VERSION "HNNBNNNYNNNNNNNNNNNNNNNNNNNNNNNNNNNNNNNNNN/4/%%%/4/'%**4NNN///"

NS_ :

BS_:

BU_: AWC BAP_Tester BMC_MLBevo BMS_MV BMS_NV DCDC_800V_PAG DCDC_HV DCDC_HV_02 DCDC_IHEV FCU_MLBevo_FCEV Gateway Gateway_PAG Ladegeraet_2 Ladegeraet_Konzern LE1 LE2 LE2_3_MLBevo_LB LE_MLBevo LE_MLBevo_LB Sub_Gateway TME

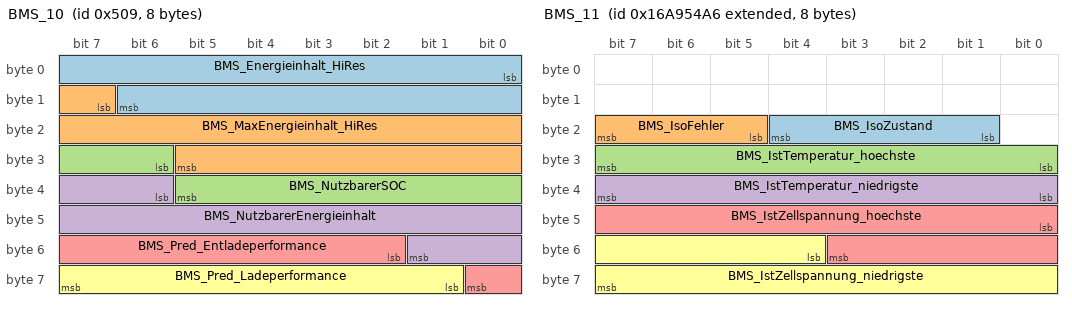
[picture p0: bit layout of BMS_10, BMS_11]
BO_ 1289 BMS_10: 8 BMC_MLBevo
 SG_ BMS_Energieinhalt_HiRes : 0|15@1+ (4,0) [0|131060] "Unit_WattHour"  Gateway,Gateway_PAG,Sub_Gateway
 SG_ BMS_MaxEnergieinhalt_HiRes : 15|15@1+ (4,0) [0|131060] "Unit_WattHour"  Gateway,Gateway_PAG,Sub_Gateway
 SG_ BMS_NutzbarerSOC : 30|8@1+ (0.5,0) [0|100] "Unit_PerCent"  Gateway,Gateway_PAG,Ladegeraet_Konzern,Sub_Gateway,TME
 SG_ BMS_NutzbarerEnergieinhalt : 38|12@1+ (25,0) [0|102325] "Unit_WattHour"  Gateway,Gateway_PAG,Sub_Gateway
 SG_ BMS_Pred_Entladeperformance : 50|7@1+ (1,0) [0|100] "Unit_PerCent"  Gateway,Gateway_PAG,Sub_Gateway
 SG_ BMS_Pred_Ladeperformance : 57|7@1+ (1,0) [0|100] "Unit_PerCent"  Gateway,Gateway_PAG,Sub_Gateway

BO_ 2527679654 BMS_11: 8 BMC_MLBevo
 SG_ BMS_IsoZustand : 17|4@1+ (1,0) [0|15] ""  Gateway,Gateway_PAG,Sub_Gateway
 SG_ BMS_IsoFehler : 21|3@1+ (1,0) [0|7] ""  Gateway,Gateway_PAG,Sub_Gateway
 SG_ BMS_IstTemperatur_hoechste : 24|8@1+ (0.5,-40) [-40|86] "Unit_DegreCelsi"  Gateway,Gateway_PAG,Ladegeraet_Konzern,Sub_Gateway,TME
 SG_ BMS_IstTemperatur_niedrigste : 32|8@1+ (0.5,-40) [-40|86] "Unit_DegreCelsi"  Gateway,Gateway_PAG,Ladegeraet_Konzern,Sub_Gateway,TME
 SG_ BMS_IstZellspannung_hoechste : 40|12@1+ (1,1000) [1000|5091] "Unit_MilliVolt"  Gateway,Gateway_PAG,Ladegeraet_Konzern,Sub_Gateway
 SG_ BMS_IstZellspannung_niedrigste : 52|12@1+ (1,1000) [1000|5091] "Unit_MilliVolt"  Gateway,Gateway_PAG,Ladegeraet_Konzern,Sub_Gateway

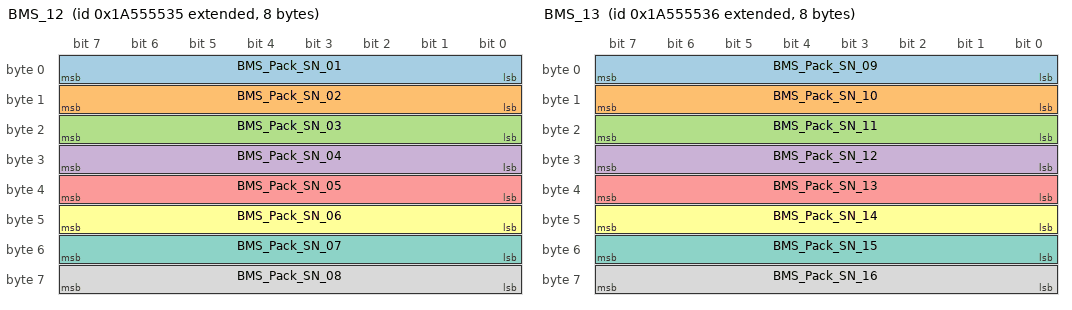
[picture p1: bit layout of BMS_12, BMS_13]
BO_ 2589283637 BMS_12: 8 BMC_MLBevo
 SG_ BMS_Pack_SN_01 : 0|8@1+ (1,0) [0|255] ""  Gateway,Gateway_PAG,Sub_Gateway
 SG_ BMS_Pack_SN_02 : 8|8@1+ (1,0) [0|255] ""  Gateway,Gateway_PAG,Sub_Gateway
 SG_ BMS_Pack_SN_03 : 16|8@1+ (1,0) [0|255] ""  Gateway,Gateway_PAG,Sub_Gateway
 SG_ BMS_Pack_SN_04 : 24|8@1+ (1,0) [0|255] ""  Gateway,Gateway_PAG,Sub_Gateway
 SG_ BMS_Pack_SN_05 : 32|8@1+ (1,0) [0|255] ""  Gateway,Gateway_PAG,Sub_Gateway
 SG_ BMS_Pack_SN_06 : 40|8@1+ (1,0) [0|255] ""  Gateway,Gateway_PAG,Sub_Gateway
 SG_ BMS_Pack_SN_07 : 48|8@1+ (1,0) [0|255] ""  Gateway,Gateway_PAG,Sub_Gateway
 SG_ BMS_Pack_SN_08 : 56|8@1+ (1,0) [0|255] ""  Gateway,Gateway_PAG,Sub_Gateway

BO_ 2589283638 BMS_13: 8 BMC_MLBevo
 SG_ BMS_Pack_SN_09 : 0|8@1+ (1,0) [0|255] ""  Gateway,Gateway_PAG,Sub_Gateway
 SG_ BMS_Pack_SN_10 : 8|8@1+ (1,0) [0|255] ""  Gateway,Gateway_PAG,Sub_Gateway
 SG_ BMS_Pack_SN_11 : 16|8@1+ (1,0) [0|255] ""  Gateway,Gateway_PAG,Sub_Gateway
 SG_ BMS_Pack_SN_12 : 24|8@1+ (1,0) [0|255] ""  Gateway,Gateway_PAG,Sub_Gateway
 SG_ BMS_Pack_SN_13 : 32|8@1+ (1,0) [0|255] ""  Gateway,Gateway_PAG,Sub_Gateway
 SG_ BMS_Pack_SN_14 : 40|8@1+ (1,0) [0|255] ""  Gateway,Gateway_PAG,Sub_Gateway
 SG_ BMS_Pack_SN_15 : 48|8@1+ (1,0) [0|255] ""  Gateway,Gateway_PAG,Sub_Gateway
 SG_ BMS_Pack_SN_16 : 56|8@1+ (1,0) [0|255] ""  Sub_Gateway

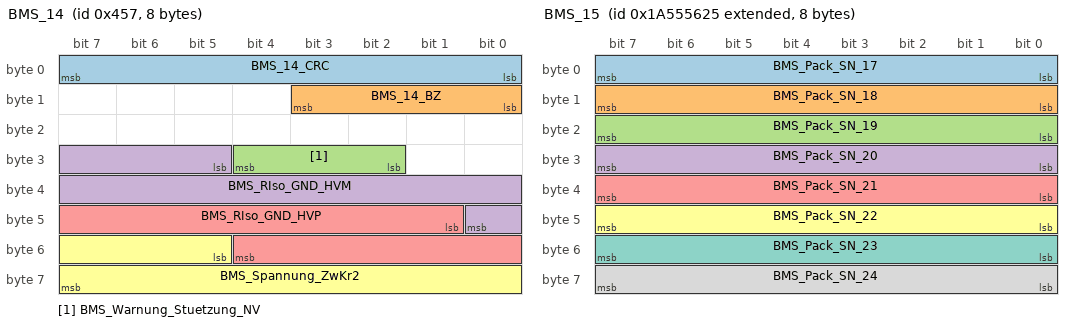
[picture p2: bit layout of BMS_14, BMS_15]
BO_ 1111 BMS_14: 8 BMC_MLBevo
 SG_ BMS_14_CRC : 0|8@1+ (1,0) [0|255] ""  Gateway,Gateway_PAG,LE2
 SG_ BMS_14_BZ : 8|4@1+ (1,0) [0|15] ""  Gateway,Gateway_PAG,LE2
 SG_ BMS_Warnung_Stuetzung_NV : 26|3@1+ (1,0) [0|7] ""  Gateway,Gateway_PAG
 SG_ BMS_RIso_GND_HVM : 29|12@1+ (5,-20465) [-20465|0] "Unit_KiloOhm"  DCDC_HV_02,Gateway,Gateway_PAG
 SG_ BMS_RIso_GND_HVP : 41|12@1+ (5,0) [0|20465] "Unit_KiloOhm"  DCDC_HV_02,Gateway,Gateway_PAG
 SG_ BMS_Spannung_ZwKr2 : 53|11@1+ (0.5,0) [0|1022.5] "Unit_Volt"  Gateway,Gateway_PAG,LE2,TME

BO_ 2589283877 BMS_15: 8 BMC_MLBevo
 SG_ BMS_Pack_SN_17 : 0|8@1+ (1,0) [0|255] ""  Sub_Gateway
 SG_ BMS_Pack_SN_18 : 8|8@1+ (1,0) [0|255] ""  Sub_Gateway
 SG_ BMS_Pack_SN_19 : 16|8@1+ (1,0) [0|255] ""  Sub_Gateway
 SG_ BMS_Pack_SN_20 : 24|8@1+ (1,0) [0|255] ""  Sub_Gateway
 SG_ BMS_Pack_SN_21 : 32|8@1+ (1,0) [0|255] ""  Sub_Gateway
 SG_ BMS_Pack_SN_22 : 40|8@1+ (1,0) [0|255] ""  Sub_Gateway
 SG_ BMS_Pack_SN_23 : 48|8@1+ (1,0) [0|255] ""  Sub_Gateway
 SG_ BMS_Pack_SN_24 : 56|8@1+ (1,0) [0|255] ""  Sub_Gateway

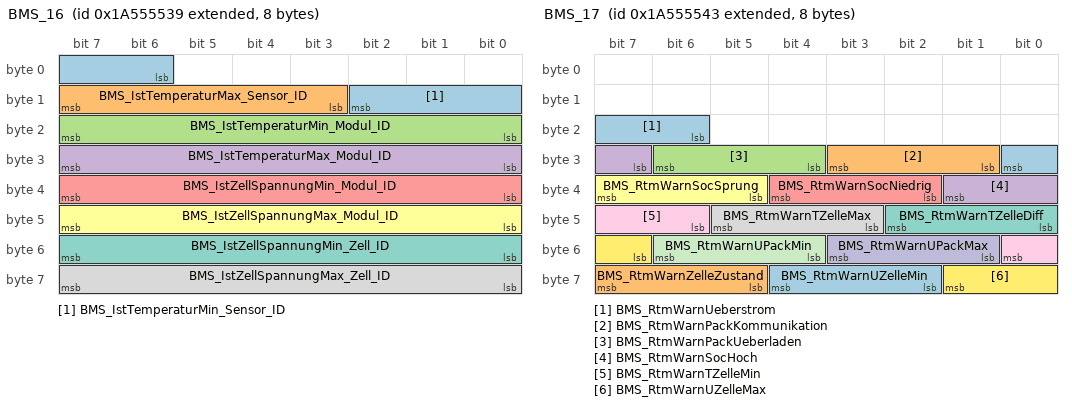
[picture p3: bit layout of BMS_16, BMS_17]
BO_ 2589283641 BMS_16: 8 BMC_MLBevo
 SG_ BMS_IstTemperaturMin_Sensor_ID : 6|5@1+ (1,0) [1|30] ""  Gateway,Gateway_PAG,Ladegeraet_Konzern,Sub_Gateway
 SG_ BMS_IstTemperaturMax_Sensor_ID : 11|5@1+ (1,0) [1|30] ""  Gateway,Gateway_PAG,Ladegeraet_Konzern,Sub_Gateway
 SG_ BMS_IstTemperaturMin_Modul_ID : 16|8@1+ (1,0) [1|254] ""  Gateway,Gateway_PAG,Ladegeraet_Konzern,Sub_Gateway
 SG_ BMS_IstTemperaturMax_Modul_ID : 24|8@1+ (1,0) [1|254] ""  Gateway,Gateway_PAG,Ladegeraet_Konzern,Sub_Gateway
 SG_ BMS_IstZellSpannungMin_Modul_ID : 32|8@1+ (1,0) [1|254] ""  Gateway,Gateway_PAG,Ladegeraet_Konzern,Sub_Gateway
 SG_ BMS_IstZellSpannungMax_Modul_ID : 40|8@1+ (1,0) [1|254] ""  Gateway,Gateway_PAG,Ladegeraet_Konzern,Sub_Gateway
 SG_ BMS_IstZellSpannungMin_Zell_ID : 48|8@1+ (1,0) [1|254] ""  Gateway,Gateway_PAG,Ladegeraet_Konzern,Sub_Gateway
 SG_ BMS_IstZellSpannungMax_Zell_ID : 56|8@1+ (1,0) [1|254] ""  Gateway,Gateway_PAG,Ladegeraet_Konzern,Sub_Gateway

BO_ 2589283651 BMS_17: 8 BMC_MLBevo
 SG_ BMS_RtmWarnUeberstrom : 22|3@1+ (1,0) [0|7] ""  Gateway,Gateway_PAG,Sub_Gateway
 SG_ BMS_RtmWarnPackKommunikation : 25|3@1+ (1,0) [0|7] ""  Gateway,Gateway_PAG,Sub_Gateway
 SG_ BMS_RtmWarnPackUeberladen : 28|3@1+ (1,0) [0|7] ""  Gateway,Gateway_PAG,Sub_Gateway
 SG_ BMS_RtmWarnSocHoch : 31|3@1+ (1,0) [0|7] ""  Gateway,Gateway_PAG,Sub_Gateway
 SG_ BMS_RtmWarnSocNiedrig : 34|3@1+ (1,0) [0|7] ""  Gateway,Gateway_PAG,Sub_Gateway
 SG_ BMS_RtmWarnSocSprung : 37|3@1+ (1,0) [0|7] ""  Gateway,Gateway_PAG,Sub_Gateway
 SG_ BMS_RtmWarnTZelleDiff : 40|3@1+ (1,0) [0|7] ""  Gateway,Gateway_PAG,Sub_Gateway
 SG_ BMS_RtmWarnTZelleMax : 43|3@1+ (1,0) [0|7] ""  Gateway,Gateway_PAG,Sub_Gateway
 SG_ BMS_RtmWarnTZelleMin : 46|3@1+ (1,0) [0|7] ""  Gateway,Gateway_PAG,Sub_Gateway
 SG_ BMS_RtmWarnUPackMax : 49|3@1+ (1,0) [0|7] ""  Gateway,Gateway_PAG,Sub_Gateway
 SG_ BMS_RtmWarnUPackMin : 52|3@1+ (1,0) [0|7] ""  Gateway,Gateway_PAG,Sub_Gateway
 SG_ BMS_RtmWarnUZelleMax : 55|3@1+ (1,0) [0|7] ""  Gateway,Gateway_PAG,Sub_Gateway
 SG_ BMS_RtmWarnUZelleMin : 58|3@1+ (1,0) [0|7] ""  Gateway,Gateway_PAG,Sub_Gateway
 SG_ BMS_RtmWarnZelleZustand : 61|3@1+ (1,0) [0|7] ""  Gateway,Gateway_PAG,Sub_Gateway

BO_ 2589283652 BMS_18: 8 BMC_MLBevo
 SG_ BMS_Energie_Entladung : 32|16@1+ (0.01,0) [0|655.33] "Unit_KiloWattHour"  Gateway,Gateway_PAG
 SG_ BMS_Energie_Ladung : 48|16@1+ (0.01,0) [0|655.33] "Unit_KiloWattHour"  Gateway,Gateway_PAG

BO_ 2589283878 BMS_19: 8 BMC_MLBevo
 SG_ BMS_Pack_SN_25 : 0|8@1+ (1,0) [0|255] ""  Sub_Gateway
 SG_ BMS_Pack_SN_26 : 8|8@1+ (1,0) [0|255] ""  Sub_Gateway

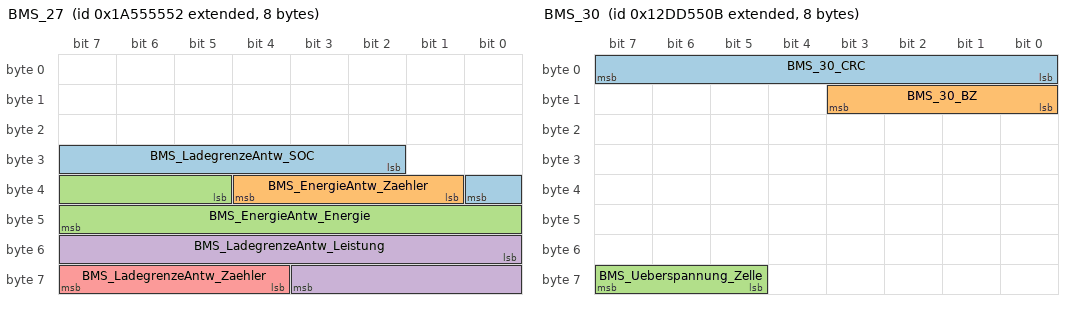
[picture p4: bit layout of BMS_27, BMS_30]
BO_ 2589283666 BMS_27: 8 BMC_MLBevo
 SG_ BMS_LadegrenzeAntw_SOC : 26|7@1+ (1,0) [0|100] "Unit_PerCent"  Gateway_PAG,Ladegeraet_Konzern
 SG_ BMS_EnergieAntw_Zaehler : 33|4@1+ (1,0) [0|13] "Unit_None"  Gateway_PAG,Ladegeraet_Konzern
 SG_ BMS_EnergieAntw_Energie : 37|11@1+ (250,0) [0|511250] "Unit_WattHour"  Gateway_PAG,Ladegeraet_Konzern
 SG_ BMS_LadegrenzeAntw_Leistung : 48|12@1+ (200,0) [0|818600] "Unit_Watt"  Gateway_PAG,Ladegeraet_Konzern
 SG_ BMS_LadegrenzeAntw_Zaehler : 60|4@1+ (1,0) [0|13] "Unit_None"  Gateway_PAG,Ladegeraet_Konzern

BO_ 2463978763 BMS_30: 8 BMC_MLBevo
 SG_ BMS_30_CRC : 0|8@1+ (1,0) [0|255] ""  Gateway,Gateway_PAG
 SG_ BMS_30_BZ : 8|4@1+ (1,0) [0|15] ""  Gateway,Gateway_PAG
 SG_ BMS_Ueberspannung_Zelle : 61|3@1+ (1,0) [0|7] ""  Gateway,Gateway_PAG

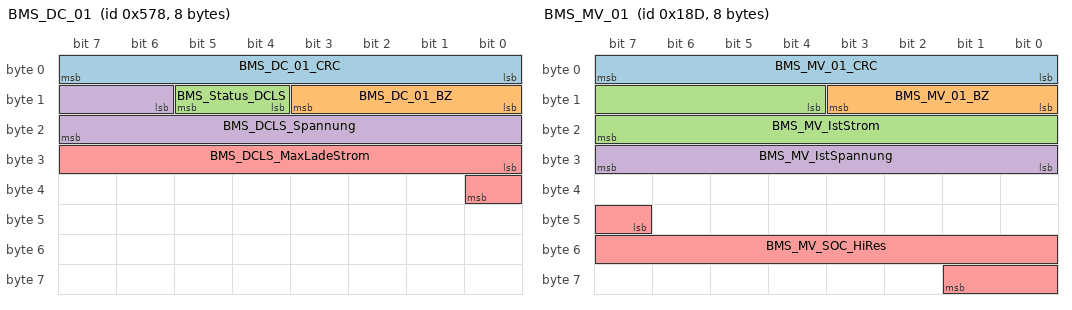
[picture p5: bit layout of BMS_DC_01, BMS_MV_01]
BO_ 1400 BMS_DC_01: 8 BMC_MLBevo
 SG_ BMS_DC_01_CRC : 0|8@1+ (1,0) [0|255] ""  Ladegeraet_Konzern
 SG_ BMS_DC_01_BZ : 8|4@1+ (1,0) [0|15] ""  Ladegeraet_Konzern
 SG_ BMS_Status_DCLS : 12|2@1+ (1,0) [0|3] ""  Ladegeraet_Konzern
 SG_ BMS_DCLS_Spannung : 14|10@1+ (1,0) [0|1021] "Unit_Volt"  Ladegeraet_Konzern
 SG_ BMS_DCLS_MaxLadeStrom : 24|9@1+ (1,0) [0|400] "Unit_Amper"  Ladegeraet_Konzern

BO_ 397 BMS_MV_01: 8 Vector__XXX
 SG_ BMS_MV_01_CRC : 0|8@1+ (1,0) [0|255] ""  Gateway,Gateway_PAG
 SG_ BMS_MV_01_BZ : 8|4@1+ (1,0) [0|15] ""  Gateway,Gateway_PAG
 SG_ BMS_MV_IstStrom : 12|12@1+ (1,-2047) [-2047|2046] "Unit_Amper"  DCDC_IHEV,Gateway,Gateway_PAG
 SG_ BMS_MV_IstSpannung : 24|8@1+ (0.25,0) [0|63.25] "Unit_Volt"  DCDC_IHEV,Gateway,Gateway_PAG
 SG_ BMS_MV_SOC_HiRes : 47|11@1+ (0.05,0) [0|100] "Unit_PerCent"  Gateway,Gateway_PAG

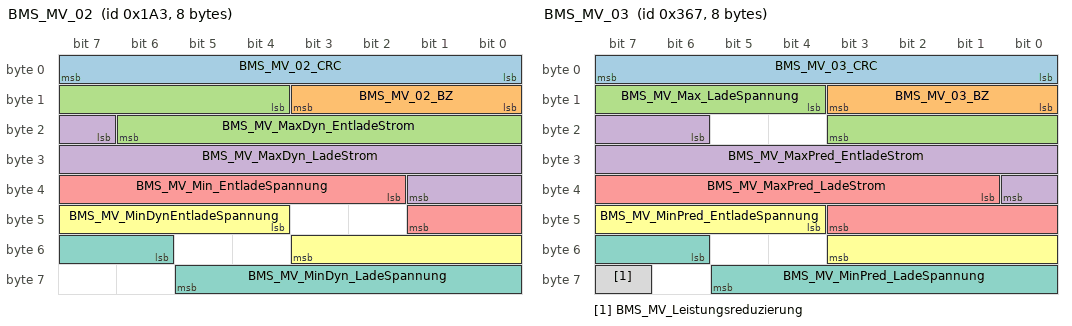
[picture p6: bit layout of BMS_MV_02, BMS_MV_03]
BO_ 419 BMS_MV_02: 8 Vector__XXX
 SG_ BMS_MV_02_CRC : 0|8@1+ (1,0) [0|255] ""  Gateway,Gateway_PAG
 SG_ BMS_MV_02_BZ : 8|4@1+ (1,0) [0|15] ""  Gateway,Gateway_PAG
 SG_ BMS_MV_MaxDyn_EntladeStrom : 12|11@1+ (1,0) [0|2045] "Unit_Amper"  DCDC_IHEV,Gateway,Gateway_PAG
 SG_ BMS_MV_MaxDyn_LadeStrom : 23|11@1+ (1,0) [0|2045] "Unit_Amper"  Gateway,Gateway_PAG
 SG_ BMS_MV_Min_EntladeSpannung : 34|8@1+ (0.25,0) [0|63.25] "Unit_Volt"  Gateway,Gateway_PAG
 SG_ BMS_MV_MinDynEntladeSpannung : 44|8@1+ (0.25,0) [0|63.25] "Unit_Volt"  Gateway,Gateway_PAG
 SG_ BMS_MV_MinDyn_LadeSpannung : 54|8@1+ (0.25,0) [0|63.25] "Unit_Volt"  Gateway,Gateway_PAG

BO_ 871 BMS_MV_03: 8 Vector__XXX
 SG_ BMS_MV_03_CRC : 0|8@1+ (1,0) [0|255] ""  Gateway,Gateway_PAG
 SG_ BMS_MV_03_BZ : 8|4@1+ (1,0) [0|15] ""  Gateway,Gateway_PAG
 SG_ BMS_MV_Max_LadeSpannung : 12|8@1+ (0.25,0) [0|63.25] "Unit_Volt"  Gateway,Gateway_PAG
 SG_ BMS_MV_MaxPred_EntladeStrom : 22|11@1+ (1,0) [0|2045] "Unit_Amper"  Gateway,Gateway_PAG
 SG_ BMS_MV_MaxPred_LadeStrom : 33|11@1+ (1,0) [0|2045] "Unit_Amper"  Gateway,Gateway_PAG
 SG_ BMS_MV_MinPred_EntladeSpannung : 44|8@1+ (0.25,0) [0|63.25] "Unit_Volt"  Gateway,Gateway_PAG
 SG_ BMS_MV_MinPred_LadeSpannung : 54|8@1+ (0.25,0) [0|63.25] "Unit_Volt"  Gateway,Gateway_PAG
 SG_ BMS_MV_Leistungsreduzierung : 63|1@1+ (1,0) [0|1] ""  Gateway,Gateway_PAG

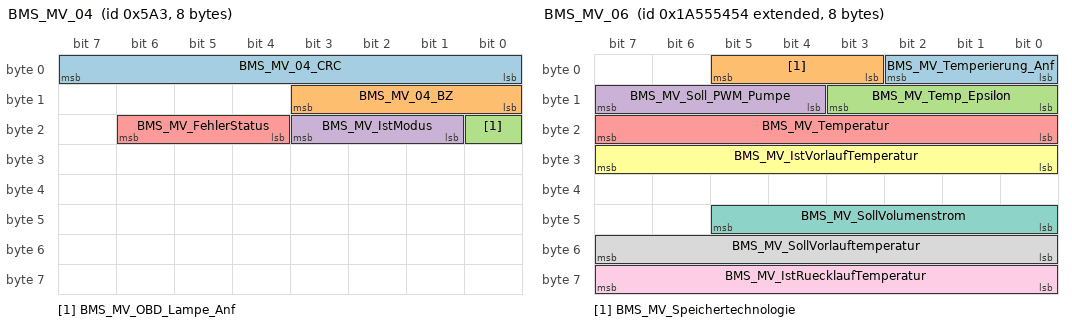
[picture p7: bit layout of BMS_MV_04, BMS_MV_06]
BO_ 1443 BMS_MV_04: 8 Vector__XXX
 SG_ BMS_MV_04_CRC : 0|8@1+ (1,0) [0|255] ""  Gateway,Gateway_PAG
 SG_ BMS_MV_04_BZ : 8|4@1+ (1,0) [0|15] ""  Gateway,Gateway_PAG
 SG_ BMS_MV_OBD_Lampe_Anf : 16|1@1+ (1,0) [0|1] ""  Gateway,Gateway_PAG
 SG_ BMS_MV_IstModus : 17|3@1+ (1,0) [0|7] ""  DCDC_IHEV,Gateway,Gateway_PAG
 SG_ BMS_MV_FehlerStatus : 20|3@1+ (1,0) [0|7] ""  Gateway,Gateway_PAG

BO_ 2589283412 BMS_MV_06: 8 Vector__XXX
 SG_ BMS_MV_Temperierung_Anf : 0|3@1+ (1,0) [0|7] ""  Gateway,Gateway_PAG,TME
 SG_ BMS_MV_Speichertechnologie : 3|3@1+ (1,0) [0|7] ""  Gateway,Gateway_PAG
 SG_ BMS_MV_Temp_Epsilon : 8|4@1+ (1,-15) [-15|0] "Unit_DegreCelsi"  Gateway,Gateway_PAG,TME
 SG_ BMS_MV_Soll_PWM_Pumpe : 12|4@1+ (10,0) [0|100] "Unit_PerCent"  Gateway,Gateway_PAG,TME
 SG_ BMS_MV_Temperatur : 16|8@1+ (0.5,-40) [-40|86.5] "Unit_DegreCelsi"  DCDC_IHEV,Gateway,Gateway_PAG,TME
 SG_ BMS_MV_IstVorlaufTemperatur : 24|8@1+ (0.5,-40) [-40|86.5] "Unit_DegreCelsi"  Gateway,Gateway_PAG,TME
 SG_ BMS_MV_SollVolumenstrom : 40|6@1+ (1,0) [0|61] ""  Gateway,Gateway_PAG,TME
 SG_ BMS_MV_SollVorlauftemperatur : 48|8@1+ (0.5,-40) [-40|86.5] "Unit_DegreCelsi"  Gateway,Gateway_PAG,TME
 SG_ BMS_MV_IstRuecklaufTemperatur : 56|8@1+ (0.5,-40) [-40|86.5] "Unit_DegreCelsi"  Gateway,Gateway_PAG,TME

BO_ 2589283608 BMS_MV_07: 8 Vector__XXX
 SG_ BMS_MV_Energieinhalt : 12|11@1+ (1,0) [0|2045] "Unit_WattHour"  Gateway,Gateway_PAG
 SG_ BMS_MV_MaxEnergieinhalt : 32|11@1+ (1,0) [0|2045] "Unit_WattHour"  Gateway,Gateway_PAG

BO_ 2589283606 BMS_MV_09: 8 Vector__XXX
 SG_ BMS_MV_SOC_Kaltstart : 43|11@1+ (0.05,0) [0|100] "Unit_PerCent"  Gateway,Gateway_PAG
 SG_ BMS_MV_max_Grenz_SOC : 54|5@1+ (1,70) [70|100] "Unit_PerCent"  Gateway,Gateway_PAG

BO_ 1021 BMS_MV_10: 8 Vector__XXX
 SG_ BMS_MV_Pred_Entladeperformance : 50|7@1+ (1,0) [0|100] "Unit_PerCent"  Gateway,Gateway_PAG
 SG_ BMS_MV_Pred_Ladeperformance : 57|7@1+ (1,0) [0|100] "Unit_PerCent"  Gateway,Gateway_PAG

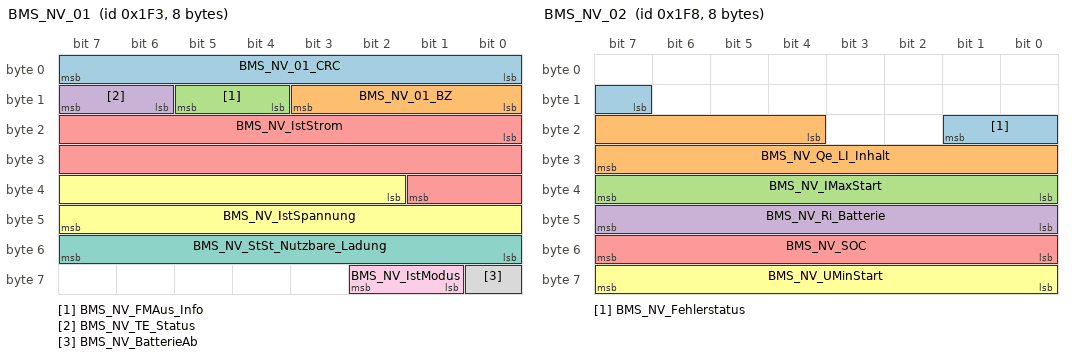
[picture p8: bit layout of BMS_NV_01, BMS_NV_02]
BO_ 499 BMS_NV_01: 8 BMS_NV
 SG_ BMS_NV_01_CRC : 0|8@1+ (1,0) [0|255] ""  Gateway,Gateway_PAG
 SG_ BMS_NV_01_BZ : 8|4@1+ (1,0) [0|15] ""  Gateway,Gateway_PAG
 SG_ BMS_NV_FMAus_Info : 12|2@1+ (1,0) [0|3] ""  Gateway,Gateway_PAG
 SG_ BMS_NV_TE_Status : 14|2@1+ (1,0) [0|3] ""  Gateway,Gateway_PAG
 SG_ BMS_NV_IstStrom : 16|18@1+ (0.01,-1300) [-1300|1300] "Unit_Amper"  Gateway,Gateway_PAG
 SG_ BMS_NV_IstSpannung : 34|14@1+ (0.001,4) [4|20.381] "Unit_Volt"  Gateway,Gateway_PAG
 SG_ BMS_NV_StSt_Nutzbare_Ladung : 48|8@1+ (50,0) [0|12650] "Unit_AmperSecon"  Gateway,Gateway_PAG
 SG_ BMS_NV_BatterieAb : 56|1@1+ (1,0) [0|1] ""  Gateway,Gateway_PAG
 SG_ BMS_NV_IstModus : 57|2@1+ (1,0) [0|3] ""  Gateway,Gateway_PAG

BO_ 504 BMS_NV_02: 8 BMS_NV
 SG_ BMS_NV_Fehlerstatus : 15|3@1+ (1,0) [0|7] ""  Gateway,Gateway_PAG
 SG_ BMS_NV_Qe_LI_Inhalt : 20|12@1+ (0.01,0) [0|40] "Unit_AmperHour"  Gateway,Gateway_PAG
 SG_ BMS_NV_IMaxStart : 32|8@1+ (4,1) [1|1013] "Unit_Amper"  Gateway,Gateway_PAG
 SG_ BMS_NV_Ri_Batterie : 40|8@1+ (0.2,0) [0|50.6] "Unit_MilliOhm"  Gateway,Gateway_PAG
 SG_ BMS_NV_SOC : 48|8@1+ (0.4,0) [0|100] "Unit_PerCent"  Gateway,Gateway_PAG
 SG_ BMS_NV_UMinStart : 56|8@1+ (0.05,2) [2|14.65] "Unit_Volt"  Gateway,Gateway_PAG

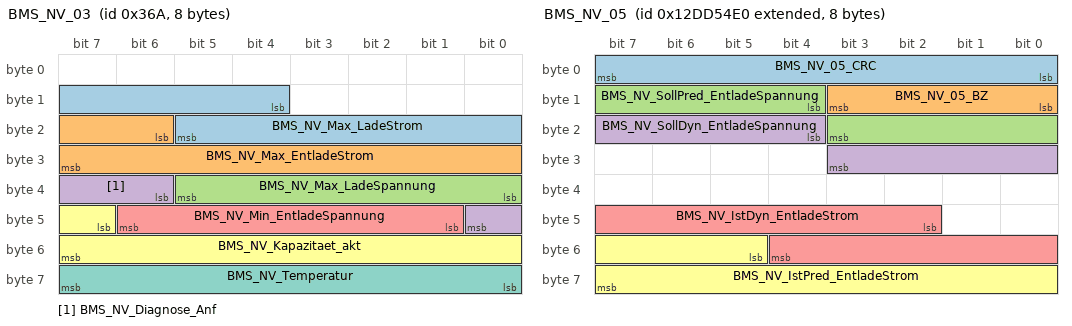
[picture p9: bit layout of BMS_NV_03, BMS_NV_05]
BO_ 874 BMS_NV_03: 8 BMS_NV
 SG_ BMS_NV_Max_LadeStrom : 12|10@1+ (1,0) [0|850] "Unit_Amper"  Gateway,Gateway_PAG
 SG_ BMS_NV_Max_EntladeStrom : 22|10@1+ (1,0) [0|850] "Unit_Amper"  Gateway,Gateway_PAG
 SG_ BMS_NV_Max_LadeSpannung : 32|6@1+ (0.1,11) [11|17.1] "Unit_Volt"  Gateway,Gateway_PAG
 SG_ BMS_NV_Diagnose_Anf : 38|3@1+ (1,0) [0|7] ""  Gateway,Gateway_PAG
 SG_ BMS_NV_Min_EntladeSpannung : 41|6@1+ (0.1,8) [8|14.1] "Unit_Volt"  Gateway,Gateway_PAG
 SG_ BMS_NV_Kapazitaet_akt : 47|9@1+ (0.1,0) [0|40] "Unit_AmperHour"  Gateway,Gateway_PAG
 SG_ BMS_NV_Temperatur : 56|8@1+ (1,-55) [-55|127] "Unit_DegreCelsi"  Gateway,Gateway_PAG

BO_ 2463978664 BMS_NV_04: 8 BMS_NV
 SG_ BMS_NV_Polspannung : 55|9@1+ (0.01,10.5) [10.5|15.59] "Unit_Volt"  Gateway,Gateway_PAG

BO_ 2463978720 BMS_NV_05: 8 BMS_NV
 SG_ BMS_NV_05_CRC : 0|8@1+ (1,0) [0|255] ""  Gateway,Gateway_PAG
 SG_ BMS_NV_05_BZ : 8|4@1+ (1,0) [0|15] ""  Gateway,Gateway_PAG
 SG_ BMS_NV_SollPred_EntladeSpannung : 12|8@1+ (0.05,4) [4|16.65] "Unit_Volt"  Gateway,Gateway_PAG
 SG_ BMS_NV_SollDyn_EntladeSpannung : 20|8@1+ (0.05,4) [4|16.65] "Unit_Volt"  Gateway,Gateway_PAG
 SG_ BMS_NV_IstDyn_EntladeStrom : 42|11@1+ (1,0) [0|2045] "Unit_Amper"  Gateway,Gateway_PAG
 SG_ BMS_NV_IstPred_EntladeStrom : 53|11@1+ (1,0) [0|2045] "Unit_Amper"  Gateway,Gateway_PAG

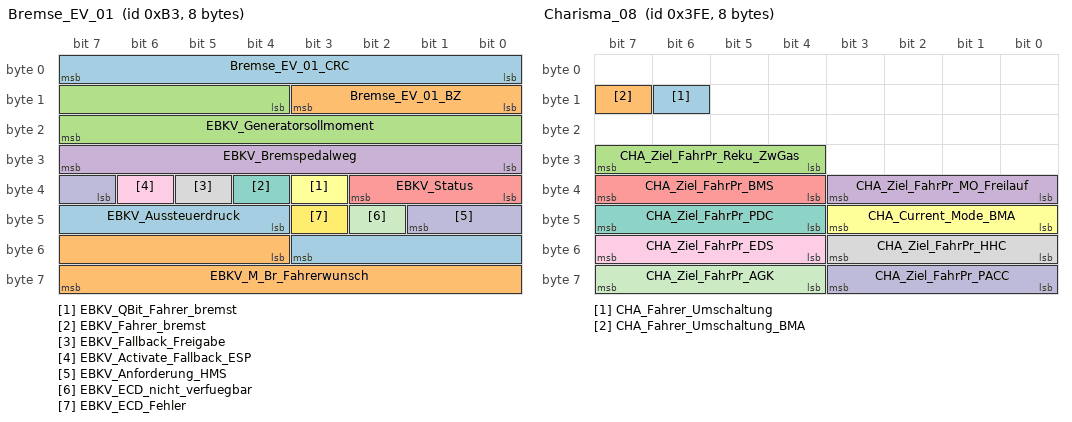
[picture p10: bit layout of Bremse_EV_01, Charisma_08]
BO_ 179 Bremse_EV_01: 8 Gateway
 SG_ Bremse_EV_01_CRC : 0|8@1+ (1,0) [0|255] ""  Sub_Gateway
 SG_ Bremse_EV_01_BZ : 8|4@1+ (1,0) [0|15] ""  Sub_Gateway
 SG_ EBKV_Generatorsollmoment : 12|12@1+ (1.5,0) [0|6120] "Unit_NewtoMeter"  Sub_Gateway
 SG_ EBKV_Bremspedalweg : 24|8@1+ (0.4,-0.4) [0|101.2] "Unit_PerCent"  Sub_Gateway
 SG_ EBKV_Status : 32|3@1+ (1,0) [0|7] ""  Sub_Gateway
 SG_ EBKV_QBit_Fahrer_bremst : 35|1@1+ (1,0) [0|1] ""  Sub_Gateway
 SG_ EBKV_Fahrer_bremst : 36|1@1+ (1,0) [0|1] ""  Sub_Gateway
 SG_ EBKV_Fallback_Freigabe : 37|1@1+ (1,0) [0|1] ""  Sub_Gateway
 SG_ EBKV_Activate_Fallback_ESP : 38|1@1+ (1,0) [0|1] ""  Sub_Gateway
 SG_ EBKV_Anforderung_HMS : 39|3@1+ (1,0) [0|7] ""  Sub_Gateway
 SG_ EBKV_ECD_nicht_verfuegbar : 42|1@1+ (1,0) [0|1] ""  Sub_Gateway
 SG_ EBKV_ECD_Fehler : 43|1@1+ (1,0) [0|1] ""  Sub_Gateway
 SG_ EBKV_Aussteuerdruck : 44|8@1+ (1,0) [0|250] "Unit_Bar"  Sub_Gateway
 SG_ EBKV_M_Br_Fahrerwunsch : 52|12@1+ (4,0) [0|16372] "Unit_NewtoMeter"  Sub_Gateway

BO_ 2617236992 CCP_BMS_CRO_01: 8 Vector__XXX
 SG_ CCP_BMS_CRO_01_Data : 0|64@1+ (1,0) [0|1] ""  BMC_MLBevo

BO_ 2617236993 CCP_BMS_DTO_01: 8 BMC_MLBevo
 SG_ CCP_BMS_DTO_01_Data : 0|64@1+ (1,0) [0|1] "" Vector__XXX

BO_ 2617130752 CCP_DCDC_HV_02_CRO_01: 8 Vector__XXX
 SG_ CCP_DCDC_HV_02_CRO_01_Data : 0|64@1+ (1,0) [0|1.84467440737096E+019] ""  DCDC_HV_02

BO_ 2617130753 CCP_DCDC_HV_02_DTO_01: 8 DCDC_HV_02
 SG_ CCP_DCDC_HV_02_DTO_01_Data : 0|64@1+ (1,0) [0|1.84467440737096E+019] "" Vector__XXX

BO_ 2617194240 CCP_Ladegeraet_2_CRO_01: 8 Vector__XXX
 SG_ CCP_Ladegeraet_2_CRO_01_Data : 0|64@1+ (1,0) [0|1.84467440737096E+019] ""  Ladegeraet_2

BO_ 2617194241 CCP_Ladegeraet_2_DTO_01: 8 Ladegeraet_2
 SG_ CCP_Ladegeraet_2_DTO_01_Data : 0|64@1+ (1,0) [0|1.84467440737096E+019] "" Vector__XXX

BO_ 2617124352 CCP_Ladegeraet_CRO_01: 8 Vector__XXX
 SG_ CCP_Ladegeraet_CRO_01_Data : 0|64@1+ (1,0) [0|1.84467440737096E+019] ""  Ladegeraet_Konzern

BO_ 2617124353 CCP_Ladegeraet_DTO_01: 8 Ladegeraet_Konzern
 SG_ CCP_Ladegeraet_DTO_01_Data : 0|64@1+ (1,0) [0|1.84467440737096E+019] "" Vector__XXX

BO_ 901 Charisma_01: 8 Gateway
 SG_ CHA_Ziel_FahrPr_AGA : 0|4@1+ (1,0) [0|15] "" Vector__XXX
 SG_ CHA_Ziel_FahrPr_ESP : 4|4@1+ (1,0) [0|15] "" Vector__XXX
 SG_ CHA_Ziel_FahrPr_Freilauf : 8|4@1+ (1,0) [0|15] "" Vector__XXX
 SG_ CHA_Fahrer_Umschaltung : 14|1@1+ (1,0) [0|1] "" Vector__XXX
 SG_ CHA_Fahrer_Umschaltung_BMA : 15|1@1+ (1,0) [0|1] "" Vector__XXX
 SG_ CHA_Ziel_FahrPr_MO : 16|4@1+ (1,0) [0|15] "" Vector__XXX
 SG_ CHA_Ziel_FahrPr_GE : 20|4@1+ (1,0) [0|15] "" Vector__XXX
 SG_ CHA_Ziel_FahrPr_ALR : 24|4@1+ (1,0) [0|15] "" Vector__XXX
 SG_ CHA_Ziel_FahrPr_MO_BZS : 28|4@1+ (1,0) [0|15] ""  TME
 SG_ CHA_Ziel_FahrPr_DR : 32|4@1+ (1,0) [0|15] "" Vector__XXX
 SG_ CHA_Ziel_FahrPr_VAQ : 36|4@1+ (1,0) [0|15] "" Vector__XXX
 SG_ CHA_Ziel_FahrPr_AFS : 40|4@1+ (1,0) [0|15] "" Vector__XXX
 SG_ CHA_Ziel_FahrPr_PreCrash : 44|4@1+ (1,0) [0|15] "" Vector__XXX
 SG_ CHA_Ziel_FahrPr_EPS : 48|4@1+ (1,0) [0|15] "" Vector__XXX
 SG_ CHA_Ziel_FahrPr_ACC : 52|4@1+ (1,0) [0|15] "" Vector__XXX
 SG_ CHA_Ziel_FahrPr_SAK : 56|4@1+ (1,0) [0|15] "" Vector__XXX
 SG_ CHA_Ziel_FahrPr_MO_StSt : 60|4@1+ (1,0) [0|15] "" Vector__XXX

BO_ 1022 Charisma_08: 8 Gateway
 SG_ CHA_Fahrer_Umschaltung : 14|1@1+ (1,0) [0|1] "" Vector__XXX
 SG_ CHA_Fahrer_Umschaltung_BMA : 15|1@1+ (1,0) [0|1] "" Vector__XXX
 SG_ CHA_Ziel_FahrPr_Reku_ZwGas : 28|4@1+ (1,0) [0|15] "" Vector__XXX
 SG_ CHA_Ziel_FahrPr_MO_Freilauf : 32|4@1+ (1,0) [0|15] "" Vector__XXX
 SG_ CHA_Ziel_FahrPr_BMS : 36|4@1+ (1,0) [0|15] ""  BMC_MLBevo
 SG_ CHA_Current_Mode_BMA : 40|4@1+ (1,0) [0|15] "" Vector__XXX
 SG_ CHA_Ziel_FahrPr_PDC : 44|4@1+ (1,0) [0|15] "" Vector__XXX
 SG_ CHA_Ziel_FahrPr_HHC : 48|4@1+ (1,0) [0|15] "" Vector__XXX
 SG_ CHA_Ziel_FahrPr_EDS : 52|4@1+ (1,0) [0|15] "" Vector__XXX
 SG_ CHA_Ziel_FahrPr_PACC : 56|4@1+ (1,0) [0|15] "" Vector__XXX
 SG_ CHA_Ziel_FahrPr_AGK : 60|4@1+ (1,0) [0|15] "" Vector__XXX

BO_ 2589283686 DC_MV_CALID_CVN: 8 DCDC_IHEV
 SG_ DC_MV_CALID_CVN_MUX M : 0|2@1+ (1,0) [0|3] "Unit_None" Vector__XXX
 SG_ DC_MV_CVN_VLD : 7|1@1+ (1,0) [0|1] "" Vector__XXX
 SG_ DC_MV_CALID_Index_01 m0 : 8|8@1+ (1,0) [0|255] "" Vector__XXX
 SG_ DC_MV_CALID_Index_05 m1 : 8|8@1+ (1,0) [0|255] "" Vector__XXX
 SG_ DC_MV_CALID_Index_09 m2 : 8|8@1+ (1,0) [0|255] "" Vector__XXX
 SG_ DC_MV_CALID_Index_13 m3 : 8|8@1+ (1,0) [0|255] "" Vector__XXX
 SG_ DC_MV_CALID_Index_02 m0 : 16|8@1+ (1,0) [0|255] "" Vector__XXX
 SG_ DC_MV_CALID_Index_06 m1 : 16|8@1+ (1,0) [0|255] "" Vector__XXX
 SG_ DC_MV_CALID_Index_10 m2 : 16|8@1+ (1,0) [0|255] "" Vector__XXX
 SG_ DC_MV_CALID_Index_14 m3 : 16|8@1+ (1,0) [0|255] "" Vector__XXX
 SG_ DC_MV_CALID_Index_03 m0 : 24|8@1+ (1,0) [0|255] "" Vector__XXX
 SG_ DC_MV_CALID_Index_07 m1 : 24|8@1+ (1,0) [0|255] "" Vector__XXX
 SG_ DC_MV_CALID_Index_11 m2 : 24|8@1+ (1,0) [0|255] "" Vector__XXX
 SG_ DC_MV_CALID_Index_15 m3 : 24|8@1+ (1,0) [0|255] "" Vector__XXX
 SG_ DC_MV_CALID_Index_04 m0 : 32|8@1+ (1,0) [0|255] "" Vector__XXX
 SG_ DC_MV_CALID_Index_08 m1 : 32|8@1+ (1,0) [0|255] "" Vector__XXX
 SG_ DC_MV_CALID_Index_12 m2 : 32|8@1+ (1,0) [0|255] "" Vector__XXX
 SG_ DC_MV_CALID_Index_16 m3 : 32|8@1+ (1,0) [0|255] "" Vector__XXX
 SG_ DC_MV_CVN_Byte_1 m0 : 40|8@1+ (1,0) [0|255] "" Vector__XXX
 SG_ DC_MV_CVN_Byte_2 m1 : 40|8@1+ (1,0) [0|255] "" Vector__XXX
 SG_ DC_MV_CVN_Byte_3 m2 : 40|8@1+ (1,0) [0|255] "" Vector__XXX
 SG_ DC_MV_CVN_Byte_4 m3 : 40|8@1+ (1,0) [0|255] "" Vector__XXX

BO_ 2589283393 DC_MV_Komponentenfehler: 8 DCDC_IHEV
 SG_ DC_MV_Komponentenfehler_01 : 0|2@1+ (1,0) [0|3] "" Vector__XXX
 SG_ DC_MV_Komponentenfehler_02 : 2|2@1+ (1,0) [0|3] "" Vector__XXX
 SG_ DC_MV_Komponentenfehler_03 : 4|2@1+ (1,0) [0|3] "" Vector__XXX
 SG_ DC_MV_Komponentenfehler_04 : 6|2@1+ (1,0) [0|3] "" Vector__XXX
 SG_ DC_MV_Komponentenfehler_05 : 8|2@1+ (1,0) [0|3] "" Vector__XXX
 SG_ DC_MV_Komponentenfehler_06 : 10|2@1+ (1,0) [0|3] "" Vector__XXX
 SG_ DC_MV_Komponentenfehler_07 : 12|2@1+ (1,0) [0|3] "" Vector__XXX
 SG_ DC_MV_Komponentenfehler_08 : 14|2@1+ (1,0) [0|3] "" Vector__XXX
 SG_ DC_MV_Komponentenfehler_09 : 16|2@1+ (1,0) [0|3] "" Vector__XXX
 SG_ DC_MV_Komponentenfehler_10 : 18|2@1+ (1,0) [0|3] "" Vector__XXX
 SG_ DC_MV_Komponentenfehler_11 : 20|2@1+ (1,0) [0|3] "" Vector__XXX
 SG_ DC_MV_Komponentenfehler_12 : 22|2@1+ (1,0) [0|3] "" Vector__XXX
 SG_ DC_MV_Komponentenfehler_13 : 24|2@1+ (1,0) [0|3] "" Vector__XXX
 SG_ DC_MV_Komponentenfehler_14 : 26|2@1+ (1,0) [0|3] "" Vector__XXX
 SG_ DC_MV_Komponentenfehler_15 : 28|2@1+ (1,0) [0|3] "" Vector__XXX
 SG_ DC_MV_Komponentenfehler_16 : 30|2@1+ (1,0) [0|3] "" Vector__XXX
 SG_ DC_MV_Komponentenfehler_17 : 32|2@1+ (1,0) [0|3] "" Vector__XXX
 SG_ DC_MV_Komponentenfehler_18 : 34|2@1+ (1,0) [0|3] "" Vector__XXX
 SG_ DC_MV_Komponentenfehler_19 : 36|2@1+ (1,0) [0|3] "" Vector__XXX
 SG_ DC_MV_Komponentenfehler_20 : 38|2@1+ (1,0) [0|3] "" Vector__XXX
 SG_ DC_MV_Komponentenfehler_21 : 40|2@1+ (1,0) [0|3] "" Vector__XXX
 SG_ DC_MV_Komponentenfehler_22 : 42|2@1+ (1,0) [0|3] "" Vector__XXX
 SG_ DC_MV_Komponentenfehler_23 : 44|2@1+ (1,0) [0|3] "" Vector__XXX
 SG_ DC_MV_Komponentenfehler_24 : 46|2@1+ (1,0) [0|3] "" Vector__XXX
 SG_ DC_MV_Komponentenfehler_25 : 48|2@1+ (1,0) [0|3] "" Vector__XXX
 SG_ DC_MV_Komponentenfehler_26 : 50|2@1+ (1,0) [0|3] "" Vector__XXX
 SG_ DC_MV_Komponentenfehler_27 : 52|2@1+ (1,0) [0|3] "" Vector__XXX
 SG_ DC_MV_Komponentenfehler_28 : 54|2@1+ (1,0) [0|3] "" Vector__XXX
 SG_ DC_MV_Komponentenfehler_29 : 56|2@1+ (1,0) [0|3] "" Vector__XXX
 SG_ DC_MV_Komponentenfehler_30 : 58|2@1+ (1,0) [0|3] "" Vector__XXX
 SG_ DC_MV_Komponentenfehler_31 : 60|2@1+ (1,0) [0|3] "" Vector__XXX
 SG_ DC_MV_Komponentenfehler_VLD : 63|1@1+ (1,0) [0|1] "" Vector__XXX

BO_ 2589283855 DC_MV_Komponentenfehler_02: 8 DCDC_IHEV
 SG_ DC_MV_Komponentenfehler_32 : 0|2@1+ (1,0) [0|3] "" Vector__XXX
 SG_ DC_MV_Komponentenfehler_33 : 2|2@1+ (1,0) [0|3] "" Vector__XXX
 SG_ DC_MV_Komponentenfehler_34 : 4|2@1+ (1,0) [0|3] "" Vector__XXX
 SG_ DC_MV_Komponentenfehler_35 : 6|2@1+ (1,0) [0|3] "" Vector__XXX
 SG_ DC_MV_Komponentenfehler_36 : 8|2@1+ (1,0) [0|3] "" Vector__XXX
 SG_ DC_MV_Komponentenfehler_37 : 10|2@1+ (1,0) [0|3] "" Vector__XXX
 SG_ DC_MV_Komponentenfehler_38 : 12|2@1+ (1,0) [0|3] "" Vector__XXX
 SG_ DC_MV_Komponentenfehler_39 : 14|2@1+ (1,0) [0|3] "" Vector__XXX
 SG_ DC_MV_Komponentenfehler_40 : 16|2@1+ (1,0) [0|3] "" Vector__XXX
 SG_ DC_MV_Komponentenfehler_41 : 18|2@1+ (1,0) [0|3] "" Vector__XXX
 SG_ DC_MV_Komponentenfehler_42 : 20|2@1+ (1,0) [0|3] "" Vector__XXX
 SG_ DC_MV_Komponentenfehler_43 : 22|2@1+ (1,0) [0|3] "" Vector__XXX
 SG_ DC_MV_Komponentenfehler_44 : 24|2@1+ (1,0) [0|3] "" Vector__XXX
 SG_ DC_MV_Komponentenfehler_45 : 26|2@1+ (1,0) [0|3] "" Vector__XXX
 SG_ DC_MV_Komponentenfehler_46 : 28|2@1+ (1,0) [0|3] "" Vector__XXX
 SG_ DC_MV_Komponentenfehler_47 : 30|2@1+ (1,0) [0|3] "" Vector__XXX
 SG_ DC_MV_Komponentenfehler_48 : 32|2@1+ (1,0) [0|3] "" Vector__XXX
 SG_ DC_MV_Komponentenfehler_49 : 34|2@1+ (1,0) [0|3] "" Vector__XXX
 SG_ DC_MV_Komponentenfehler_50 : 36|2@1+ (1,0) [0|3] "" Vector__XXX
 SG_ DC_MV_Komponentenfehler_51 : 38|2@1+ (1,0) [0|3] "" Vector__XXX
 SG_ DC_MV_Komponentenfehler_52 : 40|2@1+ (1,0) [0|3] "" Vector__XXX
 SG_ DC_MV_Komponentenfehler_53 : 42|2@1+ (1,0) [0|3] "" Vector__XXX
 SG_ DC_MV_Komponentenfehler_54 : 44|2@1+ (1,0) [0|3] "" Vector__XXX
 SG_ DC_MV_Komponentenfehler_55 : 46|2@1+ (1,0) [0|3] "" Vector__XXX
 SG_ DC_MV_Komponentenfehler_56 : 48|2@1+ (1,0) [0|3] "" Vector__XXX
 SG_ DC_MV_Komponentenfehler_57 : 50|2@1+ (1,0) [0|3] "" Vector__XXX
 SG_ DC_MV_Komponentenfehler_58 : 52|2@1+ (1,0) [0|3] "" Vector__XXX
 SG_ DC_MV_Komponentenfehler_59 : 54|2@1+ (1,0) [0|3] "" Vector__XXX
 SG_ DC_MV_Komponentenfehler_60 : 56|2@1+ (1,0) [0|3] "" Vector__XXX
 SG_ DC_MV_Komponentenfehler_61 : 58|2@1+ (1,0) [0|3] "" Vector__XXX
 SG_ DC_MV_Komponentenfehler_62 : 60|2@1+ (1,0) [0|3] "" Vector__XXX

BO_TX_BU_ 179 : Gateway,Gateway_PAG;
BO_TX_BU_ 901 : Gateway,Gateway_PAG;
BO_TX_BU_ 1022 : Gateway,Gateway_PAG;
CM_ SG_ 1289 BMS_Energieinhalt_HiRes "aktuell nutzbarer Energieinhalt der HV-Batterie
(bezogen auf ein definiertes mittleres Belastungsprofil)";
CM_ SG_ 1289 BMS_MaxEnergieinhalt_HiRes "maximal nutzbarer Energieinhalt der HV-Batterie
(bezogen auf ein definiertes mittleres Belastungsprofil)";
CM_ SG_ 1289 BMS_NutzbarerSOC "Aktueller relativer Ladezustand der HV-Batterie";
CM_ SG_ 1289 BMS_NutzbarerEnergieinhalt "Restenergieinhalt der Traktionsbatterie, bezogen auf die Betriebsstrategiegrenzen";
CM_ SG_ 1289 BMS_Pred_Entladeperformance "Indikator Stromintegral in Entladerichtung. 
0%     = Start abrampen Peak-Entladestromgrenze auf Dauer-Entladestromgrenze.
100% = Voller Peak-Entladestrom verfügbar";
CM_ SG_ 1289 BMS_Pred_Ladeperformance "Indikator Stromintegral in Laderichtung. 
0%     = Start abrampen Peak-Ladestromgrenze auf Dauer-Ladestromgrenze.
100% = Voller Peak-Ladestrom verfügbar";
CM_ SG_ 2527679654 BMS_IsoZustand "Ergebnis des aktuellen/letzten Isolations-Meßzyklus: Messung läuft; Messung Batterie-intern oder Gesamtsystem; gemessener Wert unterschreitet Schwelle 1 / Schwelle 2.";
CM_ SG_ 2527679654 BMS_IsoFehler "Ergebnis der Isolationsmessung des BMS";
CM_ SG_ 2527679654 BMS_IstTemperatur_hoechste "aktuell höchste Temperatur in der Batterie";
CM_ SG_ 2527679654 BMS_IstTemperatur_niedrigste "aktuell niedrigsteTemperatur in der Batterie";
CM_ SG_ 2527679654 BMS_IstZellspannung_hoechste "höchster Wert aller Zellspannungen im BMS";
CM_ SG_ 2527679654 BMS_IstZellspannung_niedrigste "niedrigster Wert aller Zellspannungen im BMS";
CM_ SG_ 2589283637 BMS_Pack_SN_01 "Seriennummer der HV Batterie, Byte 1, ASCII Codierung";
CM_ SG_ 2589283637 BMS_Pack_SN_02 "Seriennummer der HV Batterie, Byte 2, ASCII Codierung";
CM_ SG_ 2589283637 BMS_Pack_SN_03 "Seriennummer der HV Batterie, Byte 3, ASCII Codierung";
CM_ SG_ 2589283637 BMS_Pack_SN_04 "Seriennummer der HV Batterie, Byte 4, ASCII Codierung";
CM_ SG_ 2589283637 BMS_Pack_SN_05 "Seriennummer der HV Batterie, Byte 5, ASCII Codierung";
CM_ SG_ 2589283637 BMS_Pack_SN_06 "Seriennummer der HV Batterie, Byte 6, ASCII Codierung";
CM_ SG_ 2589283637 BMS_Pack_SN_07 "Seriennummer der HV Batterie, Byte 7, ASCII Codierung";
CM_ SG_ 2589283637 BMS_Pack_SN_08 "Seriennummer der HV Batterie, Byte 8, ASCII Codierung";
CM_ SG_ 2589283638 BMS_Pack_SN_09 "Seriennummer der HV Batterie, Byte 9, ASCII Codierung";
CM_ SG_ 2589283638 BMS_Pack_SN_10 "Seriennummer der HV Batterie, Byte 10, ASCII Codierung";
CM_ SG_ 2589283638 BMS_Pack_SN_11 "Seriennummer der HV Batterie, Byte 11, ASCII Codierung";
CM_ SG_ 2589283638 BMS_Pack_SN_12 "Seriennummer der HV Batterie, Byte 12, ASCII Codierung";
CM_ SG_ 2589283638 BMS_Pack_SN_13 "Seriennummer der HV Batterie, Byte 13, ASCII Codierung";
CM_ SG_ 2589283638 BMS_Pack_SN_14 "Seriennummer der HV Batterie, Byte 14, ASCII Codierung";
CM_ SG_ 2589283638 BMS_Pack_SN_15 "Seriennummer der HV Batterie, Byte 15, ASCII Codierung";
CM_ SG_ 2589283638 BMS_Pack_SN_16 "Seriennummer der HV Batterie, Byte 16, ASCII Codierung";
CM_ SG_ 1111 BMS_14_CRC "Für MLB:
Berechnung siehe Lastenheft 'Kommunikationsabsicherung für FlexRay und CAN'
Ab MQB und MLBevo:
Berechnung siehe Lastenheft 'End-to-End Kommunikationsabsicherung'

Endwerte siehe Begleitdokument 'S-PDU Kennungsfolgen'";
CM_ SG_ 1111 BMS_14_BZ "4bit Botschaftszähler, wird mit jeder Sendebotschaft inkrementiert";
CM_ SG_ 1111 BMS_Warnung_Stuetzung_NV "Warnung an das Energiemanagement zur Verfügbarkeit der sicherheitsrelevanten NV-Stützung.

Bei Stuetzung_iO kann die HV-Batterie zum aktuellen Zeitpunkt für die vorgegebene Dauer die notwendige Leistung/Energie zur Stützung des NV-Systems zur Verfügung ";
CM_ SG_ 1111 BMS_RIso_GND_HVM "Iso-Widerstand
negative Werte = Isowiderstand GND zu HV-
Nur relevant für Fahrzeuge (z.B. PO513/xxx_B) mit HV-Ladebooster (DCDC_HV_02)";
CM_ SG_ 1111 BMS_RIso_GND_HVP "Iso-Widerstand
positive Werte = Isowiderstand GND zu HV+
Nur relevant für Fahrzeuge (z.B. PO513/xxx_B) mit HV-Ladebooster (DCDC_HV_02)";
CM_ SG_ 1111 BMS_Spannung_ZwKr2 "Momentanwert: 
Zweite Zwischenkreisspannung für Batterien mit zwei HV Abgaengen (zwei HV Kreise)
MLBevo PAG:
BMS_Spannung_ZwKr    vordere LE
BMS_Spannung_ZwKr2  hintere LE";
CM_ SG_ 2589283877 BMS_Pack_SN_17 "Seriennummer der HV Batterie, Byte 17, ASCII Codierung";
CM_ SG_ 2589283877 BMS_Pack_SN_18 "Seriennummer der HV Batterie, Byte 18, ASCII Codierung";
CM_ SG_ 2589283877 BMS_Pack_SN_19 "Seriennummer der HV Batterie, Byte 19, ASCII Codierung";
CM_ SG_ 2589283877 BMS_Pack_SN_20 "Seriennummer der HV Batterie, Byte 20, ASCII Codierung";
CM_ SG_ 2589283877 BMS_Pack_SN_21 "Seriennummer der HV Batterie, Byte 21, ASCII Codierung";
CM_ SG_ 2589283877 BMS_Pack_SN_22 "Seriennummer der HV Batterie, Byte 22, ASCII Codierung";
CM_ SG_ 2589283877 BMS_Pack_SN_23 "Seriennummer der HV Batterie, Byte 23, ASCII Codierung";
CM_ SG_ 2589283877 BMS_Pack_SN_24 "Seriennummer der HV Batterie, Byte 24, ASCII Codierung";
CM_ SG_ 2589283641 BMS_IstTemperaturMin_Sensor_ID "RTM-Signal: Nummer (ID) des Sensors (innerhalb des Moduls) mit dem aktuell niedrigsten Temperaturmeßwert";
CM_ SG_ 2589283641 BMS_IstTemperaturMax_Sensor_ID "RTM-Signal: Nummer (ID) des Sensors (innerhalb des Moduls) mit dem aktuell höchsten Temperaturmeßwert";
CM_ SG_ 2589283641 BMS_IstTemperaturMin_Modul_ID "RTM-Signal: Nummer (ID) des Moduls mit dem aktuell niedrigsten Temperaturmeßwert";
CM_ SG_ 2589283641 BMS_IstTemperaturMax_Modul_ID "RTM-Signal: Nummer (ID) des Moduls mit dem aktuell höchsten Temperaturmeßwert";
CM_ SG_ 2589283641 BMS_IstZellSpannungMin_Modul_ID "RTM-Signal: Nummer (ID) des Moduls mit der aktuell niedrigsten Zellspannung";
CM_ SG_ 2589283641 BMS_IstZellSpannungMax_Modul_ID "RTM-Signal: Nummer (ID) des Moduls mit der aktuell höchsten Zellspannung";
CM_ SG_ 2589283641 BMS_IstZellSpannungMin_Zell_ID "RTM-Signal: Nummer (ID) der Zelle (innerhalb des Moduls) mit der aktuell niedrigsten Zellspannung";
CM_ SG_ 2589283641 BMS_IstZellSpannungMax_Zell_ID "RTM-Signal: Nummer (ID) der Zelle (innerhalb des Moduls) mit der aktuell höchsten Zellspannung";
CM_ SG_ 2589283651 BMS_RtmWarnUeberstrom "Real Time Monitor Over-current of overall current of traction battery";
CM_ SG_ 2589283651 BMS_RtmWarnPackKommunikation "Real Time Monitor Traction battery CAN communication fault";
CM_ SG_ 2589283651 BMS_RtmWarnPackUeberladen "RTM Signal Energy-storage over-charging warning";
CM_ SG_ 2589283651 BMS_RtmWarnSocHoch "RTM Signal Excessively-high SOC warning";
CM_ SG_ 2589283651 BMS_RtmWarnSocNiedrig "RTM Signal Low SOC warning";
CM_ SG_ 2589283651 BMS_RtmWarnSocSprung "RTM Signal SOC jump warning";
CM_ SG_ 2589283651 BMS_RtmWarnTZelleDiff "RTM Signal Temperature difference warning";
CM_ SG_ 2589283651 BMS_RtmWarnTZelleMax "RTM Signal Max_temperature_cell_Warning";
CM_ SG_ 2589283651 BMS_RtmWarnTZelleMin "RTM Signal Min_temperature_cell_Warning";
CM_ SG_ 2589283651 BMS_RtmWarnUPackMax "RTM Signal Max_Voltage_of_battery_Warning";
CM_ SG_ 2589283651 BMS_RtmWarnUPackMin "RTM Signal Min_Voltage_of_battery_Warning";
CM_ SG_ 2589283651 BMS_RtmWarnUZelleMax "RTM Signal Max_voltage_cell_Warning";
CM_ SG_ 2589283651 BMS_RtmWarnUZelleMin "RTM Signal Min_voltage_cell_Warning";
CM_ SG_ 2589283651 BMS_RtmWarnZelleZustand "RTM Signal Cell poor-consistency warning";
CM_ SG_ 2589283652 BMS_Energie_Entladung "Energie, welche seit dem letzten Fahrzyklus aus der HV-Batterie entnommen wurde.";
CM_ SG_ 2589283652 BMS_Energie_Ladung "Energie, welche seit dem letzten Fahrzyklus in die HV-Batterie geladen wurde.";
CM_ SG_ 2589283878 BMS_Pack_SN_25 "Seriennummer der HV Batterie, Byte 25, ASCII Codierung";
CM_ SG_ 2589283878 BMS_Pack_SN_26 "Seriennummer der HV Batterie, Byte 26, ASCII Codierung";
CM_ SG_ 2589283666 BMS_LadegrenzeAntw_SOC "SOC-Grenze bis zu welcher mit der Leistung aus BMS_LadegrenzeAntw_Leistung geladen werden kann.";
CM_ SG_ 2589283666 BMS_EnergieAntw_Zaehler "Fortlaufender Zähler für die Antwort Energie.";
CM_ SG_ 2589283666 BMS_EnergieAntw_Energie "Für Laden der HV-Batterie notwendige Energie (um angefragten SOC-Hub zu erreichen).";
CM_ SG_ 2589283666 BMS_LadegrenzeAntw_Leistung "Ladeleistung mit welcher bis zu SOC aus BMS_LadegrenzeAntw_SOC geladen werden kann.";
CM_ SG_ 2589283666 BMS_LadegrenzeAntw_Zaehler "Fortlaufender Zähler für die Antwort Leistung.";
CM_ SG_ 2463978763 BMS_30_CRC "Für MLB:
Berechnung siehe Lastenheft 'Kommunikationsabsicherung für FlexRay und CAN'
Ab MQB und MLBevo:
Berechnung siehe Lastenheft 'End-to-End Kommunikationsabsicherung'

Endwerte siehe Begleitdokument 'S-PDU Kennungsfolgen'";
CM_ SG_ 2463978763 BMS_30_BZ "4bit Botschaftszähler, wird mit jeder Sendebotschaft inkrementiert";
CM_ SG_ 2463978763 BMS_Ueberspannung_Zelle "Anforderung Notabschaltung an HVK aufgrund Überladung";
CM_ SG_ 1400 BMS_DC_01_CRC "Für MLB:
'Berechnung siehe Lastenheft 'Kommunikationsabsicherung für FlexRay und CAN''

Ab MQB und MLBevo:
'Berechnung siehe Lastenheft 'End-to-End Kommunikationsabsicherung''

Endwerte siehe Begleitdokument 'S-PDU Kennungsfolgen'";
CM_ SG_ 1400 BMS_Status_DCLS "Status der Spannungsüberwachung an der DC-Ladeschnittstelle";
CM_ SG_ 1400 BMS_DCLS_Spannung "DC-Spannung der Ladesäule.
Messung zwischen den DC HV-Leitungen.";
CM_ SG_ 1400 BMS_DCLS_MaxLadeStrom "maximaler zulässiger DC-Ladestrom";
CM_ SG_ 397 BMS_MV_01_CRC "Für MLB:
Berechnung siehe Lastenheft 'Kommunikationsabsicherung für FlexRay und CAN'
Ab MQB und MLBevo:
Berechnung siehe Lastenheft 'End-to-End Kommunikationsabsicherung'

Endwerte siehe Begleitdokument 'S-PDU Kennungsfolgen'";
CM_ SG_ 397 BMS_MV_01_BZ "4bit Botschaftszähler, wird mit jeder Sendebotschaft inkrementiert";
CM_ SG_ 397 BMS_MV_IstStrom "Momentanwert: Batteriestrom
Stromrichtung: ein Ladestrom wird mit positiven, ein Entladestrom mit negativen Werten angegeben";
CM_ SG_ 397 BMS_MV_IstSpannung "actual voltage of the battery / Momentanwert: Batteriespannung";
CM_ SG_ 397 BMS_MV_SOC_HiRes "State of Charge / aktueller Ladezustand der Batterie (höhere Auflösung)";
CM_ SG_ 419 BMS_MV_02_CRC "Für MLB:
Berechnung siehe Lastenheft 'Kommunikationsabsicherung für FlexRay und CAN'
Ab MQB und MLBevo:
Berechnung siehe Lastenheft 'End-to-End Kommunikationsabsicherung'

Endwerte siehe Begleitdokument 'S-PDU Kennungsfolgen'";
CM_ SG_ 419 BMS_MV_02_BZ "4bit Botschaftszähler, wird mit jeder Sendebotschaft inkrementiert";
CM_ SG_ 419 BMS_MV_MaxDyn_EntladeStrom "max current (discharge)
maximal zulässiger Entladestrom (zwingend einzuhaltender Grenzwert); Wert ist für eine Dauer von z.B. 1s garantiert";
CM_ SG_ 419 BMS_MV_MaxDyn_LadeStrom "max current (charge)
maximal zulässiger Ladestrom (zwingend einzuhaltender Grenzwert); Wert ist für eine Dauer von z.B.  1s garantiert";
CM_ SG_ 419 BMS_MV_Min_EntladeSpannung "min. voltage / minimal erlaubte Batteriespannung (zwingend einzuhaltender Grenzwert)";
CM_ SG_ 419 BMS_MV_MinDynEntladeSpannung "min. voltage during discharge with current MaxDyn_EntladeStrom resp. iDisChMax / rechnerischer Wert: minimales, für eine Dauer von ~1s garantiertes Spannungsniveau, das unter Belastung mit MaxDyn_EntladeStrom bzw. iDisChMax nicht unterschritten werden wür";
CM_ SG_ 419 BMS_MV_MinDyn_LadeSpannung "min. voltage during charge with current MaxDyn_LadeStrom resp. iChMax / rechnerischer Wert: minimales, für eine Dauer von z.B. 1s garantiertes Spannungsniveau, das unter Belastung mit MaxDyn_LadeStrom bzw. iChMax nicht unterschritten werden würde";
CM_ SG_ 871 BMS_MV_03_CRC "Für MLB:
Berechnung siehe Lastenheft 'Kommunikationsabsicherung für FlexRay und CAN'
Ab MQB und MLBevo:
Berechnung siehe Lastenheft 'End-to-End Kommunikationsabsicherung'

Endwerte siehe Begleitdokument 'S-PDU Kennungsfolgen'";
CM_ SG_ 871 BMS_MV_03_BZ "4bit Botschaftszähler, wird mit jeder Sendebotschaft inkrementiert";
CM_ SG_ 871 BMS_MV_Max_LadeSpannung "max. voltage / maximal erlaubte Batteriespannung (zwingend einzuhaltender Grenzwert)";
CM_ SG_ 871 BMS_MV_MaxPred_EntladeStrom "dynamic el. limit, max. current (discharge) for the specified time (e.g. 10s): and the voltage limit (only for prediction)
rechnerischer Wert: quasistationärer, für eine Dauer von z.B. 10s garantierter maximaler Entladestrom";
CM_ SG_ 871 BMS_MV_MaxPred_LadeStrom "dynamic el. limit, max. current (charge) for the specified time (e.g. 10s), and the voltage limit (only for prediction) 
rechnerischer Wert: quasistationärer, für eine Dauer von z.B. 10s garantierter maximaler Ladestrom";
CM_ SG_ 871 BMS_MV_MinPred_EntladeSpannung "static el. limit, min. battery voltage (e.g. 10s) during current MaxPred_EntladeStrom resp iDisChPredMax / rechnerischer Wert: minimales, für eine Dauer von z.B.  10s garantiertes Spannungsniveau, das unter Belastung mit MaxPred_EntladeStrom bzw. iDisChPr";
CM_ SG_ 871 BMS_MV_MinPred_LadeSpannung "static el. limit, min. battery voltage (e.g. 10s) during current MaxPred_LadeStrom resp. iChPredMax / rechnerischer Wert: minimales, für eine Dauer von z.B. 10s garantiertes Spannungsniveau, das unter Belastung mit MaxPred_LadeStrom bzw. iChPredMax nicht ";
CM_ SG_ 871 BMS_MV_Leistungsreduzierung "Signalisierung der Performanceeinschränkung der 48V Batterie aufgrund hoher Temperatur";
CM_ SG_ 1443 BMS_MV_04_CRC "Für MLB:
Berechnung siehe Lastenheft 'Kommunikationsabsicherung für FlexRay und CAN'
Ab MQB und MLBevo:
Berechnung siehe Lastenheft 'End-to-End Kommunikationsabsicherung'

Endwerte siehe Begleitdokument 'S-PDU Kennungsfolgen'";
CM_ SG_ 1443 BMS_MV_04_BZ "4bit Botschaftszähler, wird mit jeder Sendebotschaft inkrementiert";
CM_ SG_ 1443 BMS_MV_OBD_Lampe_Anf "Anforderung MIL (MalfunctionIndicationLamp) von BMS (Motorsteuergerät reicht diese Info an Kombi weiter).";
CM_ SG_ 1443 BMS_MV_IstModus "actual state of the battery / momentaner Status der Batterie
0: Standby; Kommunikation aktiv
1: Hauptschütze geschlossen / MV-Netz aktiviert / normaler Fahrbetrieb
5: interner Batteriefehler / angeforderter Modus kann nicht eingestellt werden
7: Initi";
CM_ SG_ 1443 BMS_MV_FehlerStatus "aktueller Fehlerstatus der Batterie";
CM_ SG_ 2589283412 BMS_MV_Temperierung_Anf "Temperierungsbedarf der HV-Batterie";
CM_ SG_ 2589283412 BMS_MV_Speichertechnologie "Speichertechnologie des MV-Speichers. Zuordnung zur Technologie in MV FLAH.";
CM_ SG_ 2589283412 BMS_MV_Temp_Epsilon "Das Signal beschreibt die Differenz zwischen Batterie Soll-Temperatur und Batterie Ist-Temperatur.";
CM_ SG_ 2589283412 BMS_MV_Soll_PWM_Pumpe "Fehlende Beschreibung (Import)";
CM_ SG_ 2589283412 BMS_MV_Temperatur "battery temperature / Momentanwert: Temperatur der Traktionsbatterie

Abweichender individueller Init-Wert = 254 (Standardkodierung = 254)";
CM_ SG_ 2589283412 BMS_MV_IstVorlaufTemperatur "Aktuelle Vorlauftemperatur der Batterie

Abweichender individueller Init-Wert = 254 (Standardkodierung = 254)";
CM_ SG_ 2589283412 BMS_MV_SollVolumenstrom "Mindestanforderung des Soll Volumenstrom für Kühlkreislauf Batterie";
CM_ SG_ 2589283412 BMS_MV_SollVorlauftemperatur "Soll_Vorlauftemperatur_Kühlmedium in °C

Abweichender individueller Init-Wert = 254 (Standardkodierung = 254)";
CM_ SG_ 2589283412 BMS_MV_IstRuecklaufTemperatur "Aktuelle Ruecklauftemperatur der Batterie

Abweichender individueller Init-Wert = 254 (Standardkodierung = 254)";
CM_ SG_ 2589283608 BMS_MV_Energieinhalt "aktuell nutzbarer Energieinhalt der MV-Batterie
(bezogen auf ein definiertes mittleres Belastungsprofil)";
CM_ SG_ 2589283608 BMS_MV_MaxEnergieinhalt "maximaler nutzbarer Energieinhalt der MV-Batterie (bezogen auf Last KBI_RWDS_Lastprofil bei SOC=100%)
Abhängig von KBI_RWDS_Lastprofil";
CM_ SG_ 2589283606 BMS_MV_SOC_Kaltstart "Abhängig von der notwendigen Kaltstartleistung berechneter SOC Wert.";
CM_ SG_ 2589283606 BMS_MV_max_Grenz_SOC "oberer Grenz SOC - Betriebsstrategie";
CM_ SG_ 1021 BMS_MV_Pred_Entladeperformance "Indikator Stromintegral in Entladerichtung. 
0%     = Start abrampen Peak-Entladestromgrenze auf Dauer-Entladestromgrenze.
100% = Voller Peak-Entladestrom verfügbar";
CM_ SG_ 1021 BMS_MV_Pred_Ladeperformance "Indikator Stromintegral in Laderichtung. 
0%     = Start abrampen Peak-Ladestromgrenze auf Dauer-Ladestromgrenze.
100% = Voller Peak-Ladestrom verfügbar";
CM_ SG_ 499 BMS_NV_01_CRC "Berechnung siehe Lastenheft 'End-to-End Kommunikationsabsicherung'";
CM_ SG_ 499 BMS_NV_01_BZ "-";
CM_ SG_ 499 BMS_NV_FMAus_Info "Freilauf Informationssignal zum Freilaufkoordinator. 
Gilt nur für die Freilauf Phase. Verwendung im MicroHybrid.";
CM_ SG_ 499 BMS_NV_TE_Status "Garantierte Unterstützung des Zusatzspeichers. Nur bei garantierter Bordnetztstützung des Zusatzspeichers kann in Freilauf-Motor-Aus Phase übergegangen werden. Geht der Zustand von 'Trennelement_geschlossen_Mindestzeit' auf 'Trennelement_geschlossen' blei";
CM_ SG_ 499 BMS_NV_IstStrom "Ausgabe des aktuell gemessenen Stroms des 12V Zusatzspeichers.
negative Werte: Entladestrom bezogen auf den Energiespeicher
positive Werte: Ladestrom bezogen auf den Energiespeicher";
CM_ SG_ 499 BMS_NV_IstSpannung "actual voltage of the battery / Momentanwert: Batteriespannung";
CM_ SG_ 499 BMS_NV_StSt_Nutzbare_Ladung "Energie aus dem Zusatzspeicher, welche für die StartStopp-Funktion in den Stopp-Phasen genutzt wird. Wird berücksichtig zur Bildung des Signals BEM_StartStopp_Info";
CM_ SG_ 499 BMS_NV_BatterieAb "Detektion einer Verbindungsunterbrechung von oder zur Batterie bzw. Funktion der Batterie ist nicht gegeben
- Polunterbrechung
- Bolzen- oder Massekabelunterbrechung
- interne Unterbechung
Funktion bei geschlossenem Trennelement";
CM_ SG_ 499 BMS_NV_IstModus "actual state of the battery / momentaner Status der Batterie
Standby; Kommunikation aktiv
Hauptschütz geschlossen / NV-Netz aktiviert / normaler Fahrbetrieb
interner Batteriefehler / angeforderter Modus kann nicht eingestellt werdenInitialisierung";
CM_ SG_ 504 BMS_NV_Fehlerstatus "aktueller Fehlerstatus der Batterie";
CM_ SG_ 504 BMS_NV_Qe_LI_Inhalt "Bei größer 0 ist ein RSG Start mit den vorgegebenen Strom und Spannungsgrenzen noch möglich";
CM_ SG_ 504 BMS_NV_IMaxStart "Aktuell gemessenes Stromdelta bei aktuellem Spannungseinbruch";
CM_ SG_ 504 BMS_NV_Ri_Batterie "Innenwiderstand in Entladerichtung";
CM_ SG_ 504 BMS_NV_SOC "State of Charge / aktueller Ladezustand der Batterie";
CM_ SG_ 504 BMS_NV_UMinStart "Aktuell gemessener Spannungseinbruch (Minimalwert der Spannung) des letzten Motorstarts ";
CM_ SG_ 874 BMS_NV_Max_LadeStrom "maximal zulässiger Ladestrom";
CM_ SG_ 874 BMS_NV_Max_EntladeStrom "maximal zulässiger Entladestrom";
CM_ SG_ 874 BMS_NV_Max_LadeSpannung "max. voltage / maximal erlaubte Batteriespannung (zwingend einzuhaltender Grenzwert)";
CM_ SG_ 874 BMS_NV_Diagnose_Anf "Wunsch zur Diagnose des Trennelements und Anforderung von Prüfpulsen für BZE";
CM_ SG_ 874 BMS_NV_Min_EntladeSpannung "min. voltage / minimal erlaubte Batteriespannung (zwingend einzuhaltender Grenzwert)";
CM_ SG_ 874 BMS_NV_Kapazitaet_akt "Gesamtenergiekapazitaet der NV-Batterie unter Berücksichtigung der Alterung";
CM_ SG_ 874 BMS_NV_Temperatur "battery temperature / Momentanwert: Temperatur der Batterie";
CM_ SG_ 2463978664 BMS_NV_Polspannung "Spannung gemessen unmittelbar vor den Polen des Speichers";
CM_ SG_ 2463978720 BMS_NV_05_CRC "Für MLB:
Berechnung siehe Lastenheft 'Kommunikationsabsicherung für FlexRay und CAN'
Ab MQB und MLBevo:
Berechnung siehe Lastenheft 'End-to-End Kommunikationsabsicherung'

Endwerte siehe Begleitdokument 'S-PDU Kennungsfolgen'";
CM_ SG_ 2463978720 BMS_NV_05_BZ "4bit Botschaftszähler, wird mit jeder Sendebotschaft inkrementiert";
CM_ SG_ 2463978720 BMS_NV_SollPred_EntladeSpannung "min. voltage during discharge with current BMS_NV_IstPred_EntladeStrom // fester Wert: für eine Dauer von ~18s garantiertes Spannungsniveau, das unter Belastung mit BMS_NV_IstPred_EntladeStrom nicht unterschritten werden würde.";
CM_ SG_ 2463978720 BMS_NV_SollDyn_EntladeSpannung "min. voltage during discharge with current BMS_NV_IstDyn_EntladeStrom // fester Wert: für eine Dauer von ~1s garantiertes Spannungsniveau, das unter Belastung mit BMS_NV_IstDyn_EntladeStrom nicht unterschritten werden würde.";
CM_ SG_ 2463978720 BMS_NV_IstDyn_EntladeStrom "dynamic el. limit, max. current (discharge) for the specified time (e.g. 1s): under consideration of voltage limit (BMS_NV_SollDyn_EntladeSpannung) //
rechnerischer Wert: quasistationärer, für eine Dauer von z.B. 1s garantierter maximaler Entladestrom un";
CM_ SG_ 2463978720 BMS_NV_IstPred_EntladeStrom "prediction el. limit, max. current (discharge) for the specified time (e.g. 18s): under consideration of voltage limit (BMS_NV_SollPred_EntladeSpannung) //
rechnerischer Wert: quasistationärer, für eine Dauer von z.B. 18s garantierter maximaler Entladest";
CM_ BO_ 179 "Schnittstelle EBKV - Motor";
CM_ SG_ 179 Bremse_EV_01_CRC "Für MLB:
'Berechnung siehe Lastenheft 'Kommunikationsabsicherung für FlexRay und CAN''

Ab MQB und MLBevo:
'Berechnung siehe Lastenheft 'End-to-End Kommunikationsabsicherung''

Endwerte siehe Begleitdokument 'S-PDU Kennungsfolgen'";
CM_ SG_ 179 Bremse_EV_01_BZ "Botschaftszähler
Botschaft asynchron geroutet. Zählerwert kann springen.";
CM_ SG_ 179 EBKV_Generatorsollmoment "Sollwert für Modifikation des verfügbaren Generatormoments";
CM_ SG_ 179 EBKV_Bremspedalweg "Bremspedalwert in Prozent. Der Wert ist Nullpunkt-abgeglichen.
Bremspedalweg von der EBKV eingelesen.";
CM_ SG_ 179 EBKV_Status "Status der eBKV";
CM_ SG_ 179 EBKV_QBit_Fahrer_bremst "
";
CM_ SG_ 179 EBKV_Fahrer_bremst "Fahrer will bremsen (Eintreterkennung).
Wird benötigt, um ACC oder GRA abzuschalten.";
CM_ SG_ 179 EBKV_Fallback_Freigabe "Das Signal erteilt die Freigabe auf das Signal EBKV_Activate_FallBack_ESP";
CM_ SG_ 179 EBKV_Activate_Fallback_ESP "Das Signal aktiviert im ESC die Rückfallebene.";
CM_ SG_ 179 EBKV_Anforderung_HMS "Anforderung an dem Haltemanager vom EBKV";
CM_ SG_ 179 EBKV_ECD_nicht_verfuegbar "EBKV kann das vom MSG geforderte Radbremsmoment aktuell  nicht umsetzen (z.B. Netzwerkmanagement-Betriebe - KL15 Aus; ggf. Diagnosezustände, ...). Ohne Fehlereintrag im EBKV, im Zündungslauf reversibel.";
CM_ SG_ 179 EBKV_ECD_Fehler "EBKV hat die Radbremsmomentenschnittstelle zum MSG aufgrund eines Fehlers für den Zündungslauf abgeschaltet. Mit Fehlerspeichereintrag im EBKV.";
CM_ SG_ 179 EBKV_Aussteuerdruck "Das Signal übermittelt seitens des EBKVs frühzeitig den aktuellen, Fahrsituations-abhängig-variablen Brems-Vordruck an das ESC, bei dem die maximale Bremskraftunterstützung des EBVK erreicht ist. 
Über diesen übermittelten Druck-Wert erkennt das ESC den ";
CM_ SG_ 179 EBKV_M_Br_Fahrerwunsch "Fahrer-Gesamt-Wunschbremsmoment (bezogen auf Radebene der Primärachse)";
CM_ BO_ 901 "ab MQB ohne CHK und mit geänderter Sendeart";
CM_ SG_ 901 CHA_Ziel_FahrPr_AGA "Anforderung Ziel-Fahrprogramm AGA/SAK2 (Aussensound)";
CM_ SG_ 901 CHA_Ziel_FahrPr_ESP "Anforderung Ziel-Fahrprogramm ESP";
CM_ SG_ 901 CHA_Ziel_FahrPr_Freilauf "Anforderung Ziel-Fahrprogramm Funktion Freilauf";
CM_ SG_ 901 CHA_Fahrer_Umschaltung "Die manuelle Umschaltung durch den Fahrer soll signalisiert werden, um zu automatischen Umschaltungen (z.B. Retries) differenzieren zu können.";
CM_ SG_ 901 CHA_Fahrer_Umschaltung_BMA "Die manuelle Umschaltung der Betriebsmodusauswahl durch den Fahrer soll signalisiert werden, um zu automatischen Umschaltungen (z.B. Retries) differenzieren zu können.";
CM_ SG_ 901 CHA_Ziel_FahrPr_MO "Anforderung Ziel-Fahrprogramm Motor";
CM_ SG_ 901 CHA_Ziel_FahrPr_GE "Anforderung Ziel-Fahrprogramm Getriebe";
CM_ SG_ 901 CHA_Ziel_FahrPr_ALR "Anforderung Ziel-Fahrprogramm Allrad";
CM_ SG_ 901 CHA_Ziel_FahrPr_MO_BZS "Anforderung Zielfahrprogramm Motor-Betriebszusände";
CM_ SG_ 901 CHA_Ziel_FahrPr_DR "Anforderung Ziel-Fahrprogramm Dämpfer";
CM_ SG_ 901 CHA_Ziel_FahrPr_VAQ "Anforderung Ziel-Fahrprogramm VAQ";
CM_ SG_ 901 CHA_Ziel_FahrPr_AFS "Anforderung Ziel-Fahrprogramm AFS";
CM_ SG_ 901 CHA_Ziel_FahrPr_PreCrash "Anforderung Ziel-Fahrprogramm PreCrash";
CM_ SG_ 901 CHA_Ziel_FahrPr_EPS "Anforderung Ziel-Fahrprogramm Elektrische Lenkhilfe";
CM_ SG_ 901 CHA_Ziel_FahrPr_ACC "MQB
Anforderung Ziel-Fahrprogramm ACC";
CM_ SG_ 901 CHA_Ziel_FahrPr_SAK "Anforderung Ziel-Fahrprogramm Soundaktuator";
CM_ SG_ 901 CHA_Ziel_FahrPr_MO_StSt "Anforderung Ziel-Fahrprogramm Funktion Motor Start-Stopp";
CM_ SG_ 1022 CHA_Fahrer_Umschaltung "Die manuelle Umschaltung durch den Fahrer soll signalisiert werden, um zu automatischen Umschaltungen (z.B. Retries) differenzieren zu können.";
CM_ SG_ 1022 CHA_Fahrer_Umschaltung_BMA "Die manuelle Umschaltung der Betriebsmodusauswahl durch den Fahrer soll signalisiert werden, um zu automatischen Umschaltungen (z.B. Retries) differenzieren zu können.";
CM_ SG_ 1022 CHA_Ziel_FahrPr_Reku_ZwGas "Anforderung Ziel-Fahrprogramm für Rekuperation oder Zwischengas";
CM_ SG_ 1022 CHA_Ziel_FahrPr_MO_Freilauf "Anforderung Ziel-Fahrprogramm Funktion Freilauf Motor aus";
CM_ SG_ 1022 CHA_Ziel_FahrPr_BMS "Anforderung Ziel-Fahrprogramm BMS (nähere Spezifikation siehe Charisma-LH PAG)";
CM_ SG_ 1022 CHA_Current_Mode_BMA "Aktuell eingestellter Charisma Betriebsmodus";
CM_ SG_ 1022 CHA_Ziel_FahrPr_PDC "Signal zur Ansteuerung des PDC/PLA durch den Charisma-Koordinator";
CM_ SG_ 1022 CHA_Ziel_FahrPr_HHC "Anforderung Ziel-Fahrprogramm Hill Hold Control";
CM_ SG_ 1022 CHA_Ziel_FahrPr_EDS "Anforderung Ziel-Fahrprogramm Elektronische Differentialsperre";
CM_ SG_ 1022 CHA_Ziel_FahrPr_PACC "Anforderung Ziel-Fahrprogramm InnoDrive (PACCh)";
CM_ SG_ 1022 CHA_Ziel_FahrPr_AGK "Signal zur Ansteuerung des Teilnehmers Abgasklappen durch den Charisma-Koordinator über das Motor-SG";
CM_ SG_ 2589283686 DC_MV_CALID_CVN_MUX "Alle CALID-Indizes bilden zusammen die CALID";
CM_ SG_ 2589283686 DC_MV_CVN_VLD "Valid-Bit der Calibration-Verification-Number (CVN bzw. Checksumme)";
CM_ SG_ 2589283686 DC_MV_CALID_Index_01 "Software-Calibration-Identification (CALID) im ASCII-Zeichenformat; 
für Ausgabe an das Generic Scan-Tool für OBD in NAR

0x30 entspricht ASCII '0'";
CM_ SG_ 2589283686 DC_MV_CALID_Index_05 "Software-Calibration-Identification (CALID) im ASCII-Zeichenformat; 
für Ausgabe an das Generic Scan-Tool für OBD in NAR

0x30 entspricht ASCII '0'";
CM_ SG_ 2589283686 DC_MV_CALID_Index_09 "Software-Calibration-Identification (CALID) im ASCII-Zeichenformat; 
für Ausgabe an das Generic Scan-Tool für OBD in NAR

0x30 entspricht ASCII '0'";
CM_ SG_ 2589283686 DC_MV_CALID_Index_13 "Software-Calibration-Identification (CALID) im ASCII-Zeichenformat; 
für Ausgabe an das Generic Scan-Tool für OBD in NAR

0x30 entspricht ASCII '0'";
CM_ SG_ 2589283686 DC_MV_CALID_Index_02 "Software-Calibration-Identification (CALID) im ASCII-Zeichenformat; 
für Ausgabe an das Generic Scan-Tool für OBD in NAR

0x30 entspricht ASCII '0'";
CM_ SG_ 2589283686 DC_MV_CALID_Index_06 "Software-Calibration-Identification (CALID) im ASCII-Zeichenformat; 
für Ausgabe an das Generic Scan-Tool für OBD in NAR

0x30 entspricht ASCII '0'";
CM_ SG_ 2589283686 DC_MV_CALID_Index_10 "Software-Calibration-Identification (CALID) im ASCII-Zeichenformat; 
für Ausgabe an das Generic Scan-Tool für OBD in NAR

0x30 entspricht ASCII '0'";
CM_ SG_ 2589283686 DC_MV_CALID_Index_14 "Software-Calibration-Identification (CALID) im ASCII-Zeichenformat; 
für Ausgabe an das Generic Scan-Tool für OBD in NAR

0x30 entspricht ASCII '0'";
CM_ SG_ 2589283686 DC_MV_CALID_Index_03 "Software-Calibration-Identification (CALID) im ASCII-Zeichenformat; 
für Ausgabe an das Generic Scan-Tool für OBD in NAR

0x30 entspricht ASCII '0'";
CM_ SG_ 2589283686 DC_MV_CALID_Index_07 "Software-Calibration-Identification (CALID) im ASCII-Zeichenformat; 
für Ausgabe an das Generic Scan-Tool für OBD in NAR

0x30 entspricht ASCII '0'";
CM_ SG_ 2589283686 DC_MV_CALID_Index_11 "Software-Calibration-Identification (CALID) im ASCII-Zeichenformat; 
für Ausgabe an das Generic Scan-Tool für OBD in NAR

0x30 entspricht ASCII '0'";
CM_ SG_ 2589283686 DC_MV_CALID_Index_15 "Software-Calibration-Identification (CALID) im ASCII-Zeichenformat; 
für Ausgabe an das Generic Scan-Tool für OBD in NAR

0x30 entspricht ASCII '0'";
CM_ SG_ 2589283686 DC_MV_CALID_Index_04 "Software-Calibration-Identification (CALID) im ASCII-Zeichenformat; 
für Ausgabe an das Generic Scan-Tool für OBD in NAR

0x30 entspricht ASCII '0'";
CM_ SG_ 2589283686 DC_MV_CALID_Index_08 "Software-Calibration-Identification (CALID) im ASCII-Zeichenformat; 
für Ausgabe an das Generic Scan-Tool für OBD in NAR

0x30 entspricht ASCII '0'";
CM_ SG_ 2589283686 DC_MV_CALID_Index_12 "Software-Calibration-Identification (CALID) im ASCII-Zeichenformat; 
für Ausgabe an das Generic Scan-Tool für OBD in NAR

0x30 entspricht ASCII '0'";
CM_ SG_ 2589283686 DC_MV_CALID_Index_16 "Software-Calibration-Identification (CALID) im ASCII-Zeichenformat; 
für Ausgabe an das Generic Scan-Tool für OBD in NAR

0x30 entspricht ASCII '0'";
CM_ SG_ 2589283686 DC_MV_CVN_Byte_1 "Calibration Verification Number (CVN bzw. Checksumme) des SW- und Datenstandes; 
für Ausgabe an das Generic Scan-Tool für OBD in NAR";
CM_ SG_ 2589283686 DC_MV_CVN_Byte_2 "Calibration Verification Number (CVN bzw. Checksumme) des SW- und Datenstandes; 
für Ausgabe an das Generic Scan-Tool für OBD in NAR";
CM_ SG_ 2589283686 DC_MV_CVN_Byte_3 "Calibration Verification Number (CVN bzw. Checksumme) des SW- und Datenstandes; 
für Ausgabe an das Generic Scan-Tool für OBD in NAR";
CM_ SG_ 2589283686 DC_MV_CVN_Byte_4 "Calibration Verification Number (CVN bzw. Checksumme) des SW- und Datenstandes; 
für Ausgabe an das Generic Scan-Tool für OBD in NAR";
CM_ SG_ 2589283393 DC_MV_Komponentenfehler_01 "Übertragung OBD relevanter Fehlerpfade vom Secondary zum Primary Steuergerät. 
Zuordnung der generischen Komponentenfehler muss zwischen Sender und Empfänger abgestimmt werden.";
CM_ SG_ 2589283393 DC_MV_Komponentenfehler_02 "Übertragung OBD relevanter Fehlerpfade vom Secondary zum Primary Steuergerät. 
Zuordnung der generischen Komponentenfehler muss zwischen Sender und Empfänger abgestimmt werden.";
CM_ SG_ 2589283393 DC_MV_Komponentenfehler_03 "Übertragung OBD relevanter Fehlerpfade vom Secondary zum Primary Steuergerät. 
Zuordnung der generischen Komponentenfehler muss zwischen Sender und Empfänger abgestimmt werden.";
CM_ SG_ 2589283393 DC_MV_Komponentenfehler_04 "Übertragung OBD relevanter Fehlerpfade vom Secondary zum Primary Steuergerät. 
Zuordnung der generischen Komponentenfehler muss zwischen Sender und Empfänger abgestimmt werden.";
CM_ SG_ 2589283393 DC_MV_Komponentenfehler_05 "Übertragung OBD relevanter Fehlerpfade vom Secondary zum Primary Steuergerät. 
Zuordnung der generischen Komponentenfehler muss zwischen Sender und Empfänger abgestimmt werden.";
CM_ SG_ 2589283393 DC_MV_Komponentenfehler_06 "Übertragung OBD relevanter Fehlerpfade vom Secondary zum Primary Steuergerät. 
Zuordnung der generischen Komponentenfehler muss zwischen Sender und Empfänger abgestimmt werden.";
CM_ SG_ 2589283393 DC_MV_Komponentenfehler_07 "Übertragung OBD relevanter Fehlerpfade vom Secondary zum Primary Steuergerät. 
Zuordnung der generischen Komponentenfehler muss zwischen Sender und Empfänger abgestimmt werden.";
CM_ SG_ 2589283393 DC_MV_Komponentenfehler_08 "Übertragung OBD relevanter Fehlerpfade vom Secondary zum Primary Steuergerät. 
Zuordnung der generischen Komponentenfehler muss zwischen Sender und Empfänger abgestimmt werden.";
CM_ SG_ 2589283393 DC_MV_Komponentenfehler_09 "Übertragung OBD relevanter Fehlerpfade vom Secondary zum Primary Steuergerät. 
Zuordnung der generischen Komponentenfehler muss zwischen Sender und Empfänger abgestimmt werden.";
CM_ SG_ 2589283393 DC_MV_Komponentenfehler_10 "Übertragung OBD relevanter Fehlerpfade vom Secondary zum Primary Steuergerät. 
Zuordnung der generischen Komponentenfehler muss zwischen Sender und Empfänger abgestimmt werden.";
CM_ SG_ 2589283393 DC_MV_Komponentenfehler_11 "Übertragung OBD relevanter Fehlerpfade vom Secondary zum Primary Steuergerät. 
Zuordnung der generischen Komponentenfehler muss zwischen Sender und Empfänger abgestimmt werden.";
CM_ SG_ 2589283393 DC_MV_Komponentenfehler_12 "Übertragung OBD relevanter Fehlerpfade vom Secondary zum Primary Steuergerät. 
Zuordnung der generischen Komponentenfehler muss zwischen Sender und Empfänger abgestimmt werden.";
CM_ SG_ 2589283393 DC_MV_Komponentenfehler_13 "Übertragung OBD relevanter Fehlerpfade vom Secondary zum Primary Steuergerät. 
Zuordnung der generischen Komponentenfehler muss zwischen Sender und Empfänger abgestimmt werden.";
CM_ SG_ 2589283393 DC_MV_Komponentenfehler_14 "Übertragung OBD relevanter Fehlerpfade vom Secondary zum Primary Steuergerät. 
Zuordnung der generischen Komponentenfehler muss zwischen Sender und Empfänger abgestimmt werden.";
CM_ SG_ 2589283393 DC_MV_Komponentenfehler_15 "Übertragung OBD relevanter Fehlerpfade vom Secondary zum Primary Steuergerät. 
Zuordnung der generischen Komponentenfehler muss zwischen Sender und Empfänger abgestimmt werden.";
CM_ SG_ 2589283393 DC_MV_Komponentenfehler_16 "Übertragung OBD relevanter Fehlerpfade vom Secondary zum Primary Steuergerät. 
Zuordnung der generischen Komponentenfehler muss zwischen Sender und Empfänger abgestimmt werden.";
CM_ SG_ 2589283393 DC_MV_Komponentenfehler_17 "Übertragung OBD relevanter Fehlerpfade vom Secondary zum Primary Steuergerät. 
Zuordnung der generischen Komponentenfehler muss zwischen Sender und Empfänger abgestimmt werden.";
CM_ SG_ 2589283393 DC_MV_Komponentenfehler_18 "Übertragung OBD relevanter Fehlerpfade vom Secondary zum Primary Steuergerät. 
Zuordnung der generischen Komponentenfehler muss zwischen Sender und Empfänger abgestimmt werden.";
CM_ SG_ 2589283393 DC_MV_Komponentenfehler_19 "Übertragung OBD relevanter Fehlerpfade vom Secondary zum Primary Steuergerät. 
Zuordnung der generischen Komponentenfehler muss zwischen Sender und Empfänger abgestimmt werden.";
CM_ SG_ 2589283393 DC_MV_Komponentenfehler_20 "Übertragung OBD relevanter Fehlerpfade vom Secondary zum Primary Steuergerät. 
Zuordnung der generischen Komponentenfehler muss zwischen Sender und Empfänger abgestimmt werden.";
CM_ SG_ 2589283393 DC_MV_Komponentenfehler_21 "Übertragung OBD relevanter Fehlerpfade vom Secondary zum Primary Steuergerät. 
Zuordnung der generischen Komponentenfehler muss zwischen Sender und Empfänger abgestimmt werden.";
CM_ SG_ 2589283393 DC_MV_Komponentenfehler_22 "Übertragung OBD relevanter Fehlerpfade vom Secondary zum Primary Steuergerät. 
Zuordnung der generischen Komponentenfehler muss zwischen Sender und Empfänger abgestimmt werden.";
CM_ SG_ 2589283393 DC_MV_Komponentenfehler_23 "Übertragung OBD relevanter Fehlerpfade vom Secondary zum Primary Steuergerät. 
Zuordnung der generischen Komponentenfehler muss zwischen Sender und Empfänger abgestimmt werden.";
CM_ SG_ 2589283393 DC_MV_Komponentenfehler_24 "Übertragung OBD relevanter Fehlerpfade vom Secondary zum Primary Steuergerät. 
Zuordnung der generischen Komponentenfehler muss zwischen Sender und Empfänger abgestimmt werden.";
CM_ SG_ 2589283393 DC_MV_Komponentenfehler_25 "Übertragung OBD relevanter Fehlerpfade vom Secondary zum Primary Steuergerät. 
Zuordnung der generischen Komponentenfehler muss zwischen Sender und Empfänger abgestimmt werden.";
CM_ SG_ 2589283393 DC_MV_Komponentenfehler_26 "Übertragung OBD relevanter Fehlerpfade vom Secondary zum Primary Steuergerät. 
Zuordnung der generischen Komponentenfehler muss zwischen Sender und Empfänger abgestimmt werden.";
CM_ SG_ 2589283393 DC_MV_Komponentenfehler_27 "Übertragung OBD relevanter Fehlerpfade vom Secondary zum Primary Steuergerät. 
Zuordnung der generischen Komponentenfehler muss zwischen Sender und Empfänger abgestimmt werden.";
CM_ SG_ 2589283393 DC_MV_Komponentenfehler_28 "Übertragung OBD relevanter Fehlerpfade vom Secondary zum Primary Steuergerät. 
Zuordnung der generischen Komponentenfehler muss zwischen Sender und Empfänger abgestimmt werden.";
CM_ SG_ 2589283393 DC_MV_Komponentenfehler_29 "Übertragung OBD relevanter Fehlerpfade vom Secondary zum Primary Steuergerät. 
Zuordnung der generischen Komponentenfehler muss zwischen Sender und Empfänger abgestimmt werden.";
CM_ SG_ 2589283393 DC_MV_Komponentenfehler_30 "Übertragung OBD relevanter Fehlerpfade vom Secondary zum Primary Steuergerät. 
Zuordnung der generischen Komponentenfehler muss zwischen Sender und Empfänger abgestimmt werden.";
CM_ SG_ 2589283393 DC_MV_Komponentenfehler_31 "Übertragung OBD relevanter Fehlerpfade vom Secondary zum Primary Steuergerät. 
Zuordnung der generischen Komponentenfehler muss zwischen Sender und Empfänger abgestimmt werden.";
CM_ SG_ 2589283393 DC_MV_Komponentenfehler_VLD "Valid-Bit der OBD-Komponentenfehler. Das Bit wird beim Fehlerspeicher löschen zurückgenommen und erst wieder gesetzt, wenn der Fehlerspeicher vollständig gelöscht wurde. Der Primary-OBD-ECU soll damit mitgeteilt werden, ob sie den Inhalten der Komponenten";
CM_ SG_ 2589283855 DC_MV_Komponentenfehler_32 "Übertragung OBD relevanter Fehlerpfade vom Secondary zum Primary Steuergerät. 
Zuordnung der generischen Komponentenfehler muss zwischen Sender und Empfänger abgestimmt werden.";
CM_ SG_ 2589283855 DC_MV_Komponentenfehler_33 "Übertragung OBD relevanter Fehlerpfade vom Secondary zum Primary Steuergerät. 
Zuordnung der generischen Komponentenfehler muss zwischen Sender und Empfänger abgestimmt werden.";
CM_ SG_ 2589283855 DC_MV_Komponentenfehler_34 "Übertragung OBD relevanter Fehlerpfade vom Secondary zum Primary Steuergerät. 
Zuordnung der generischen Komponentenfehler muss zwischen Sender und Empfänger abgestimmt werden.";
CM_ SG_ 2589283855 DC_MV_Komponentenfehler_35 "Übertragung OBD relevanter Fehlerpfade vom Secondary zum Primary Steuergerät. 
Zuordnung der generischen Komponentenfehler muss zwischen Sender und Empfänger abgestimmt werden.";
CM_ SG_ 2589283855 DC_MV_Komponentenfehler_36 "Übertragung OBD relevanter Fehlerpfade vom Secondary zum Primary Steuergerät. 
Zuordnung der generischen Komponentenfehler muss zwischen Sender und Empfänger abgestimmt werden.";
CM_ SG_ 2589283855 DC_MV_Komponentenfehler_37 "Übertragung OBD relevanter Fehlerpfade vom Secondary zum Primary Steuergerät. 
Zuordnung der generischen Komponentenfehler muss zwischen Sender und Empfänger abgestimmt werden.";
CM_ SG_ 2589283855 DC_MV_Komponentenfehler_38 "Übertragung OBD relevanter Fehlerpfade vom Secondary zum Primary Steuergerät. 
Zuordnung der generischen Komponentenfehler muss zwischen Sender und Empfänger abgestimmt werden.";
CM_ SG_ 2589283855 DC_MV_Komponentenfehler_39 "Übertragung OBD relevanter Fehlerpfade vom Secondary zum Primary Steuergerät. 
Zuordnung der generischen Komponentenfehler muss zwischen Sender und Empfänger abgestimmt werden.";
CM_ SG_ 2589283855 DC_MV_Komponentenfehler_40 "Übertragung OBD relevanter Fehlerpfade vom Secondary zum Primary Steuergerät. 
Zuordnung der generischen Komponentenfehler muss zwischen Sender und Empfänger abgestimmt werden.";
CM_ SG_ 2589283855 DC_MV_Komponentenfehler_41 "Übertragung OBD relevanter Fehlerpfade vom Secondary zum Primary Steuergerät. 
Zuordnung der generischen Komponentenfehler muss zwischen Sender und Empfänger abgestimmt werden.";
CM_ SG_ 2589283855 DC_MV_Komponentenfehler_42 "Übertragung OBD relevanter Fehlerpfade vom Secondary zum Primary Steuergerät. 
Zuordnung der generischen Komponentenfehler muss zwischen Sender und Empfänger abgestimmt werden.";
CM_ SG_ 2589283855 DC_MV_Komponentenfehler_43 "Übertragung OBD relevanter Fehlerpfade vom Secondary zum Primary Steuergerät. 
Zuordnung der generischen Komponentenfehler muss zwischen Sender und Empfänger abgestimmt werden.";
CM_ SG_ 2589283855 DC_MV_Komponentenfehler_44 "Übertragung OBD relevanter Fehlerpfade vom Secondary zum Primary Steuergerät. 
Zuordnung der generischen Komponentenfehler muss zwischen Sender und Empfänger abgestimmt werden.";
CM_ SG_ 2589283855 DC_MV_Komponentenfehler_45 "Übertragung OBD relevanter Fehlerpfade vom Secondary zum Primary Steuergerät. 
Zuordnung der generischen Komponentenfehler muss zwischen Sender und Empfänger abgestimmt werden.";
CM_ SG_ 2589283855 DC_MV_Komponentenfehler_46 "Übertragung OBD relevanter Fehlerpfade vom Secondary zum Primary Steuergerät. 
Zuordnung der generischen Komponentenfehler muss zwischen Sender und Empfänger abgestimmt werden.";
CM_ SG_ 2589283855 DC_MV_Komponentenfehler_47 "Übertragung OBD relevanter Fehlerpfade vom Secondary zum Primary Steuergerät. 
Zuordnung der generischen Komponentenfehler muss zwischen Sender und Empfänger abgestimmt werden.";
CM_ SG_ 2589283855 DC_MV_Komponentenfehler_48 "Übertragung OBD relevanter Fehlerpfade vom Secondary zum Primary Steuergerät. 
Zuordnung der generischen Komponentenfehler muss zwischen Sender und Empfänger abgestimmt werden.";
CM_ SG_ 2589283855 DC_MV_Komponentenfehler_49 "Übertragung OBD relevanter Fehlerpfade vom Secondary zum Primary Steuergerät. 
Zuordnung der generischen Komponentenfehler muss zwischen Sender und Empfänger abgestimmt werden.";
CM_ SG_ 2589283855 DC_MV_Komponentenfehler_50 "Übertragung OBD relevanter Fehlerpfade vom Secondary zum Primary Steuergerät. 
Zuordnung der generischen Komponentenfehler muss zwischen Sender und Empfänger abgestimmt werden.";
CM_ SG_ 2589283855 DC_MV_Komponentenfehler_51 "Übertragung OBD relevanter Fehlerpfade vom Secondary zum Primary Steuergerät. 
Zuordnung der generischen Komponentenfehler muss zwischen Sender und Empfänger abgestimmt werden.";
CM_ SG_ 2589283855 DC_MV_Komponentenfehler_52 "Übertragung OBD relevanter Fehlerpfade vom Secondary zum Primary Steuergerät. 
Zuordnung der generischen Komponentenfehler muss zwischen Sender und Empfänger abgestimmt werden.";
CM_ SG_ 2589283855 DC_MV_Komponentenfehler_53 "Übertragung OBD relevanter Fehlerpfade vom Secondary zum Primary Steuergerät. 
Zuordnung der generischen Komponentenfehler muss zwischen Sender und Empfänger abgestimmt werden.";
CM_ SG_ 2589283855 DC_MV_Komponentenfehler_54 "Übertragung OBD relevanter Fehlerpfade vom Secondary zum Primary Steuergerät. 
Zuordnung der generischen Komponentenfehler muss zwischen Sender und Empfänger abgestimmt werden.";
CM_ SG_ 2589283855 DC_MV_Komponentenfehler_55 "Übertragung OBD relevanter Fehlerpfade vom Secondary zum Primary Steuergerät. 
Zuordnung der generischen Komponentenfehler muss zwischen Sender und Empfänger abgestimmt werden.";
CM_ SG_ 2589283855 DC_MV_Komponentenfehler_56 "Übertragung OBD relevanter Fehlerpfade vom Secondary zum Primary Steuergerät. 
Zuordnung der generischen Komponentenfehler muss zwischen Sender und Empfänger abgestimmt werden.";
CM_ SG_ 2589283855 DC_MV_Komponentenfehler_57 "Übertragung OBD relevanter Fehlerpfade vom Secondary zum Primary Steuergerät. 
Zuordnung der generischen Komponentenfehler muss zwischen Sender und Empfänger abgestimmt werden.";
CM_ SG_ 2589283855 DC_MV_Komponentenfehler_58 "Übertragung OBD relevanter Fehlerpfade vom Secondary zum Primary Steuergerät. 
Zuordnung der generischen Komponentenfehler muss zwischen Sender und Empfänger abgestimmt werden.";
CM_ SG_ 2589283855 DC_MV_Komponentenfehler_59 "Übertragung OBD relevanter Fehlerpfade vom Secondary zum Primary Steuergerät. 
Zuordnung der generischen Komponentenfehler muss zwischen Sender und Empfänger abgestimmt werden.";
CM_ SG_ 2589283855 DC_MV_Komponentenfehler_60 "Übertragung OBD relevanter Fehlerpfade vom Secondary zum Primary Steuergerät. 
Zuordnung der generischen Komponentenfehler muss zwischen Sender und Empfänger abgestimmt werden.";
CM_ SG_ 2589283855 DC_MV_Komponentenfehler_61 "Übertragung OBD relevanter Fehlerpfade vom Secondary zum Primary Steuergerät. 
Zuordnung der generischen Komponentenfehler muss zwischen Sender und Empfänger abgestimmt werden.";
CM_ SG_ 2589283855 DC_MV_Komponentenfehler_62 "Übertragung OBD relevanter Fehlerpfade vom Secondary zum Primary Steuergerät. 
Zuordnung der generischen Komponentenfehler muss zwischen Sender und Empfänger abgestimmt werden.";
BA_DEF_ BO_  "DiagRequest" ENUM  "No","Yes";
BA_DEF_ BO_  "DiagResponse" ENUM  "No","Yes";
BA_DEF_ BO_  "DiagState" ENUM  "No","Yes";
BA_DEF_ BO_  "GenMsgChkConstant" HEX 0 4095;
BA_DEF_ BO_  "GenMsgCycleTime" INT 0 65535;
BA_DEF_ BO_  "GenMsgCycleTimeFast" INT 0 65535;
BA_DEF_ BO_  "GenMsgDelayTime" INT 0 100000;
BA_DEF_ BO_  "GenMsgILSupport" ENUM  "No","Yes";
BA_DEF_ BO_  "GenMsgNrOfRepetition" INT 0 100;
BA_DEF_ BO_  "GenMsgPDUConstants" STRING ;
BA_DEF_ BO_  "GenMsgSendType" ENUM  "Cyclic","not_used","not_used","not_used","not_used","not_used","not_used","IfActive","NoMsgSendType";
BA_DEF_ BO_  "GenMsgStartDelayTime" INT 0 100000;
BA_DEF_ BO_  "NmMessage" ENUM  "No","Yes";
BA_DEF_ BO_  "NmhMessage" ENUM  "No","Yes";
BA_DEF_ BO_  "MsgType" ENUM  "Application","NM ","NMH","TP2.0","ISO-TP ","BAP","EID","KS","XCP_PRE_CONFIGURED","XCP_RUNTIME_CONFIGURED";
BA_DEF_ BO_  "VAGTP20_API" HEX 0 255;
BA_DEF_ BO_  "VAGTP20_DynConnection" ENUM  "No","Yes";
BA_DEF_ BO_  "VAGTP20_DynSetup" ENUM  "No","Yes";
BA_DEF_ BO_  "VAGTP20_StatConnection" ENUM  "No","Yes";
BA_DEF_ SG_  "GenSigActiveRepetitions" INT -2147483648 2147483647;
BA_DEF_ SG_  "GenSigInactiveValue" INT -2147483648 2147483647;
BA_DEF_ SG_  "GenSigSendType" ENUM  "Cyclic","OnWrite","OnWriteWithRepetition","OnChange","OnChangeWithRepetition","IfActive","IfActiveWithRepetition","NoSigSendType","OnChangeAndIfActive","OnChangeAndIfActiveWithRepetition";
BA_DEF_ SG_  "GenSigStartValue" INT -2147483648 2147483647;
BA_DEF_ SG_  "NWM-WakeupAllowed" ENUM  "No","Yes";
BA_DEF_ SG_  "GenSigFuncType" ENUM  "NoFunction","MsgCounter","CRC-8","XOR","XOR-2","DatedBit","SW-Kl15","CHK","Constant","Protocol","CRC-8-SAE_J1850","CRC-32","DataLength","DataID","MsgCounter16","SOK-Signatur","Cluster";
BA_DEF_ SG_  "GenSigSwitchedByIgnition" ENUM  "No","Yes";
BA_DEF_ SG_  "Fehlerwert" HEX 0 2147483647;
BA_DEF_ SG_  "GenSigMissingSourceValue" HEX 0 2147483647;
BA_DEF_REL_ BU_SG_REL_  "GenSigTimeoutTime" INT 0 65535;
BA_DEF_DEF_REL_ "GenSigTimeoutTime" 0;
BA_DEF_DEF_  "DiagRequest" "No";
BA_DEF_DEF_  "DiagResponse" "No";
BA_DEF_DEF_  "DiagState" "No";
BA_DEF_DEF_  "GenMsgChkConstant" 0;
BA_DEF_DEF_  "GenMsgCycleTime" 0;
BA_DEF_DEF_  "GenMsgCycleTimeFast" 0;
BA_DEF_DEF_  "GenMsgDelayTime" 0;
BA_DEF_DEF_  "GenMsgILSupport" "No";
BA_DEF_DEF_  "GenMsgNrOfRepetition" 0;
BA_DEF_DEF_  "GenMsgPDUConstants" "";
BA_DEF_DEF_  "GenMsgSendType" "NoMsgSendType";
BA_DEF_DEF_  "GenMsgStartDelayTime" 0;
BA_DEF_DEF_  "NmMessage" "No";
BA_DEF_DEF_  "NmhMessage" "No";
BA_DEF_DEF_  "MsgType" "Application";
BA_DEF_DEF_  "VAGTP20_API" 0;
BA_DEF_DEF_  "VAGTP20_DynConnection" "No";
BA_DEF_DEF_  "VAGTP20_DynSetup" "No";
BA_DEF_DEF_  "VAGTP20_StatConnection" "No";
BA_DEF_DEF_  "GenSigActiveRepetitions" 0;
BA_DEF_DEF_  "GenSigInactiveValue" 0;
BA_DEF_DEF_  "GenSigSendType" "NoSigSendType";
BA_DEF_DEF_  "GenSigStartValue" 0;
BA_DEF_DEF_  "NWM-WakeupAllowed" "No";
BA_DEF_DEF_  "GenSigFuncType" "NoFunction";
BA_DEF_DEF_  "GenSigSwitchedByIgnition" "Yes";
BA_DEF_DEF_  "Fehlerwert" 0;
BA_DEF_DEF_  "GenSigMissingSourceValue" 0;
BA_ "GenMsgSendType" BO_ 1289 0;
BA_ "GenMsgILSupport" BO_ 1289 1;
BA_ "GenMsgCycleTime" BO_ 1289 100;
BA_ "GenMsgSendType" BO_ 2527679654 0;
BA_ "GenMsgPDUConstants" BO_ 2527679654 "0x79,0xb9,0x67,0xad,0xd5,0xf7,0x70,0xaa,0x44,0x61,0x5a,0xdc,0x26,0xb4,0xd2,0xc3";
BA_ "GenMsgILSupport" BO_ 2527679654 1;
BA_ "GenMsgCycleTime" BO_ 2527679654 2000;
BA_ "GenMsgSendType" BO_ 2589283637 0;
BA_ "GenMsgILSupport" BO_ 2589283637 1;
BA_ "GenMsgCycleTime" BO_ 2589283637 2000;
BA_ "GenMsgSendType" BO_ 2589283638 0;
BA_ "GenMsgILSupport" BO_ 2589283638 1;
BA_ "GenMsgCycleTime" BO_ 2589283638 2000;
BA_ "GenMsgSendType" BO_ 1111 0;
BA_ "GenMsgPDUConstants" BO_ 1111 "0x82,0x79,0xee,0xb9,0xf9,0x67,0x97,0xad,0xb1,0xd5,0xcb,0xf7,0xb6,0x70,0x13,0xaa";
BA_ "GenMsgILSupport" BO_ 1111 1;
BA_ "GenMsgCycleTime" BO_ 1111 100;
BA_ "GenMsgSendType" BO_ 2589283877 0;
BA_ "GenMsgILSupport" BO_ 2589283877 1;
BA_ "GenMsgCycleTime" BO_ 2589283877 2000;
BA_ "GenMsgSendType" BO_ 2589283641 0;
BA_ "GenMsgILSupport" BO_ 2589283641 1;
BA_ "GenMsgCycleTime" BO_ 2589283641 1000;
BA_ "GenMsgSendType" BO_ 2589283651 0;
BA_ "GenMsgILSupport" BO_ 2589283651 1;
BA_ "GenMsgCycleTime" BO_ 2589283651 1000;
BA_ "GenMsgSendType" BO_ 2589283652 0;
BA_ "GenMsgILSupport" BO_ 2589283652 1;
BA_ "GenMsgCycleTime" BO_ 2589283652 500;
BA_ "GenMsgSendType" BO_ 2589283878 0;
BA_ "GenMsgILSupport" BO_ 2589283878 1;
BA_ "GenMsgCycleTime" BO_ 2589283878 1000;
BA_ "GenMsgSendType" BO_ 2589283666 0;
BA_ "GenMsgILSupport" BO_ 2589283666 1;
BA_ "GenMsgDelayTime" BO_ 2589283666 100;
BA_ "GenMsgCycleTime" BO_ 2589283666 1000;
BA_ "GenMsgSendType" BO_ 2463978763 0;
BA_ "GenMsgPDUConstants" BO_ 2463978763 "0x67,0xf7,0x44,0xdc,0xd2,0xca,0xe7,0x2b,0xd6,0x5c,0xc6,0xa3,0xbe,0x0d,0x16,0x58";
BA_ "GenMsgILSupport" BO_ 2463978763 1;
BA_ "GenMsgCycleTime" BO_ 2463978763 100;
BA_ "GenMsgSendType" BO_ 1400 0;
BA_ "GenMsgPDUConstants" BO_ 1400 "0x48,0x48,0x48,0x48,0x48,0x48,0x48,0x48,0x48,0x48,0x48,0x48,0x48,0x48,0x48,0x48";
BA_ "GenMsgILSupport" BO_ 1400 1;
BA_ "GenMsgCycleTimeFast" BO_ 1400 100;
BA_ "GenMsgCycleTime" BO_ 1400 1000;
BA_ "GenMsgChkConstant" BO_ 1400 72;
BA_ "GenMsgSendType" BO_ 397 0;
BA_ "GenMsgPDUConstants" BO_ 397 "0x9c,0xcc,0xe1,0x4c,0xc9,0x39,0xe3,0x53,0x78,0x33,0x15,0x49,0x55,0x0a,0x62,0x83";
BA_ "GenMsgILSupport" BO_ 397 1;
BA_ "GenMsgCycleTime" BO_ 397 10;
BA_ "GenMsgSendType" BO_ 419 0;
BA_ "GenMsgPDUConstants" BO_ 419 "0x4a,0x06,0x0a,0x36,0xf8,0xd3,0x60,0x79,0xaa,0xd2,0x2e,0x89,0xa3,0x76,0x5f,0x45";
BA_ "GenMsgILSupport" BO_ 419 1;
BA_ "GenMsgCycleTime" BO_ 419 20;
BA_ "GenMsgSendType" BO_ 871 0;
BA_ "GenMsgPDUConstants" BO_ 871 "0xa1,0xb0,0xdb,0x69,0x9c,0xef,0xbd,0x08,0xdd,0xcc,0x1b,0x05,0xce,0x20,0xe1,0x48";
BA_ "GenMsgILSupport" BO_ 871 1;
BA_ "GenMsgCycleTime" BO_ 871 100;
BA_ "GenMsgSendType" BO_ 1443 0;
BA_ "GenMsgPDUConstants" BO_ 1443 "0x0a,0xd3,0xaa,0x89,0x5f,0xc4,0x27,0x2d,0xfb,0xa0,0x47,0x1e,0x28,0xa8,0x44,0x5c";
BA_ "GenMsgILSupport" BO_ 1443 1;
BA_ "GenMsgDelayTime" BO_ 1443 20;
BA_ "GenMsgCycleTime" BO_ 1443 500;
BA_ "GenMsgSendType" BO_ 2589283412 0;
BA_ "GenMsgILSupport" BO_ 2589283412 1;
BA_ "GenMsgCycleTime" BO_ 2589283412 500;
BA_ "GenMsgSendType" BO_ 2589283608 0;
BA_ "GenMsgILSupport" BO_ 2589283608 1;
BA_ "GenMsgCycleTime" BO_ 2589283608 500;
BA_ "GenMsgSendType" BO_ 2589283606 0;
BA_ "GenMsgILSupport" BO_ 2589283606 1;
BA_ "GenMsgCycleTime" BO_ 2589283606 1000;
BA_ "GenMsgSendType" BO_ 1021 0;
BA_ "GenMsgILSupport" BO_ 1021 1;
BA_ "GenMsgCycleTime" BO_ 1021 100;
BA_ "GenMsgSendType" BO_ 499 0;
BA_ "GenMsgPDUConstants" BO_ 499 "0xc4,0x1e,0x9c,0xae,0x59,0xcc,0x66,0x99,0xe1,0x87,0xe8,0x4c,0x65,0x4a,0xc9,0xde";
BA_ "GenMsgILSupport" BO_ 499 1;
BA_ "GenMsgDelayTime" BO_ 499 10;
BA_ "GenMsgCycleTime" BO_ 499 100;
BA_ "GenMsgSendType" BO_ 504 0;
BA_ "GenMsgILSupport" BO_ 504 1;
BA_ "GenMsgDelayTime" BO_ 504 10;
BA_ "GenMsgCycleTime" BO_ 504 100;
BA_ "GenMsgSendType" BO_ 874 0;
BA_ "GenMsgILSupport" BO_ 874 1;
BA_ "GenMsgCycleTime" BO_ 874 500;
BA_ "GenMsgSendType" BO_ 2463978664 0;
BA_ "GenMsgILSupport" BO_ 2463978664 1;
BA_ "GenMsgCycleTime" BO_ 2463978664 100;
BA_ "GenMsgSendType" BO_ 2463978720 0;
BA_ "GenMsgPDUConstants" BO_ 2463978720 "0xd0,0x4d,0x22,0xae,0x8a,0x67,0xf4,0x35,0x15,0x2a,0xb8,0x4e,0xcc,0x07,0xad,0xa2";
BA_ "GenMsgILSupport" BO_ 2463978720 1;
BA_ "GenMsgCycleTime" BO_ 2463978720 100;
BA_ "GenMsgSendType" BO_ 179 0;
BA_ "GenMsgPDUConstants" BO_ 179 "0x41,0x41,0x41,0x41,0x41,0x41,0x41,0x41,0x41,0x41,0x41,0x41,0x41,0x41,0x41,0x41";
BA_ "GenMsgILSupport" BO_ 179 1;
BA_ "GenMsgCycleTime" BO_ 179 1000;
BA_ "GenMsgChkConstant" BO_ 179 65;
BA_ "MsgType" BO_ 2617236992 6;
BA_ "MsgType" BO_ 2617236993 6;
BA_ "MsgType" BO_ 2617130752 6;
BA_ "MsgType" BO_ 2617130753 6;
BA_ "MsgType" BO_ 2617194240 6;
BA_ "MsgType" BO_ 2617194241 6;
BA_ "MsgType" BO_ 2617124352 6;
BA_ "MsgType" BO_ 2617124353 6;
BA_ "GenMsgStartDelayTime" BO_ 901 50;
BA_ "GenMsgSendType" BO_ 901 0;
BA_ "GenMsgILSupport" BO_ 901 1;
BA_ "GenMsgDelayTime" BO_ 901 50;
BA_ "GenMsgCycleTime" BO_ 901 1000;
BA_ "GenMsgStartDelayTime" BO_ 1022 50;
BA_ "GenMsgSendType" BO_ 1022 0;
BA_ "GenMsgILSupport" BO_ 1022 1;
BA_ "GenMsgDelayTime" BO_ 1022 50;
BA_ "GenMsgCycleTime" BO_ 1022 1000;
BA_ "GenMsgSendType" BO_ 2589283686 0;
BA_ "GenMsgILSupport" BO_ 2589283686 1;
BA_ "GenMsgCycleTime" BO_ 2589283686 1000;
BA_ "GenMsgSendType" BO_ 2589283393 0;
BA_ "GenMsgILSupport" BO_ 2589283393 1;
BA_ "GenMsgCycleTime" BO_ 2589283393 1000;
BA_ "GenMsgSendType" BO_ 2589283855 0;
BA_ "GenMsgILSupport" BO_ 2589283855 1;
BA_ "GenMsgCycleTime" BO_ 2589283855 500;
BA_ "Fehlerwert" SG_ 1289 BMS_Energieinhalt_HiRes 32767;
BA_ "GenSigSwitchedByIgnition" SG_ 1289 BMS_Energieinhalt_HiRes 0;
BA_ "GenSigStartValue" SG_ 1289 BMS_Energieinhalt_HiRes 32766;
BA_ "GenSigSendType" SG_ 1289 BMS_Energieinhalt_HiRes 0;
BA_ "Fehlerwert" SG_ 1289 BMS_MaxEnergieinhalt_HiRes 32767;
BA_ "GenSigSwitchedByIgnition" SG_ 1289 BMS_MaxEnergieinhalt_HiRes 0;
BA_ "GenSigStartValue" SG_ 1289 BMS_MaxEnergieinhalt_HiRes 32766;
BA_ "GenSigSendType" SG_ 1289 BMS_MaxEnergieinhalt_HiRes 0;
BA_ "Fehlerwert" SG_ 1289 BMS_NutzbarerSOC 255;
BA_ "GenSigSwitchedByIgnition" SG_ 1289 BMS_NutzbarerSOC 0;
BA_ "GenSigStartValue" SG_ 1289 BMS_NutzbarerSOC 254;
BA_ "GenSigSendType" SG_ 1289 BMS_NutzbarerSOC 0;
BA_ "Fehlerwert" SG_ 1289 BMS_NutzbarerEnergieinhalt 4095;
BA_ "GenSigSwitchedByIgnition" SG_ 1289 BMS_NutzbarerEnergieinhalt 0;
BA_ "GenSigStartValue" SG_ 1289 BMS_NutzbarerEnergieinhalt 4094;
BA_ "GenSigSendType" SG_ 1289 BMS_NutzbarerEnergieinhalt 0;
BA_ "Fehlerwert" SG_ 1289 BMS_Pred_Entladeperformance 127;
BA_ "GenSigSwitchedByIgnition" SG_ 1289 BMS_Pred_Entladeperformance 0;
BA_ "GenSigStartValue" SG_ 1289 BMS_Pred_Entladeperformance 126;
BA_ "GenSigSendType" SG_ 1289 BMS_Pred_Entladeperformance 0;
BA_ "Fehlerwert" SG_ 1289 BMS_Pred_Ladeperformance 127;
BA_ "GenSigSwitchedByIgnition" SG_ 1289 BMS_Pred_Ladeperformance 0;
BA_ "GenSigStartValue" SG_ 1289 BMS_Pred_Ladeperformance 126;
BA_ "GenSigSendType" SG_ 1289 BMS_Pred_Ladeperformance 0;
BA_ "GenSigSwitchedByIgnition" SG_ 2527679654 BMS_IsoZustand 0;
BA_ "GenSigSendType" SG_ 2527679654 BMS_IsoZustand 0;
BA_ "GenSigSwitchedByIgnition" SG_ 2527679654 BMS_IsoFehler 0;
BA_ "GenSigSendType" SG_ 2527679654 BMS_IsoFehler 0;
BA_ "Fehlerwert" SG_ 2527679654 BMS_IstTemperatur_hoechste 255;
BA_ "GenSigSwitchedByIgnition" SG_ 2527679654 BMS_IstTemperatur_hoechste 0;
BA_ "GenSigStartValue" SG_ 2527679654 BMS_IstTemperatur_hoechste 254;
BA_ "GenSigSendType" SG_ 2527679654 BMS_IstTemperatur_hoechste 0;
BA_ "Fehlerwert" SG_ 2527679654 BMS_IstTemperatur_niedrigste 255;
BA_ "GenSigSwitchedByIgnition" SG_ 2527679654 BMS_IstTemperatur_niedrigste 0;
BA_ "GenSigStartValue" SG_ 2527679654 BMS_IstTemperatur_niedrigste 254;
BA_ "GenSigSendType" SG_ 2527679654 BMS_IstTemperatur_niedrigste 0;
BA_ "Fehlerwert" SG_ 2527679654 BMS_IstZellspannung_hoechste 4095;
BA_ "GenSigSwitchedByIgnition" SG_ 2527679654 BMS_IstZellspannung_hoechste 0;
BA_ "GenSigStartValue" SG_ 2527679654 BMS_IstZellspannung_hoechste 4094;
BA_ "GenSigSendType" SG_ 2527679654 BMS_IstZellspannung_hoechste 0;
BA_ "Fehlerwert" SG_ 2527679654 BMS_IstZellspannung_niedrigste 4095;
BA_ "GenSigSwitchedByIgnition" SG_ 2527679654 BMS_IstZellspannung_niedrigste 0;
BA_ "GenSigStartValue" SG_ 2527679654 BMS_IstZellspannung_niedrigste 4094;
BA_ "GenSigSendType" SG_ 2527679654 BMS_IstZellspannung_niedrigste 0;
BA_ "GenSigSwitchedByIgnition" SG_ 2589283637 BMS_Pack_SN_01 0;
BA_ "GenSigStartValue" SG_ 2589283637 BMS_Pack_SN_01 255;
BA_ "GenSigSendType" SG_ 2589283637 BMS_Pack_SN_01 0;
BA_ "GenSigSwitchedByIgnition" SG_ 2589283637 BMS_Pack_SN_02 0;
BA_ "GenSigStartValue" SG_ 2589283637 BMS_Pack_SN_02 255;
BA_ "GenSigSendType" SG_ 2589283637 BMS_Pack_SN_02 0;
BA_ "GenSigSwitchedByIgnition" SG_ 2589283637 BMS_Pack_SN_03 0;
BA_ "GenSigStartValue" SG_ 2589283637 BMS_Pack_SN_03 255;
BA_ "GenSigSendType" SG_ 2589283637 BMS_Pack_SN_03 0;
BA_ "GenSigSwitchedByIgnition" SG_ 2589283637 BMS_Pack_SN_04 0;
BA_ "GenSigStartValue" SG_ 2589283637 BMS_Pack_SN_04 255;
BA_ "GenSigSendType" SG_ 2589283637 BMS_Pack_SN_04 0;
BA_ "GenSigSwitchedByIgnition" SG_ 2589283637 BMS_Pack_SN_05 0;
BA_ "GenSigStartValue" SG_ 2589283637 BMS_Pack_SN_05 255;
BA_ "GenSigSendType" SG_ 2589283637 BMS_Pack_SN_05 0;
BA_ "GenSigSwitchedByIgnition" SG_ 2589283637 BMS_Pack_SN_06 0;
BA_ "GenSigStartValue" SG_ 2589283637 BMS_Pack_SN_06 255;
BA_ "GenSigSendType" SG_ 2589283637 BMS_Pack_SN_06 0;
BA_ "GenSigSwitchedByIgnition" SG_ 2589283637 BMS_Pack_SN_07 0;
BA_ "GenSigStartValue" SG_ 2589283637 BMS_Pack_SN_07 255;
BA_ "GenSigSendType" SG_ 2589283637 BMS_Pack_SN_07 0;
BA_ "GenSigSwitchedByIgnition" SG_ 2589283637 BMS_Pack_SN_08 0;
BA_ "GenSigStartValue" SG_ 2589283637 BMS_Pack_SN_08 255;
BA_ "GenSigSendType" SG_ 2589283637 BMS_Pack_SN_08 0;
BA_ "GenSigSwitchedByIgnition" SG_ 2589283638 BMS_Pack_SN_09 0;
BA_ "GenSigStartValue" SG_ 2589283638 BMS_Pack_SN_09 255;
BA_ "GenSigSendType" SG_ 2589283638 BMS_Pack_SN_09 0;
BA_ "GenSigSwitchedByIgnition" SG_ 2589283638 BMS_Pack_SN_10 0;
BA_ "GenSigStartValue" SG_ 2589283638 BMS_Pack_SN_10 255;
BA_ "GenSigSendType" SG_ 2589283638 BMS_Pack_SN_10 0;
BA_ "GenSigSwitchedByIgnition" SG_ 2589283638 BMS_Pack_SN_11 0;
BA_ "GenSigStartValue" SG_ 2589283638 BMS_Pack_SN_11 255;
BA_ "GenSigSendType" SG_ 2589283638 BMS_Pack_SN_11 0;
BA_ "GenSigSwitchedByIgnition" SG_ 2589283638 BMS_Pack_SN_12 0;
BA_ "GenSigStartValue" SG_ 2589283638 BMS_Pack_SN_12 255;
BA_ "GenSigSendType" SG_ 2589283638 BMS_Pack_SN_12 0;
BA_ "GenSigSwitchedByIgnition" SG_ 2589283638 BMS_Pack_SN_13 0;
BA_ "GenSigStartValue" SG_ 2589283638 BMS_Pack_SN_13 255;
BA_ "GenSigSendType" SG_ 2589283638 BMS_Pack_SN_13 0;
BA_ "GenSigSwitchedByIgnition" SG_ 2589283638 BMS_Pack_SN_14 0;
BA_ "GenSigStartValue" SG_ 2589283638 BMS_Pack_SN_14 255;
BA_ "GenSigSendType" SG_ 2589283638 BMS_Pack_SN_14 0;
BA_ "GenSigSwitchedByIgnition" SG_ 2589283638 BMS_Pack_SN_15 0;
BA_ "GenSigStartValue" SG_ 2589283638 BMS_Pack_SN_15 255;
BA_ "GenSigSendType" SG_ 2589283638 BMS_Pack_SN_15 0;
BA_ "GenSigSwitchedByIgnition" SG_ 2589283638 BMS_Pack_SN_16 0;
BA_ "GenSigStartValue" SG_ 2589283638 BMS_Pack_SN_16 255;
BA_ "GenSigSendType" SG_ 2589283638 BMS_Pack_SN_16 0;
BA_ "GenSigSwitchedByIgnition" SG_ 1111 BMS_14_CRC 0;
BA_ "GenSigFuncType" SG_ 1111 BMS_14_CRC 2;
BA_ "GenSigSendType" SG_ 1111 BMS_14_CRC 0;
BA_ "GenSigSwitchedByIgnition" SG_ 1111 BMS_14_BZ 0;
BA_ "GenSigFuncType" SG_ 1111 BMS_14_BZ 1;
BA_ "GenSigSendType" SG_ 1111 BMS_14_BZ 0;
BA_ "Fehlerwert" SG_ 1111 BMS_Warnung_Stuetzung_NV 7;
BA_ "GenSigSwitchedByIgnition" SG_ 1111 BMS_Warnung_Stuetzung_NV 0;
BA_ "GenSigStartValue" SG_ 1111 BMS_Warnung_Stuetzung_NV 6;
BA_ "GenSigSendType" SG_ 1111 BMS_Warnung_Stuetzung_NV 0;
BA_ "Fehlerwert" SG_ 1111 BMS_RIso_GND_HVM 4095;
BA_ "GenSigSwitchedByIgnition" SG_ 1111 BMS_RIso_GND_HVM 0;
BA_ "GenSigStartValue" SG_ 1111 BMS_RIso_GND_HVM 4094;
BA_ "GenSigSendType" SG_ 1111 BMS_RIso_GND_HVM 0;
BA_ "Fehlerwert" SG_ 1111 BMS_RIso_GND_HVP 4095;
BA_ "GenSigSwitchedByIgnition" SG_ 1111 BMS_RIso_GND_HVP 0;
BA_ "GenSigStartValue" SG_ 1111 BMS_RIso_GND_HVP 4094;
BA_ "GenSigSendType" SG_ 1111 BMS_RIso_GND_HVP 0;
BA_ "Fehlerwert" SG_ 1111 BMS_Spannung_ZwKr2 2047;
BA_ "GenSigSwitchedByIgnition" SG_ 1111 BMS_Spannung_ZwKr2 0;
BA_ "GenSigStartValue" SG_ 1111 BMS_Spannung_ZwKr2 2046;
BA_ "GenSigSendType" SG_ 1111 BMS_Spannung_ZwKr2 0;
BA_ "GenSigSwitchedByIgnition" SG_ 2589283877 BMS_Pack_SN_17 0;
BA_ "GenSigStartValue" SG_ 2589283877 BMS_Pack_SN_17 255;
BA_ "GenSigSendType" SG_ 2589283877 BMS_Pack_SN_17 0;
BA_ "GenSigSwitchedByIgnition" SG_ 2589283877 BMS_Pack_SN_18 0;
BA_ "GenSigStartValue" SG_ 2589283877 BMS_Pack_SN_18 255;
BA_ "GenSigSendType" SG_ 2589283877 BMS_Pack_SN_18 0;
BA_ "GenSigSwitchedByIgnition" SG_ 2589283877 BMS_Pack_SN_19 0;
BA_ "GenSigStartValue" SG_ 2589283877 BMS_Pack_SN_19 255;
BA_ "GenSigSendType" SG_ 2589283877 BMS_Pack_SN_19 0;
BA_ "GenSigSwitchedByIgnition" SG_ 2589283877 BMS_Pack_SN_20 0;
BA_ "GenSigStartValue" SG_ 2589283877 BMS_Pack_SN_20 255;
BA_ "GenSigSendType" SG_ 2589283877 BMS_Pack_SN_20 0;
BA_ "GenSigSwitchedByIgnition" SG_ 2589283877 BMS_Pack_SN_21 0;
BA_ "GenSigStartValue" SG_ 2589283877 BMS_Pack_SN_21 255;
BA_ "GenSigSendType" SG_ 2589283877 BMS_Pack_SN_21 0;
BA_ "GenSigSwitchedByIgnition" SG_ 2589283877 BMS_Pack_SN_22 0;
BA_ "GenSigStartValue" SG_ 2589283877 BMS_Pack_SN_22 255;
BA_ "GenSigSendType" SG_ 2589283877 BMS_Pack_SN_22 0;
BA_ "GenSigSwitchedByIgnition" SG_ 2589283877 BMS_Pack_SN_23 0;
BA_ "GenSigStartValue" SG_ 2589283877 BMS_Pack_SN_23 255;
BA_ "GenSigSendType" SG_ 2589283877 BMS_Pack_SN_23 0;
BA_ "GenSigSwitchedByIgnition" SG_ 2589283877 BMS_Pack_SN_24 0;
BA_ "GenSigStartValue" SG_ 2589283877 BMS_Pack_SN_24 255;
BA_ "GenSigSendType" SG_ 2589283877 BMS_Pack_SN_24 0;
BA_ "GenSigSwitchedByIgnition" SG_ 2589283641 BMS_IstTemperaturMin_Sensor_ID 0;
BA_ "GenSigStartValue" SG_ 2589283641 BMS_IstTemperaturMin_Sensor_ID 31;
BA_ "GenSigSendType" SG_ 2589283641 BMS_IstTemperaturMin_Sensor_ID 0;
BA_ "GenSigSwitchedByIgnition" SG_ 2589283641 BMS_IstTemperaturMax_Sensor_ID 0;
BA_ "GenSigStartValue" SG_ 2589283641 BMS_IstTemperaturMax_Sensor_ID 31;
BA_ "GenSigSendType" SG_ 2589283641 BMS_IstTemperaturMax_Sensor_ID 0;
BA_ "GenSigSwitchedByIgnition" SG_ 2589283641 BMS_IstTemperaturMin_Modul_ID 0;
BA_ "GenSigStartValue" SG_ 2589283641 BMS_IstTemperaturMin_Modul_ID 255;
BA_ "GenSigSendType" SG_ 2589283641 BMS_IstTemperaturMin_Modul_ID 0;
BA_ "GenSigSwitchedByIgnition" SG_ 2589283641 BMS_IstTemperaturMax_Modul_ID 0;
BA_ "GenSigStartValue" SG_ 2589283641 BMS_IstTemperaturMax_Modul_ID 255;
BA_ "GenSigSendType" SG_ 2589283641 BMS_IstTemperaturMax_Modul_ID 0;
BA_ "GenSigSwitchedByIgnition" SG_ 2589283641 BMS_IstZellSpannungMin_Modul_ID 0;
BA_ "GenSigStartValue" SG_ 2589283641 BMS_IstZellSpannungMin_Modul_ID 255;
BA_ "GenSigSendType" SG_ 2589283641 BMS_IstZellSpannungMin_Modul_ID 0;
BA_ "GenSigSwitchedByIgnition" SG_ 2589283641 BMS_IstZellSpannungMax_Modul_ID 0;
BA_ "GenSigStartValue" SG_ 2589283641 BMS_IstZellSpannungMax_Modul_ID 255;
BA_ "GenSigSendType" SG_ 2589283641 BMS_IstZellSpannungMax_Modul_ID 0;
BA_ "GenSigSwitchedByIgnition" SG_ 2589283641 BMS_IstZellSpannungMin_Zell_ID 0;
BA_ "GenSigStartValue" SG_ 2589283641 BMS_IstZellSpannungMin_Zell_ID 255;
BA_ "GenSigSendType" SG_ 2589283641 BMS_IstZellSpannungMin_Zell_ID 0;
BA_ "GenSigSwitchedByIgnition" SG_ 2589283641 BMS_IstZellSpannungMax_Zell_ID 0;
BA_ "GenSigStartValue" SG_ 2589283641 BMS_IstZellSpannungMax_Zell_ID 255;
BA_ "GenSigSendType" SG_ 2589283641 BMS_IstZellSpannungMax_Zell_ID 0;
BA_ "GenSigSwitchedByIgnition" SG_ 2589283651 BMS_RtmWarnUeberstrom 0;
BA_ "GenSigSendType" SG_ 2589283651 BMS_RtmWarnUeberstrom 0;
BA_ "GenSigSwitchedByIgnition" SG_ 2589283651 BMS_RtmWarnPackKommunikation 0;
BA_ "GenSigSendType" SG_ 2589283651 BMS_RtmWarnPackKommunikation 0;
BA_ "GenSigSwitchedByIgnition" SG_ 2589283651 BMS_RtmWarnPackUeberladen 0;
BA_ "GenSigSendType" SG_ 2589283651 BMS_RtmWarnPackUeberladen 0;
BA_ "GenSigSwitchedByIgnition" SG_ 2589283651 BMS_RtmWarnSocHoch 0;
BA_ "GenSigSendType" SG_ 2589283651 BMS_RtmWarnSocHoch 0;
BA_ "GenSigSwitchedByIgnition" SG_ 2589283651 BMS_RtmWarnSocNiedrig 0;
BA_ "GenSigSendType" SG_ 2589283651 BMS_RtmWarnSocNiedrig 0;
BA_ "GenSigSwitchedByIgnition" SG_ 2589283651 BMS_RtmWarnSocSprung 0;
BA_ "GenSigSendType" SG_ 2589283651 BMS_RtmWarnSocSprung 0;
BA_ "GenSigSwitchedByIgnition" SG_ 2589283651 BMS_RtmWarnTZelleDiff 0;
BA_ "GenSigSendType" SG_ 2589283651 BMS_RtmWarnTZelleDiff 0;
BA_ "GenSigSwitchedByIgnition" SG_ 2589283651 BMS_RtmWarnTZelleMax 0;
BA_ "GenSigSendType" SG_ 2589283651 BMS_RtmWarnTZelleMax 0;
BA_ "GenSigSwitchedByIgnition" SG_ 2589283651 BMS_RtmWarnTZelleMin 0;
BA_ "GenSigSendType" SG_ 2589283651 BMS_RtmWarnTZelleMin 0;
BA_ "GenSigSwitchedByIgnition" SG_ 2589283651 BMS_RtmWarnUPackMax 0;
BA_ "GenSigSendType" SG_ 2589283651 BMS_RtmWarnUPackMax 0;
BA_ "GenSigSwitchedByIgnition" SG_ 2589283651 BMS_RtmWarnUPackMin 0;
BA_ "GenSigSendType" SG_ 2589283651 BMS_RtmWarnUPackMin 0;
BA_ "GenSigSwitchedByIgnition" SG_ 2589283651 BMS_RtmWarnUZelleMax 0;
BA_ "GenSigSendType" SG_ 2589283651 BMS_RtmWarnUZelleMax 0;
BA_ "GenSigSwitchedByIgnition" SG_ 2589283651 BMS_RtmWarnUZelleMin 0;
BA_ "GenSigSendType" SG_ 2589283651 BMS_RtmWarnUZelleMin 0;
BA_ "GenSigSwitchedByIgnition" SG_ 2589283651 BMS_RtmWarnZelleZustand 0;
BA_ "GenSigSendType" SG_ 2589283651 BMS_RtmWarnZelleZustand 0;
BA_ "Fehlerwert" SG_ 2589283652 BMS_Energie_Entladung 65535;
BA_ "GenSigSwitchedByIgnition" SG_ 2589283652 BMS_Energie_Entladung 0;
BA_ "GenSigStartValue" SG_ 2589283652 BMS_Energie_Entladung 65534;
BA_ "GenSigSendType" SG_ 2589283652 BMS_Energie_Entladung 0;
BA_ "Fehlerwert" SG_ 2589283652 BMS_Energie_Ladung 65535;
BA_ "GenSigSwitchedByIgnition" SG_ 2589283652 BMS_Energie_Ladung 0;
BA_ "GenSigStartValue" SG_ 2589283652 BMS_Energie_Ladung 65534;
BA_ "GenSigSendType" SG_ 2589283652 BMS_Energie_Ladung 0;
BA_ "GenSigSwitchedByIgnition" SG_ 2589283878 BMS_Pack_SN_25 0;
BA_ "GenSigStartValue" SG_ 2589283878 BMS_Pack_SN_25 255;
BA_ "GenSigSendType" SG_ 2589283878 BMS_Pack_SN_25 0;
BA_ "GenSigSwitchedByIgnition" SG_ 2589283878 BMS_Pack_SN_26 0;
BA_ "GenSigStartValue" SG_ 2589283878 BMS_Pack_SN_26 255;
BA_ "GenSigSendType" SG_ 2589283878 BMS_Pack_SN_26 0;
BA_ "Fehlerwert" SG_ 2589283666 BMS_LadegrenzeAntw_SOC 127;
BA_ "GenSigSwitchedByIgnition" SG_ 2589283666 BMS_LadegrenzeAntw_SOC 0;
BA_ "GenSigStartValue" SG_ 2589283666 BMS_LadegrenzeAntw_SOC 126;
BA_ "GenSigSendType" SG_ 2589283666 BMS_LadegrenzeAntw_SOC 0;
BA_ "Fehlerwert" SG_ 2589283666 BMS_EnergieAntw_Zaehler 15;
BA_ "GenSigSwitchedByIgnition" SG_ 2589283666 BMS_EnergieAntw_Zaehler 0;
BA_ "GenSigStartValue" SG_ 2589283666 BMS_EnergieAntw_Zaehler 14;
BA_ "GenSigSendType" SG_ 2589283666 BMS_EnergieAntw_Zaehler 3;
BA_ "Fehlerwert" SG_ 2589283666 BMS_EnergieAntw_Energie 2047;
BA_ "GenSigSwitchedByIgnition" SG_ 2589283666 BMS_EnergieAntw_Energie 0;
BA_ "GenSigStartValue" SG_ 2589283666 BMS_EnergieAntw_Energie 2046;
BA_ "GenSigSendType" SG_ 2589283666 BMS_EnergieAntw_Energie 0;
BA_ "Fehlerwert" SG_ 2589283666 BMS_LadegrenzeAntw_Leistung 4095;
BA_ "GenSigSwitchedByIgnition" SG_ 2589283666 BMS_LadegrenzeAntw_Leistung 0;
BA_ "GenSigStartValue" SG_ 2589283666 BMS_LadegrenzeAntw_Leistung 4094;
BA_ "GenSigSendType" SG_ 2589283666 BMS_LadegrenzeAntw_Leistung 0;
BA_ "Fehlerwert" SG_ 2589283666 BMS_LadegrenzeAntw_Zaehler 15;
BA_ "GenSigSwitchedByIgnition" SG_ 2589283666 BMS_LadegrenzeAntw_Zaehler 0;
BA_ "GenSigStartValue" SG_ 2589283666 BMS_LadegrenzeAntw_Zaehler 14;
BA_ "GenSigSendType" SG_ 2589283666 BMS_LadegrenzeAntw_Zaehler 3;
BA_ "GenSigSwitchedByIgnition" SG_ 2463978763 BMS_30_CRC 0;
BA_ "GenSigFuncType" SG_ 2463978763 BMS_30_CRC 2;
BA_ "GenSigSendType" SG_ 2463978763 BMS_30_CRC 0;
BA_ "GenSigSwitchedByIgnition" SG_ 2463978763 BMS_30_BZ 0;
BA_ "GenSigFuncType" SG_ 2463978763 BMS_30_BZ 1;
BA_ "GenSigSendType" SG_ 2463978763 BMS_30_BZ 0;
BA_ "Fehlerwert" SG_ 2463978763 BMS_Ueberspannung_Zelle 7;
BA_ "GenSigSwitchedByIgnition" SG_ 2463978763 BMS_Ueberspannung_Zelle 0;
BA_ "GenSigStartValue" SG_ 2463978763 BMS_Ueberspannung_Zelle 6;
BA_ "GenSigSendType" SG_ 2463978763 BMS_Ueberspannung_Zelle 0;
BA_ "GenSigFuncType" SG_ 1400 BMS_DC_01_CRC 2;
BA_ "GenSigSendType" SG_ 1400 BMS_DC_01_CRC 0;
BA_ "GenSigFuncType" SG_ 1400 BMS_DC_01_BZ 1;
BA_ "GenSigSendType" SG_ 1400 BMS_DC_01_BZ 0;
BA_ "GenSigSwitchedByIgnition" SG_ 1400 BMS_Status_DCLS 0;
BA_ "GenSigSendType" SG_ 1400 BMS_Status_DCLS 5;
BA_ "Fehlerwert" SG_ 1400 BMS_DCLS_Spannung 1023;
BA_ "GenSigSwitchedByIgnition" SG_ 1400 BMS_DCLS_Spannung 0;
BA_ "GenSigStartValue" SG_ 1400 BMS_DCLS_Spannung 1022;
BA_ "GenSigSendType" SG_ 1400 BMS_DCLS_Spannung 5;
BA_ "Fehlerwert" SG_ 1400 BMS_DCLS_MaxLadeStrom 511;
BA_ "GenSigSwitchedByIgnition" SG_ 1400 BMS_DCLS_MaxLadeStrom 0;
BA_ "GenSigStartValue" SG_ 1400 BMS_DCLS_MaxLadeStrom 510;
BA_ "GenSigSendType" SG_ 1400 BMS_DCLS_MaxLadeStrom 0;
BA_ "GenSigSwitchedByIgnition" SG_ 397 BMS_MV_01_CRC 0;
BA_ "GenSigFuncType" SG_ 397 BMS_MV_01_CRC 2;
BA_ "GenSigSendType" SG_ 397 BMS_MV_01_CRC 0;
BA_ "GenSigSwitchedByIgnition" SG_ 397 BMS_MV_01_BZ 0;
BA_ "GenSigFuncType" SG_ 397 BMS_MV_01_BZ 1;
BA_ "GenSigSendType" SG_ 397 BMS_MV_01_BZ 0;
BA_ "Fehlerwert" SG_ 397 BMS_MV_IstStrom 4095;
BA_ "GenSigSwitchedByIgnition" SG_ 397 BMS_MV_IstStrom 0;
BA_ "GenSigStartValue" SG_ 397 BMS_MV_IstStrom 4094;
BA_ "GenSigSendType" SG_ 397 BMS_MV_IstStrom 0;
BA_ "Fehlerwert" SG_ 397 BMS_MV_IstSpannung 255;
BA_ "GenSigSwitchedByIgnition" SG_ 397 BMS_MV_IstSpannung 0;
BA_ "GenSigStartValue" SG_ 397 BMS_MV_IstSpannung 254;
BA_ "GenSigSendType" SG_ 397 BMS_MV_IstSpannung 0;
BA_ "Fehlerwert" SG_ 397 BMS_MV_SOC_HiRes 2047;
BA_ "GenSigSwitchedByIgnition" SG_ 397 BMS_MV_SOC_HiRes 0;
BA_ "GenSigStartValue" SG_ 397 BMS_MV_SOC_HiRes 2046;
BA_ "GenSigSendType" SG_ 397 BMS_MV_SOC_HiRes 0;
BA_ "GenSigSwitchedByIgnition" SG_ 419 BMS_MV_02_CRC 0;
BA_ "GenSigFuncType" SG_ 419 BMS_MV_02_CRC 2;
BA_ "GenSigSendType" SG_ 419 BMS_MV_02_CRC 0;
BA_ "GenSigSwitchedByIgnition" SG_ 419 BMS_MV_02_BZ 0;
BA_ "GenSigFuncType" SG_ 419 BMS_MV_02_BZ 1;
BA_ "GenSigSendType" SG_ 419 BMS_MV_02_BZ 0;
BA_ "Fehlerwert" SG_ 419 BMS_MV_MaxDyn_EntladeStrom 2047;
BA_ "GenSigSwitchedByIgnition" SG_ 419 BMS_MV_MaxDyn_EntladeStrom 0;
BA_ "GenSigStartValue" SG_ 419 BMS_MV_MaxDyn_EntladeStrom 2046;
BA_ "GenSigSendType" SG_ 419 BMS_MV_MaxDyn_EntladeStrom 0;
BA_ "Fehlerwert" SG_ 419 BMS_MV_MaxDyn_LadeStrom 2047;
BA_ "GenSigSwitchedByIgnition" SG_ 419 BMS_MV_MaxDyn_LadeStrom 0;
BA_ "GenSigStartValue" SG_ 419 BMS_MV_MaxDyn_LadeStrom 2046;
BA_ "GenSigSendType" SG_ 419 BMS_MV_MaxDyn_LadeStrom 0;
BA_ "Fehlerwert" SG_ 419 BMS_MV_Min_EntladeSpannung 255;
BA_ "GenSigSwitchedByIgnition" SG_ 419 BMS_MV_Min_EntladeSpannung 0;
BA_ "GenSigStartValue" SG_ 419 BMS_MV_Min_EntladeSpannung 254;
BA_ "GenSigSendType" SG_ 419 BMS_MV_Min_EntladeSpannung 0;
BA_ "GenSigSwitchedByIgnition" SG_ 419 BMS_MV_MinDynEntladeSpannung 0;
BA_ "GenSigStartValue" SG_ 419 BMS_MV_MinDynEntladeSpannung 254;
BA_ "GenSigSendType" SG_ 419 BMS_MV_MinDynEntladeSpannung 0;
BA_ "GenSigSwitchedByIgnition" SG_ 419 BMS_MV_MinDyn_LadeSpannung 0;
BA_ "GenSigStartValue" SG_ 419 BMS_MV_MinDyn_LadeSpannung 254;
BA_ "GenSigSendType" SG_ 419 BMS_MV_MinDyn_LadeSpannung 0;
BA_ "GenSigSwitchedByIgnition" SG_ 871 BMS_MV_03_CRC 0;
BA_ "GenSigFuncType" SG_ 871 BMS_MV_03_CRC 2;
BA_ "GenSigSendType" SG_ 871 BMS_MV_03_CRC 0;
BA_ "GenSigSwitchedByIgnition" SG_ 871 BMS_MV_03_BZ 0;
BA_ "GenSigFuncType" SG_ 871 BMS_MV_03_BZ 1;
BA_ "GenSigSendType" SG_ 871 BMS_MV_03_BZ 0;
BA_ "Fehlerwert" SG_ 871 BMS_MV_Max_LadeSpannung 255;
BA_ "GenSigSwitchedByIgnition" SG_ 871 BMS_MV_Max_LadeSpannung 0;
BA_ "GenSigStartValue" SG_ 871 BMS_MV_Max_LadeSpannung 254;
BA_ "GenSigSendType" SG_ 871 BMS_MV_Max_LadeSpannung 0;
BA_ "Fehlerwert" SG_ 871 BMS_MV_MaxPred_EntladeStrom 2047;
BA_ "GenSigSwitchedByIgnition" SG_ 871 BMS_MV_MaxPred_EntladeStrom 0;
BA_ "GenSigStartValue" SG_ 871 BMS_MV_MaxPred_EntladeStrom 2046;
BA_ "GenSigSendType" SG_ 871 BMS_MV_MaxPred_EntladeStrom 0;
BA_ "Fehlerwert" SG_ 871 BMS_MV_MaxPred_LadeStrom 2047;
BA_ "GenSigSwitchedByIgnition" SG_ 871 BMS_MV_MaxPred_LadeStrom 0;
BA_ "GenSigStartValue" SG_ 871 BMS_MV_MaxPred_LadeStrom 2046;
BA_ "GenSigSendType" SG_ 871 BMS_MV_MaxPred_LadeStrom 0;
BA_ "GenSigSwitchedByIgnition" SG_ 871 BMS_MV_MinPred_EntladeSpannung 0;
BA_ "GenSigStartValue" SG_ 871 BMS_MV_MinPred_EntladeSpannung 254;
BA_ "GenSigSendType" SG_ 871 BMS_MV_MinPred_EntladeSpannung 0;
BA_ "GenSigSwitchedByIgnition" SG_ 871 BMS_MV_MinPred_LadeSpannung 0;
BA_ "GenSigStartValue" SG_ 871 BMS_MV_MinPred_LadeSpannung 254;
BA_ "GenSigSendType" SG_ 871 BMS_MV_MinPred_LadeSpannung 0;
BA_ "GenSigSwitchedByIgnition" SG_ 871 BMS_MV_Leistungsreduzierung 0;
BA_ "GenSigSendType" SG_ 871 BMS_MV_Leistungsreduzierung 0;
BA_ "GenSigSwitchedByIgnition" SG_ 1443 BMS_MV_04_CRC 0;
BA_ "GenSigFuncType" SG_ 1443 BMS_MV_04_CRC 2;
BA_ "GenSigSendType" SG_ 1443 BMS_MV_04_CRC 0;
BA_ "GenSigSwitchedByIgnition" SG_ 1443 BMS_MV_04_BZ 0;
BA_ "GenSigFuncType" SG_ 1443 BMS_MV_04_BZ 1;
BA_ "GenSigSendType" SG_ 1443 BMS_MV_04_BZ 0;
BA_ "GenSigSwitchedByIgnition" SG_ 1443 BMS_MV_OBD_Lampe_Anf 0;
BA_ "GenSigSendType" SG_ 1443 BMS_MV_OBD_Lampe_Anf 0;
BA_ "GenSigSwitchedByIgnition" SG_ 1443 BMS_MV_IstModus 0;
BA_ "GenSigStartValue" SG_ 1443 BMS_MV_IstModus 7;
BA_ "GenSigSendType" SG_ 1443 BMS_MV_IstModus 1;
BA_ "GenSigSwitchedByIgnition" SG_ 1443 BMS_MV_FehlerStatus 0;
BA_ "GenSigStartValue" SG_ 1443 BMS_MV_FehlerStatus 7;
BA_ "GenSigSendType" SG_ 1443 BMS_MV_FehlerStatus 3;
BA_ "GenSigSwitchedByIgnition" SG_ 2589283412 BMS_MV_Temperierung_Anf 0;
BA_ "GenSigStartValue" SG_ 2589283412 BMS_MV_Temperierung_Anf 3;
BA_ "GenSigSendType" SG_ 2589283412 BMS_MV_Temperierung_Anf 0;
BA_ "GenSigSwitchedByIgnition" SG_ 2589283412 BMS_MV_Speichertechnologie 0;
BA_ "GenSigSendType" SG_ 2589283412 BMS_MV_Speichertechnologie 0;
BA_ "GenSigSwitchedByIgnition" SG_ 2589283412 BMS_MV_Temp_Epsilon 0;
BA_ "GenSigSendType" SG_ 2589283412 BMS_MV_Temp_Epsilon 0;
BA_ "GenSigSwitchedByIgnition" SG_ 2589283412 BMS_MV_Soll_PWM_Pumpe 0;
BA_ "GenSigStartValue" SG_ 2589283412 BMS_MV_Soll_PWM_Pumpe 15;
BA_ "GenSigSendType" SG_ 2589283412 BMS_MV_Soll_PWM_Pumpe 0;
BA_ "Fehlerwert" SG_ 2589283412 BMS_MV_Temperatur 255;
BA_ "GenSigSwitchedByIgnition" SG_ 2589283412 BMS_MV_Temperatur 0;
BA_ "GenSigStartValue" SG_ 2589283412 BMS_MV_Temperatur 254;
BA_ "GenSigSendType" SG_ 2589283412 BMS_MV_Temperatur 0;
BA_ "Fehlerwert" SG_ 2589283412 BMS_MV_IstVorlaufTemperatur 255;
BA_ "GenSigSwitchedByIgnition" SG_ 2589283412 BMS_MV_IstVorlaufTemperatur 0;
BA_ "GenSigStartValue" SG_ 2589283412 BMS_MV_IstVorlaufTemperatur 254;
BA_ "GenSigSendType" SG_ 2589283412 BMS_MV_IstVorlaufTemperatur 0;
BA_ "Fehlerwert" SG_ 2589283412 BMS_MV_SollVolumenstrom 63;
BA_ "GenSigSwitchedByIgnition" SG_ 2589283412 BMS_MV_SollVolumenstrom 0;
BA_ "GenSigStartValue" SG_ 2589283412 BMS_MV_SollVolumenstrom 62;
BA_ "GenSigSendType" SG_ 2589283412 BMS_MV_SollVolumenstrom 0;
BA_ "Fehlerwert" SG_ 2589283412 BMS_MV_SollVorlauftemperatur 255;
BA_ "GenSigSwitchedByIgnition" SG_ 2589283412 BMS_MV_SollVorlauftemperatur 0;
BA_ "GenSigStartValue" SG_ 2589283412 BMS_MV_SollVorlauftemperatur 254;
BA_ "GenSigSendType" SG_ 2589283412 BMS_MV_SollVorlauftemperatur 0;
BA_ "Fehlerwert" SG_ 2589283412 BMS_MV_IstRuecklaufTemperatur 255;
BA_ "GenSigSwitchedByIgnition" SG_ 2589283412 BMS_MV_IstRuecklaufTemperatur 0;
BA_ "GenSigStartValue" SG_ 2589283412 BMS_MV_IstRuecklaufTemperatur 254;
BA_ "GenSigSendType" SG_ 2589283412 BMS_MV_IstRuecklaufTemperatur 0;
BA_ "Fehlerwert" SG_ 2589283608 BMS_MV_Energieinhalt 2047;
BA_ "GenSigSwitchedByIgnition" SG_ 2589283608 BMS_MV_Energieinhalt 0;
BA_ "GenSigStartValue" SG_ 2589283608 BMS_MV_Energieinhalt 2046;
BA_ "GenSigSendType" SG_ 2589283608 BMS_MV_Energieinhalt 0;
BA_ "Fehlerwert" SG_ 2589283608 BMS_MV_MaxEnergieinhalt 2047;
BA_ "GenSigSwitchedByIgnition" SG_ 2589283608 BMS_MV_MaxEnergieinhalt 0;
BA_ "GenSigStartValue" SG_ 2589283608 BMS_MV_MaxEnergieinhalt 2046;
BA_ "GenSigSendType" SG_ 2589283608 BMS_MV_MaxEnergieinhalt 0;
BA_ "Fehlerwert" SG_ 2589283606 BMS_MV_SOC_Kaltstart 2047;
BA_ "GenSigSwitchedByIgnition" SG_ 2589283606 BMS_MV_SOC_Kaltstart 0;
BA_ "GenSigStartValue" SG_ 2589283606 BMS_MV_SOC_Kaltstart 2046;
BA_ "GenSigSendType" SG_ 2589283606 BMS_MV_SOC_Kaltstart 0;
BA_ "GenSigSwitchedByIgnition" SG_ 2589283606 BMS_MV_max_Grenz_SOC 0;
BA_ "GenSigStartValue" SG_ 2589283606 BMS_MV_max_Grenz_SOC 31;
BA_ "GenSigSendType" SG_ 2589283606 BMS_MV_max_Grenz_SOC 0;
BA_ "Fehlerwert" SG_ 1021 BMS_MV_Pred_Entladeperformance 127;
BA_ "GenSigSwitchedByIgnition" SG_ 1021 BMS_MV_Pred_Entladeperformance 0;
BA_ "GenSigStartValue" SG_ 1021 BMS_MV_Pred_Entladeperformance 126;
BA_ "GenSigSendType" SG_ 1021 BMS_MV_Pred_Entladeperformance 0;
BA_ "Fehlerwert" SG_ 1021 BMS_MV_Pred_Ladeperformance 127;
BA_ "GenSigSwitchedByIgnition" SG_ 1021 BMS_MV_Pred_Ladeperformance 0;
BA_ "GenSigStartValue" SG_ 1021 BMS_MV_Pred_Ladeperformance 126;
BA_ "GenSigSendType" SG_ 1021 BMS_MV_Pred_Ladeperformance 0;
BA_ "GenSigSwitchedByIgnition" SG_ 499 BMS_NV_01_CRC 0;
BA_ "GenSigFuncType" SG_ 499 BMS_NV_01_CRC 2;
BA_ "GenSigSendType" SG_ 499 BMS_NV_01_CRC 0;
BA_ "GenSigSwitchedByIgnition" SG_ 499 BMS_NV_01_BZ 0;
BA_ "GenSigFuncType" SG_ 499 BMS_NV_01_BZ 1;
BA_ "GenSigSendType" SG_ 499 BMS_NV_01_BZ 0;
BA_ "GenSigSwitchedByIgnition" SG_ 499 BMS_NV_FMAus_Info 0;
BA_ "GenSigStartValue" SG_ 499 BMS_NV_FMAus_Info 1;
BA_ "GenSigSendType" SG_ 499 BMS_NV_FMAus_Info 3;
BA_ "GenSigSendType" SG_ 499 BMS_NV_TE_Status 0;
BA_ "Fehlerwert" SG_ 499 BMS_NV_IstStrom 262143;
BA_ "GenSigSwitchedByIgnition" SG_ 499 BMS_NV_IstStrom 0;
BA_ "GenSigStartValue" SG_ 499 BMS_NV_IstStrom 262142;
BA_ "GenSigSendType" SG_ 499 BMS_NV_IstStrom 0;
BA_ "Fehlerwert" SG_ 499 BMS_NV_IstSpannung 16383;
BA_ "GenSigSwitchedByIgnition" SG_ 499 BMS_NV_IstSpannung 0;
BA_ "GenSigStartValue" SG_ 499 BMS_NV_IstSpannung 16382;
BA_ "GenSigSendType" SG_ 499 BMS_NV_IstSpannung 0;
BA_ "Fehlerwert" SG_ 499 BMS_NV_StSt_Nutzbare_Ladung 255;
BA_ "GenSigStartValue" SG_ 499 BMS_NV_StSt_Nutzbare_Ladung 254;
BA_ "GenSigSendType" SG_ 499 BMS_NV_StSt_Nutzbare_Ladung 0;
BA_ "GenSigSwitchedByIgnition" SG_ 499 BMS_NV_BatterieAb 0;
BA_ "GenSigSendType" SG_ 499 BMS_NV_BatterieAb 3;
BA_ "Fehlerwert" SG_ 499 BMS_NV_IstModus 2;
BA_ "GenSigSwitchedByIgnition" SG_ 499 BMS_NV_IstModus 0;
BA_ "GenSigStartValue" SG_ 499 BMS_NV_IstModus 3;
BA_ "GenSigSendType" SG_ 499 BMS_NV_IstModus 3;
BA_ "GenSigSwitchedByIgnition" SG_ 504 BMS_NV_Fehlerstatus 0;
BA_ "GenSigStartValue" SG_ 504 BMS_NV_Fehlerstatus 7;
BA_ "GenSigSendType" SG_ 504 BMS_NV_Fehlerstatus 3;
BA_ "Fehlerwert" SG_ 504 BMS_NV_Qe_LI_Inhalt 4095;
BA_ "GenSigSwitchedByIgnition" SG_ 504 BMS_NV_Qe_LI_Inhalt 0;
BA_ "GenSigStartValue" SG_ 504 BMS_NV_Qe_LI_Inhalt 4094;
BA_ "GenSigSendType" SG_ 504 BMS_NV_Qe_LI_Inhalt 0;
BA_ "Fehlerwert" SG_ 504 BMS_NV_IMaxStart 255;
BA_ "GenSigSwitchedByIgnition" SG_ 504 BMS_NV_IMaxStart 0;
BA_ "GenSigStartValue" SG_ 504 BMS_NV_IMaxStart 254;
BA_ "GenSigSendType" SG_ 504 BMS_NV_IMaxStart 0;
BA_ "Fehlerwert" SG_ 504 BMS_NV_Ri_Batterie 255;
BA_ "GenSigSwitchedByIgnition" SG_ 504 BMS_NV_Ri_Batterie 0;
BA_ "GenSigStartValue" SG_ 504 BMS_NV_Ri_Batterie 254;
BA_ "GenSigSendType" SG_ 504 BMS_NV_Ri_Batterie 0;
BA_ "Fehlerwert" SG_ 504 BMS_NV_SOC 255;
BA_ "GenSigSwitchedByIgnition" SG_ 504 BMS_NV_SOC 0;
BA_ "GenSigStartValue" SG_ 504 BMS_NV_SOC 254;
BA_ "GenSigSendType" SG_ 504 BMS_NV_SOC 0;
BA_ "Fehlerwert" SG_ 504 BMS_NV_UMinStart 255;
BA_ "GenSigSwitchedByIgnition" SG_ 504 BMS_NV_UMinStart 0;
BA_ "GenSigStartValue" SG_ 504 BMS_NV_UMinStart 254;
BA_ "GenSigSendType" SG_ 504 BMS_NV_UMinStart 0;
BA_ "Fehlerwert" SG_ 874 BMS_NV_Max_LadeStrom 1023;
BA_ "GenSigSwitchedByIgnition" SG_ 874 BMS_NV_Max_LadeStrom 0;
BA_ "GenSigStartValue" SG_ 874 BMS_NV_Max_LadeStrom 1022;
BA_ "GenSigSendType" SG_ 874 BMS_NV_Max_LadeStrom 0;
BA_ "Fehlerwert" SG_ 874 BMS_NV_Max_EntladeStrom 1023;
BA_ "GenSigSwitchedByIgnition" SG_ 874 BMS_NV_Max_EntladeStrom 0;
BA_ "GenSigStartValue" SG_ 874 BMS_NV_Max_EntladeStrom 1022;
BA_ "GenSigSendType" SG_ 874 BMS_NV_Max_EntladeStrom 0;
BA_ "Fehlerwert" SG_ 874 BMS_NV_Max_LadeSpannung 63;
BA_ "GenSigSwitchedByIgnition" SG_ 874 BMS_NV_Max_LadeSpannung 0;
BA_ "GenSigStartValue" SG_ 874 BMS_NV_Max_LadeSpannung 62;
BA_ "GenSigSendType" SG_ 874 BMS_NV_Max_LadeSpannung 0;
BA_ "GenSigSwitchedByIgnition" SG_ 874 BMS_NV_Diagnose_Anf 0;
BA_ "GenSigStartValue" SG_ 874 BMS_NV_Diagnose_Anf 7;
BA_ "GenSigSendType" SG_ 874 BMS_NV_Diagnose_Anf 0;
BA_ "Fehlerwert" SG_ 874 BMS_NV_Min_EntladeSpannung 63;
BA_ "GenSigSwitchedByIgnition" SG_ 874 BMS_NV_Min_EntladeSpannung 0;
BA_ "GenSigStartValue" SG_ 874 BMS_NV_Min_EntladeSpannung 62;
BA_ "GenSigSendType" SG_ 874 BMS_NV_Min_EntladeSpannung 0;
BA_ "Fehlerwert" SG_ 874 BMS_NV_Kapazitaet_akt 511;
BA_ "GenSigSwitchedByIgnition" SG_ 874 BMS_NV_Kapazitaet_akt 0;
BA_ "GenSigStartValue" SG_ 874 BMS_NV_Kapazitaet_akt 510;
BA_ "GenSigSendType" SG_ 874 BMS_NV_Kapazitaet_akt 0;
BA_ "Fehlerwert" SG_ 874 BMS_NV_Temperatur 255;
BA_ "GenSigSwitchedByIgnition" SG_ 874 BMS_NV_Temperatur 0;
BA_ "GenSigStartValue" SG_ 874 BMS_NV_Temperatur 254;
BA_ "GenSigSendType" SG_ 874 BMS_NV_Temperatur 0;
BA_ "Fehlerwert" SG_ 2463978664 BMS_NV_Polspannung 511;
BA_ "GenSigSwitchedByIgnition" SG_ 2463978664 BMS_NV_Polspannung 0;
BA_ "GenSigStartValue" SG_ 2463978664 BMS_NV_Polspannung 510;
BA_ "GenSigSendType" SG_ 2463978664 BMS_NV_Polspannung 0;
BA_ "GenSigSwitchedByIgnition" SG_ 2463978720 BMS_NV_05_CRC 0;
BA_ "GenSigFuncType" SG_ 2463978720 BMS_NV_05_CRC 2;
BA_ "GenSigSendType" SG_ 2463978720 BMS_NV_05_CRC 0;
BA_ "GenSigSwitchedByIgnition" SG_ 2463978720 BMS_NV_05_BZ 0;
BA_ "GenSigFuncType" SG_ 2463978720 BMS_NV_05_BZ 1;
BA_ "GenSigSendType" SG_ 2463978720 BMS_NV_05_BZ 0;
BA_ "Fehlerwert" SG_ 2463978720 BMS_NV_SollPred_EntladeSpannung 255;
BA_ "GenSigSwitchedByIgnition" SG_ 2463978720 BMS_NV_SollPred_EntladeSpannung 0;
BA_ "GenSigStartValue" SG_ 2463978720 BMS_NV_SollPred_EntladeSpannung 254;
BA_ "GenSigSendType" SG_ 2463978720 BMS_NV_SollPred_EntladeSpannung 0;
BA_ "Fehlerwert" SG_ 2463978720 BMS_NV_SollDyn_EntladeSpannung 255;
BA_ "GenSigSwitchedByIgnition" SG_ 2463978720 BMS_NV_SollDyn_EntladeSpannung 0;
BA_ "GenSigStartValue" SG_ 2463978720 BMS_NV_SollDyn_EntladeSpannung 254;
BA_ "GenSigSendType" SG_ 2463978720 BMS_NV_SollDyn_EntladeSpannung 0;
BA_ "Fehlerwert" SG_ 2463978720 BMS_NV_IstDyn_EntladeStrom 2047;
BA_ "GenSigSwitchedByIgnition" SG_ 2463978720 BMS_NV_IstDyn_EntladeStrom 0;
BA_ "GenSigStartValue" SG_ 2463978720 BMS_NV_IstDyn_EntladeStrom 2046;
BA_ "GenSigSendType" SG_ 2463978720 BMS_NV_IstDyn_EntladeStrom 0;
BA_ "Fehlerwert" SG_ 2463978720 BMS_NV_IstPred_EntladeStrom 2047;
BA_ "GenSigSwitchedByIgnition" SG_ 2463978720 BMS_NV_IstPred_EntladeStrom 0;
BA_ "GenSigStartValue" SG_ 2463978720 BMS_NV_IstPred_EntladeStrom 2046;
BA_ "GenSigSendType" SG_ 2463978720 BMS_NV_IstPred_EntladeStrom 0;
BA_ "GenSigSwitchedByIgnition" SG_ 179 Bremse_EV_01_CRC 0;
BA_ "GenSigFuncType" SG_ 179 Bremse_EV_01_CRC 2;
BA_ "GenSigSendType" SG_ 179 Bremse_EV_01_CRC 0;
BA_ "GenSigSwitchedByIgnition" SG_ 179 Bremse_EV_01_BZ 0;
BA_ "GenSigFuncType" SG_ 179 Bremse_EV_01_BZ 1;
BA_ "GenSigSendType" SG_ 179 Bremse_EV_01_BZ 0;
BA_ "Fehlerwert" SG_ 179 EBKV_Generatorsollmoment 4095;
BA_ "GenSigStartValue" SG_ 179 EBKV_Generatorsollmoment 4094;
BA_ "GenSigSendType" SG_ 179 EBKV_Generatorsollmoment 0;
BA_ "Fehlerwert" SG_ 179 EBKV_Bremspedalweg 255;
BA_ "GenSigSwitchedByIgnition" SG_ 179 EBKV_Bremspedalweg 0;
BA_ "GenSigSendType" SG_ 179 EBKV_Bremspedalweg 0;
BA_ "Fehlerwert" SG_ 179 EBKV_Status 7;
BA_ "GenSigSwitchedByIgnition" SG_ 179 EBKV_Status 0;
BA_ "GenSigSendType" SG_ 179 EBKV_Status 0;
BA_ "GenSigSwitchedByIgnition" SG_ 179 EBKV_QBit_Fahrer_bremst 0;
BA_ "GenSigStartValue" SG_ 179 EBKV_QBit_Fahrer_bremst 1;
BA_ "GenSigSendType" SG_ 179 EBKV_QBit_Fahrer_bremst 0;
BA_ "GenSigSwitchedByIgnition" SG_ 179 EBKV_Fahrer_bremst 0;
BA_ "GenSigSendType" SG_ 179 EBKV_Fahrer_bremst 0;
BA_ "GenSigSwitchedByIgnition" SG_ 179 EBKV_Fallback_Freigabe 0;
BA_ "GenSigSendType" SG_ 179 EBKV_Fallback_Freigabe 0;
BA_ "GenSigSwitchedByIgnition" SG_ 179 EBKV_Activate_Fallback_ESP 0;
BA_ "GenSigSendType" SG_ 179 EBKV_Activate_Fallback_ESP 0;
BA_ "GenSigSwitchedByIgnition" SG_ 179 EBKV_Anforderung_HMS 0;
BA_ "GenSigSendType" SG_ 179 EBKV_Anforderung_HMS 0;
BA_ "GenSigSendType" SG_ 179 EBKV_ECD_nicht_verfuegbar 0;
BA_ "Fehlerwert" SG_ 179 EBKV_ECD_Fehler 1;
BA_ "GenSigSendType" SG_ 179 EBKV_ECD_Fehler 0;
BA_ "Fehlerwert" SG_ 179 EBKV_Aussteuerdruck 255;
BA_ "GenSigSwitchedByIgnition" SG_ 179 EBKV_Aussteuerdruck 0;
BA_ "GenSigStartValue" SG_ 179 EBKV_Aussteuerdruck 254;
BA_ "GenSigSendType" SG_ 179 EBKV_Aussteuerdruck 0;
BA_ "Fehlerwert" SG_ 179 EBKV_M_Br_Fahrerwunsch 4095;
BA_ "GenSigStartValue" SG_ 179 EBKV_M_Br_Fahrerwunsch 4094;
BA_ "GenSigSendType" SG_ 179 EBKV_M_Br_Fahrerwunsch 0;
BA_ "GenSigSwitchedByIgnition" SG_ 2617236992 CCP_BMS_CRO_01_Data 0;
BA_ "GenSigFuncType" SG_ 2617236992 CCP_BMS_CRO_01_Data 9;
BA_ "GenSigSwitchedByIgnition" SG_ 2617236993 CCP_BMS_DTO_01_Data 0;
BA_ "GenSigFuncType" SG_ 2617236993 CCP_BMS_DTO_01_Data 9;
BA_ "GenSigSwitchedByIgnition" SG_ 2617130752 CCP_DCDC_HV_02_CRO_01_Data 0;
BA_ "GenSigFuncType" SG_ 2617130752 CCP_DCDC_HV_02_CRO_01_Data 9;
BA_ "GenSigSwitchedByIgnition" SG_ 2617130753 CCP_DCDC_HV_02_DTO_01_Data 0;
BA_ "GenSigFuncType" SG_ 2617130753 CCP_DCDC_HV_02_DTO_01_Data 9;
BA_ "GenSigSwitchedByIgnition" SG_ 2617194240 CCP_Ladegeraet_2_CRO_01_Data 0;
BA_ "GenSigFuncType" SG_ 2617194240 CCP_Ladegeraet_2_CRO_01_Data 9;
BA_ "GenSigSwitchedByIgnition" SG_ 2617194241 CCP_Ladegeraet_2_DTO_01_Data 0;
BA_ "GenSigFuncType" SG_ 2617194241 CCP_Ladegeraet_2_DTO_01_Data 9;
BA_ "GenSigSwitchedByIgnition" SG_ 2617124352 CCP_Ladegeraet_CRO_01_Data 0;
BA_ "GenSigFuncType" SG_ 2617124352 CCP_Ladegeraet_CRO_01_Data 9;
BA_ "GenSigSwitchedByIgnition" SG_ 2617124353 CCP_Ladegeraet_DTO_01_Data 0;
BA_ "GenSigFuncType" SG_ 2617124353 CCP_Ladegeraet_DTO_01_Data 9;
BA_ "GenSigSwitchedByIgnition" SG_ 901 CHA_Ziel_FahrPr_AGA 0;
BA_ "GenSigSendType" SG_ 901 CHA_Ziel_FahrPr_AGA 3;
BA_ "GenSigSwitchedByIgnition" SG_ 901 CHA_Ziel_FahrPr_ESP 0;
BA_ "GenSigSendType" SG_ 901 CHA_Ziel_FahrPr_ESP 3;
BA_ "GenSigSwitchedByIgnition" SG_ 901 CHA_Ziel_FahrPr_Freilauf 0;
BA_ "GenSigSendType" SG_ 901 CHA_Ziel_FahrPr_Freilauf 3;
BA_ "GenSigSwitchedByIgnition" SG_ 901 CHA_Fahrer_Umschaltung 0;
BA_ "GenSigSendType" SG_ 901 CHA_Fahrer_Umschaltung 3;
BA_ "GenSigSwitchedByIgnition" SG_ 901 CHA_Fahrer_Umschaltung_BMA 0;
BA_ "GenSigSendType" SG_ 901 CHA_Fahrer_Umschaltung_BMA 3;
BA_ "GenSigSwitchedByIgnition" SG_ 901 CHA_Ziel_FahrPr_MO 0;
BA_ "GenSigSendType" SG_ 901 CHA_Ziel_FahrPr_MO 3;
BA_ "GenSigSwitchedByIgnition" SG_ 901 CHA_Ziel_FahrPr_GE 0;
BA_ "GenSigSendType" SG_ 901 CHA_Ziel_FahrPr_GE 3;
BA_ "GenSigSwitchedByIgnition" SG_ 901 CHA_Ziel_FahrPr_ALR 0;
BA_ "GenSigSendType" SG_ 901 CHA_Ziel_FahrPr_ALR 3;
BA_ "GenSigSwitchedByIgnition" SG_ 901 CHA_Ziel_FahrPr_MO_BZS 0;
BA_ "GenSigSendType" SG_ 901 CHA_Ziel_FahrPr_MO_BZS 3;
BA_ "GenSigSwitchedByIgnition" SG_ 901 CHA_Ziel_FahrPr_DR 0;
BA_ "GenSigSendType" SG_ 901 CHA_Ziel_FahrPr_DR 3;
BA_ "GenSigSendType" SG_ 901 CHA_Ziel_FahrPr_VAQ 3;
BA_ "GenSigSwitchedByIgnition" SG_ 901 CHA_Ziel_FahrPr_AFS 0;
BA_ "GenSigSendType" SG_ 901 CHA_Ziel_FahrPr_AFS 3;
BA_ "GenSigSwitchedByIgnition" SG_ 901 CHA_Ziel_FahrPr_PreCrash 0;
BA_ "GenSigSendType" SG_ 901 CHA_Ziel_FahrPr_PreCrash 3;
BA_ "GenSigSwitchedByIgnition" SG_ 901 CHA_Ziel_FahrPr_EPS 0;
BA_ "GenSigSendType" SG_ 901 CHA_Ziel_FahrPr_EPS 3;
BA_ "GenSigSwitchedByIgnition" SG_ 901 CHA_Ziel_FahrPr_ACC 0;
BA_ "GenSigSendType" SG_ 901 CHA_Ziel_FahrPr_ACC 3;
BA_ "GenSigSwitchedByIgnition" SG_ 901 CHA_Ziel_FahrPr_SAK 0;
BA_ "GenSigSendType" SG_ 901 CHA_Ziel_FahrPr_SAK 3;
BA_ "GenSigSwitchedByIgnition" SG_ 901 CHA_Ziel_FahrPr_MO_StSt 0;
BA_ "GenSigSendType" SG_ 901 CHA_Ziel_FahrPr_MO_StSt 3;
BA_ "GenSigSwitchedByIgnition" SG_ 1022 CHA_Fahrer_Umschaltung 0;
BA_ "GenSigSendType" SG_ 1022 CHA_Fahrer_Umschaltung 3;
BA_ "GenSigSwitchedByIgnition" SG_ 1022 CHA_Fahrer_Umschaltung_BMA 0;
BA_ "GenSigSendType" SG_ 1022 CHA_Fahrer_Umschaltung_BMA 3;
BA_ "GenSigSwitchedByIgnition" SG_ 1022 CHA_Ziel_FahrPr_Reku_ZwGas 0;
BA_ "GenSigSendType" SG_ 1022 CHA_Ziel_FahrPr_Reku_ZwGas 3;
BA_ "GenSigSendType" SG_ 1022 CHA_Ziel_FahrPr_MO_Freilauf 3;
BA_ "GenSigSwitchedByIgnition" SG_ 1022 CHA_Ziel_FahrPr_BMS 0;
BA_ "GenSigSendType" SG_ 1022 CHA_Ziel_FahrPr_BMS 3;
BA_ "GenSigSwitchedByIgnition" SG_ 1022 CHA_Current_Mode_BMA 0;
BA_ "GenSigSendType" SG_ 1022 CHA_Current_Mode_BMA 3;
BA_ "GenSigSwitchedByIgnition" SG_ 1022 CHA_Ziel_FahrPr_PDC 0;
BA_ "GenSigSendType" SG_ 1022 CHA_Ziel_FahrPr_PDC 3;
BA_ "GenSigSendType" SG_ 1022 CHA_Ziel_FahrPr_HHC 3;
BA_ "GenSigSendType" SG_ 1022 CHA_Ziel_FahrPr_EDS 3;
BA_ "GenSigSwitchedByIgnition" SG_ 1022 CHA_Ziel_FahrPr_PACC 0;
BA_ "GenSigSendType" SG_ 1022 CHA_Ziel_FahrPr_PACC 3;
BA_ "GenSigSwitchedByIgnition" SG_ 1022 CHA_Ziel_FahrPr_AGK 0;
BA_ "GenSigSendType" SG_ 1022 CHA_Ziel_FahrPr_AGK 3;
BA_ "GenSigSwitchedByIgnition" SG_ 2589283686 DC_MV_CALID_CVN_MUX 0;
BA_ "GenSigSendType" SG_ 2589283686 DC_MV_CALID_CVN_MUX 0;
BA_ "GenSigSwitchedByIgnition" SG_ 2589283686 DC_MV_CVN_VLD 0;
BA_ "GenSigSendType" SG_ 2589283686 DC_MV_CVN_VLD 0;
BA_ "GenSigSwitchedByIgnition" SG_ 2589283686 DC_MV_CALID_Index_01 0;
BA_ "GenSigStartValue" SG_ 2589283686 DC_MV_CALID_Index_01 48;
BA_ "GenSigSwitchedByIgnition" SG_ 2589283686 DC_MV_CALID_Index_05 0;
BA_ "GenSigStartValue" SG_ 2589283686 DC_MV_CALID_Index_05 48;
BA_ "GenSigSwitchedByIgnition" SG_ 2589283686 DC_MV_CALID_Index_09 0;
BA_ "GenSigStartValue" SG_ 2589283686 DC_MV_CALID_Index_09 48;
BA_ "GenSigSwitchedByIgnition" SG_ 2589283686 DC_MV_CALID_Index_13 0;
BA_ "GenSigStartValue" SG_ 2589283686 DC_MV_CALID_Index_13 48;
BA_ "GenSigSwitchedByIgnition" SG_ 2589283686 DC_MV_CALID_Index_02 0;
BA_ "GenSigStartValue" SG_ 2589283686 DC_MV_CALID_Index_02 48;
BA_ "GenSigSwitchedByIgnition" SG_ 2589283686 DC_MV_CALID_Index_06 0;
BA_ "GenSigStartValue" SG_ 2589283686 DC_MV_CALID_Index_06 48;
BA_ "GenSigSwitchedByIgnition" SG_ 2589283686 DC_MV_CALID_Index_10 0;
BA_ "GenSigStartValue" SG_ 2589283686 DC_MV_CALID_Index_10 48;
BA_ "GenSigSwitchedByIgnition" SG_ 2589283686 DC_MV_CALID_Index_14 0;
BA_ "GenSigStartValue" SG_ 2589283686 DC_MV_CALID_Index_14 48;
BA_ "GenSigSwitchedByIgnition" SG_ 2589283686 DC_MV_CALID_Index_03 0;
BA_ "GenSigStartValue" SG_ 2589283686 DC_MV_CALID_Index_03 48;
BA_ "GenSigSwitchedByIgnition" SG_ 2589283686 DC_MV_CALID_Index_07 0;
BA_ "GenSigStartValue" SG_ 2589283686 DC_MV_CALID_Index_07 48;
BA_ "GenSigSwitchedByIgnition" SG_ 2589283686 DC_MV_CALID_Index_11 0;
BA_ "GenSigStartValue" SG_ 2589283686 DC_MV_CALID_Index_11 48;
BA_ "GenSigSwitchedByIgnition" SG_ 2589283686 DC_MV_CALID_Index_15 0;
BA_ "GenSigStartValue" SG_ 2589283686 DC_MV_CALID_Index_15 48;
BA_ "GenSigSwitchedByIgnition" SG_ 2589283686 DC_MV_CALID_Index_04 0;
BA_ "GenSigStartValue" SG_ 2589283686 DC_MV_CALID_Index_04 48;
BA_ "GenSigSwitchedByIgnition" SG_ 2589283686 DC_MV_CALID_Index_08 0;
BA_ "GenSigStartValue" SG_ 2589283686 DC_MV_CALID_Index_08 48;
BA_ "GenSigSwitchedByIgnition" SG_ 2589283686 DC_MV_CALID_Index_12 0;
BA_ "GenSigStartValue" SG_ 2589283686 DC_MV_CALID_Index_12 48;
BA_ "GenSigSwitchedByIgnition" SG_ 2589283686 DC_MV_CALID_Index_16 0;
BA_ "GenSigStartValue" SG_ 2589283686 DC_MV_CALID_Index_16 48;
BA_ "GenSigSwitchedByIgnition" SG_ 2589283686 DC_MV_CVN_Byte_1 0;
BA_ "GenSigSwitchedByIgnition" SG_ 2589283686 DC_MV_CVN_Byte_2 0;
BA_ "GenSigSwitchedByIgnition" SG_ 2589283686 DC_MV_CVN_Byte_3 0;
BA_ "GenSigSwitchedByIgnition" SG_ 2589283686 DC_MV_CVN_Byte_4 0;
BA_ "GenSigSwitchedByIgnition" SG_ 2589283393 DC_MV_Komponentenfehler_01 0;
BA_ "GenSigSendType" SG_ 2589283393 DC_MV_Komponentenfehler_01 0;
BA_ "GenSigSwitchedByIgnition" SG_ 2589283393 DC_MV_Komponentenfehler_02 0;
BA_ "GenSigSendType" SG_ 2589283393 DC_MV_Komponentenfehler_02 0;
BA_ "GenSigSwitchedByIgnition" SG_ 2589283393 DC_MV_Komponentenfehler_03 0;
BA_ "GenSigSendType" SG_ 2589283393 DC_MV_Komponentenfehler_03 0;
BA_ "GenSigSwitchedByIgnition" SG_ 2589283393 DC_MV_Komponentenfehler_04 0;
BA_ "GenSigSendType" SG_ 2589283393 DC_MV_Komponentenfehler_04 0;
BA_ "GenSigSwitchedByIgnition" SG_ 2589283393 DC_MV_Komponentenfehler_05 0;
BA_ "GenSigSendType" SG_ 2589283393 DC_MV_Komponentenfehler_05 0;
BA_ "GenSigSwitchedByIgnition" SG_ 2589283393 DC_MV_Komponentenfehler_06 0;
BA_ "GenSigSendType" SG_ 2589283393 DC_MV_Komponentenfehler_06 0;
BA_ "GenSigSwitchedByIgnition" SG_ 2589283393 DC_MV_Komponentenfehler_07 0;
BA_ "GenSigSendType" SG_ 2589283393 DC_MV_Komponentenfehler_07 0;
BA_ "GenSigSwitchedByIgnition" SG_ 2589283393 DC_MV_Komponentenfehler_08 0;
BA_ "GenSigSendType" SG_ 2589283393 DC_MV_Komponentenfehler_08 0;
BA_ "GenSigSwitchedByIgnition" SG_ 2589283393 DC_MV_Komponentenfehler_09 0;
BA_ "GenSigSendType" SG_ 2589283393 DC_MV_Komponentenfehler_09 0;
BA_ "GenSigSwitchedByIgnition" SG_ 2589283393 DC_MV_Komponentenfehler_10 0;
BA_ "GenSigSendType" SG_ 2589283393 DC_MV_Komponentenfehler_10 0;
BA_ "GenSigSwitchedByIgnition" SG_ 2589283393 DC_MV_Komponentenfehler_11 0;
BA_ "GenSigSendType" SG_ 2589283393 DC_MV_Komponentenfehler_11 0;
BA_ "GenSigSwitchedByIgnition" SG_ 2589283393 DC_MV_Komponentenfehler_12 0;
BA_ "GenSigSendType" SG_ 2589283393 DC_MV_Komponentenfehler_12 0;
BA_ "GenSigSwitchedByIgnition" SG_ 2589283393 DC_MV_Komponentenfehler_13 0;
BA_ "GenSigSendType" SG_ 2589283393 DC_MV_Komponentenfehler_13 0;
BA_ "GenSigSwitchedByIgnition" SG_ 2589283393 DC_MV_Komponentenfehler_14 0;
BA_ "GenSigSendType" SG_ 2589283393 DC_MV_Komponentenfehler_14 0;
BA_ "GenSigSwitchedByIgnition" SG_ 2589283393 DC_MV_Komponentenfehler_15 0;
BA_ "GenSigSendType" SG_ 2589283393 DC_MV_Komponentenfehler_15 0;
BA_ "GenSigSwitchedByIgnition" SG_ 2589283393 DC_MV_Komponentenfehler_16 0;
BA_ "GenSigSendType" SG_ 2589283393 DC_MV_Komponentenfehler_16 0;
BA_ "GenSigSwitchedByIgnition" SG_ 2589283393 DC_MV_Komponentenfehler_17 0;
BA_ "GenSigSendType" SG_ 2589283393 DC_MV_Komponentenfehler_17 0;
BA_ "GenSigSwitchedByIgnition" SG_ 2589283393 DC_MV_Komponentenfehler_18 0;
BA_ "GenSigSendType" SG_ 2589283393 DC_MV_Komponentenfehler_18 0;
BA_ "GenSigSwitchedByIgnition" SG_ 2589283393 DC_MV_Komponentenfehler_19 0;
BA_ "GenSigSendType" SG_ 2589283393 DC_MV_Komponentenfehler_19 0;
BA_ "GenSigSwitchedByIgnition" SG_ 2589283393 DC_MV_Komponentenfehler_20 0;
BA_ "GenSigSendType" SG_ 2589283393 DC_MV_Komponentenfehler_20 0;
BA_ "GenSigSwitchedByIgnition" SG_ 2589283393 DC_MV_Komponentenfehler_21 0;
BA_ "GenSigSendType" SG_ 2589283393 DC_MV_Komponentenfehler_21 0;
BA_ "GenSigSwitchedByIgnition" SG_ 2589283393 DC_MV_Komponentenfehler_22 0;
BA_ "GenSigSendType" SG_ 2589283393 DC_MV_Komponentenfehler_22 0;
BA_ "GenSigSwitchedByIgnition" SG_ 2589283393 DC_MV_Komponentenfehler_23 0;
BA_ "GenSigSendType" SG_ 2589283393 DC_MV_Komponentenfehler_23 0;
BA_ "GenSigSwitchedByIgnition" SG_ 2589283393 DC_MV_Komponentenfehler_24 0;
BA_ "GenSigSendType" SG_ 2589283393 DC_MV_Komponentenfehler_24 0;
BA_ "GenSigSwitchedByIgnition" SG_ 2589283393 DC_MV_Komponentenfehler_25 0;
BA_ "GenSigSendType" SG_ 2589283393 DC_MV_Komponentenfehler_25 0;
BA_ "GenSigSwitchedByIgnition" SG_ 2589283393 DC_MV_Komponentenfehler_26 0;
BA_ "GenSigSendType" SG_ 2589283393 DC_MV_Komponentenfehler_26 0;
BA_ "GenSigSwitchedByIgnition" SG_ 2589283393 DC_MV_Komponentenfehler_27 0;
BA_ "GenSigSendType" SG_ 2589283393 DC_MV_Komponentenfehler_27 0;
BA_ "GenSigSwitchedByIgnition" SG_ 2589283393 DC_MV_Komponentenfehler_28 0;
BA_ "GenSigSendType" SG_ 2589283393 DC_MV_Komponentenfehler_28 0;
BA_ "GenSigSwitchedByIgnition" SG_ 2589283393 DC_MV_Komponentenfehler_29 0;
BA_ "GenSigSendType" SG_ 2589283393 DC_MV_Komponentenfehler_29 0;
BA_ "GenSigSwitchedByIgnition" SG_ 2589283393 DC_MV_Komponentenfehler_30 0;
BA_ "GenSigSendType" SG_ 2589283393 DC_MV_Komponentenfehler_30 0;
BA_ "GenSigSwitchedByIgnition" SG_ 2589283393 DC_MV_Komponentenfehler_31 0;
BA_ "GenSigSendType" SG_ 2589283393 DC_MV_Komponentenfehler_31 0;
BA_ "GenSigSwitchedByIgnition" SG_ 2589283393 DC_MV_Komponentenfehler_VLD 0;
BA_ "GenSigSendType" SG_ 2589283393 DC_MV_Komponentenfehler_VLD 0;
BA_ "GenSigSwitchedByIgnition" SG_ 2589283855 DC_MV_Komponentenfehler_32 0;
BA_ "GenSigSendType" SG_ 2589283855 DC_MV_Komponentenfehler_32 0;
BA_ "GenSigSwitchedByIgnition" SG_ 2589283855 DC_MV_Komponentenfehler_33 0;
BA_ "GenSigSendType" SG_ 2589283855 DC_MV_Komponentenfehler_33 0;
BA_ "GenSigSwitchedByIgnition" SG_ 2589283855 DC_MV_Komponentenfehler_34 0;
BA_ "GenSigSendType" SG_ 2589283855 DC_MV_Komponentenfehler_34 0;
BA_ "GenSigSwitchedByIgnition" SG_ 2589283855 DC_MV_Komponentenfehler_35 0;
BA_ "GenSigSendType" SG_ 2589283855 DC_MV_Komponentenfehler_35 0;
BA_ "GenSigSwitchedByIgnition" SG_ 2589283855 DC_MV_Komponentenfehler_36 0;
BA_ "GenSigSendType" SG_ 2589283855 DC_MV_Komponentenfehler_36 0;
BA_ "GenSigSwitchedByIgnition" SG_ 2589283855 DC_MV_Komponentenfehler_37 0;
BA_ "GenSigSendType" SG_ 2589283855 DC_MV_Komponentenfehler_37 0;
BA_ "GenSigSwitchedByIgnition" SG_ 2589283855 DC_MV_Komponentenfehler_38 0;
BA_ "GenSigSendType" SG_ 2589283855 DC_MV_Komponentenfehler_38 0;
BA_ "GenSigSwitchedByIgnition" SG_ 2589283855 DC_MV_Komponentenfehler_39 0;
BA_ "GenSigSendType" SG_ 2589283855 DC_MV_Komponentenfehler_39 0;
BA_ "GenSigSwitchedByIgnition" SG_ 2589283855 DC_MV_Komponentenfehler_40 0;
BA_ "GenSigSendType" SG_ 2589283855 DC_MV_Komponentenfehler_40 0;
BA_ "GenSigSwitchedByIgnition" SG_ 2589283855 DC_MV_Komponentenfehler_41 0;
BA_ "GenSigSendType" SG_ 2589283855 DC_MV_Komponentenfehler_41 0;
BA_ "GenSigSwitchedByIgnition" SG_ 2589283855 DC_MV_Komponentenfehler_42 0;
BA_ "GenSigSendType" SG_ 2589283855 DC_MV_Komponentenfehler_42 0;
BA_ "GenSigSwitchedByIgnition" SG_ 2589283855 DC_MV_Komponentenfehler_43 0;
BA_ "GenSigSendType" SG_ 2589283855 DC_MV_Komponentenfehler_43 0;
BA_ "GenSigSwitchedByIgnition" SG_ 2589283855 DC_MV_Komponentenfehler_44 0;
BA_ "GenSigSendType" SG_ 2589283855 DC_MV_Komponentenfehler_44 0;
BA_ "GenSigSwitchedByIgnition" SG_ 2589283855 DC_MV_Komponentenfehler_45 0;
BA_ "GenSigSendType" SG_ 2589283855 DC_MV_Komponentenfehler_45 0;
BA_ "GenSigSwitchedByIgnition" SG_ 2589283855 DC_MV_Komponentenfehler_46 0;
BA_ "GenSigSendType" SG_ 2589283855 DC_MV_Komponentenfehler_46 0;
BA_ "GenSigSwitchedByIgnition" SG_ 2589283855 DC_MV_Komponentenfehler_47 0;
BA_ "GenSigSendType" SG_ 2589283855 DC_MV_Komponentenfehler_47 0;
BA_ "GenSigSwitchedByIgnition" SG_ 2589283855 DC_MV_Komponentenfehler_48 0;
BA_ "GenSigSendType" SG_ 2589283855 DC_MV_Komponentenfehler_48 0;
BA_ "GenSigSwitchedByIgnition" SG_ 2589283855 DC_MV_Komponentenfehler_49 0;
BA_ "GenSigSendType" SG_ 2589283855 DC_MV_Komponentenfehler_49 0;
BA_ "GenSigSwitchedByIgnition" SG_ 2589283855 DC_MV_Komponentenfehler_50 0;
BA_ "GenSigSendType" SG_ 2589283855 DC_MV_Komponentenfehler_50 0;
BA_ "GenSigSwitchedByIgnition" SG_ 2589283855 DC_MV_Komponentenfehler_51 0;
BA_ "GenSigSendType" SG_ 2589283855 DC_MV_Komponentenfehler_51 0;
BA_ "GenSigSwitchedByIgnition" SG_ 2589283855 DC_MV_Komponentenfehler_52 0;
BA_ "GenSigSendType" SG_ 2589283855 DC_MV_Komponentenfehler_52 0;
BA_ "GenSigSwitchedByIgnition" SG_ 2589283855 DC_MV_Komponentenfehler_53 0;
BA_ "GenSigSendType" SG_ 2589283855 DC_MV_Komponentenfehler_53 0;
BA_ "GenSigSwitchedByIgnition" SG_ 2589283855 DC_MV_Komponentenfehler_54 0;
BA_ "GenSigSendType" SG_ 2589283855 DC_MV_Komponentenfehler_54 0;
BA_ "GenSigSwitchedByIgnition" SG_ 2589283855 DC_MV_Komponentenfehler_55 0;
BA_ "GenSigSendType" SG_ 2589283855 DC_MV_Komponentenfehler_55 0;
BA_ "GenSigSwitchedByIgnition" SG_ 2589283855 DC_MV_Komponentenfehler_56 0;
BA_ "GenSigSendType" SG_ 2589283855 DC_MV_Komponentenfehler_56 0;
BA_ "GenSigSwitchedByIgnition" SG_ 2589283855 DC_MV_Komponentenfehler_57 0;
BA_ "GenSigSendType" SG_ 2589283855 DC_MV_Komponentenfehler_57 0;
BA_ "GenSigSwitchedByIgnition" SG_ 2589283855 DC_MV_Komponentenfehler_58 0;
BA_ "GenSigSendType" SG_ 2589283855 DC_MV_Komponentenfehler_58 0;
BA_ "GenSigSwitchedByIgnition" SG_ 2589283855 DC_MV_Komponentenfehler_59 0;
BA_ "GenSigSendType" SG_ 2589283855 DC_MV_Komponentenfehler_59 0;
BA_ "GenSigSwitchedByIgnition" SG_ 2589283855 DC_MV_Komponentenfehler_60 0;
BA_ "GenSigSendType" SG_ 2589283855 DC_MV_Komponentenfehler_60 0;
BA_ "GenSigSwitchedByIgnition" SG_ 2589283855 DC_MV_Komponentenfehler_61 0;
BA_ "GenSigSendType" SG_ 2589283855 DC_MV_Komponentenfehler_61 0;
BA_ "GenSigSwitchedByIgnition" SG_ 2589283855 DC_MV_Komponentenfehler_62 0;
BA_ "GenSigSendType" SG_ 2589283855 DC_MV_Komponentenfehler_62 0;
BA_REL_ "GenSigTimeoutTime" BU_SG_REL_ Gateway SG_ 1289 BMS_Energieinhalt_HiRes 1000;
BA_REL_ "GenSigTimeoutTime" BU_SG_REL_ Gateway_PAG SG_ 1289 BMS_Energieinhalt_HiRes 1000;
BA_REL_ "GenSigTimeoutTime" BU_SG_REL_ Gateway SG_ 1289 BMS_NutzbarerSOC 1000;
BA_REL_ "GenSigTimeoutTime" BU_SG_REL_ Gateway_PAG SG_ 1289 BMS_NutzbarerSOC 1000;
BA_REL_ "GenSigTimeoutTime" BU_SG_REL_ Ladegeraet_Konzern SG_ 1289 BMS_NutzbarerSOC 1000;
BA_REL_ "GenSigTimeoutTime" BU_SG_REL_ TME SG_ 1289 BMS_NutzbarerSOC 1000;
BA_REL_ "GenSigTimeoutTime" BU_SG_REL_ Gateway SG_ 1289 BMS_NutzbarerEnergieinhalt 1000;
BA_REL_ "GenSigTimeoutTime" BU_SG_REL_ Gateway_PAG SG_ 1289 BMS_NutzbarerEnergieinhalt 1000;
BA_REL_ "GenSigTimeoutTime" BU_SG_REL_ Gateway SG_ 2527679654 BMS_IsoZustand 5000;
BA_REL_ "GenSigTimeoutTime" BU_SG_REL_ Gateway SG_ 2527679654 BMS_IsoFehler 5000;
BA_REL_ "GenSigTimeoutTime" BU_SG_REL_ Gateway SG_ 2527679654 BMS_IstTemperatur_hoechste 5000;
BA_REL_ "GenSigTimeoutTime" BU_SG_REL_ Gateway_PAG SG_ 2527679654 BMS_IstTemperatur_hoechste 5000;
BA_REL_ "GenSigTimeoutTime" BU_SG_REL_ Ladegeraet_Konzern SG_ 2527679654 BMS_IstTemperatur_hoechste 5000;
BA_REL_ "GenSigTimeoutTime" BU_SG_REL_ TME SG_ 2527679654 BMS_IstTemperatur_hoechste 5000;
BA_REL_ "GenSigTimeoutTime" BU_SG_REL_ Gateway SG_ 2527679654 BMS_IstTemperatur_niedrigste 5000;
BA_REL_ "GenSigTimeoutTime" BU_SG_REL_ Gateway_PAG SG_ 2527679654 BMS_IstTemperatur_niedrigste 5000;
BA_REL_ "GenSigTimeoutTime" BU_SG_REL_ Ladegeraet_Konzern SG_ 2527679654 BMS_IstTemperatur_niedrigste 5000;
BA_REL_ "GenSigTimeoutTime" BU_SG_REL_ TME SG_ 2527679654 BMS_IstTemperatur_niedrigste 5000;
BA_REL_ "GenSigTimeoutTime" BU_SG_REL_ Gateway SG_ 2527679654 BMS_IstZellspannung_hoechste 5000;
BA_REL_ "GenSigTimeoutTime" BU_SG_REL_ Gateway_PAG SG_ 2527679654 BMS_IstZellspannung_hoechste 5000;
BA_REL_ "GenSigTimeoutTime" BU_SG_REL_ Ladegeraet_Konzern SG_ 2527679654 BMS_IstZellspannung_hoechste 5000;
BA_REL_ "GenSigTimeoutTime" BU_SG_REL_ Gateway SG_ 2527679654 BMS_IstZellspannung_niedrigste 5000;
BA_REL_ "GenSigTimeoutTime" BU_SG_REL_ Gateway_PAG SG_ 2527679654 BMS_IstZellspannung_niedrigste 5000;
BA_REL_ "GenSigTimeoutTime" BU_SG_REL_ Ladegeraet_Konzern SG_ 2527679654 BMS_IstZellspannung_niedrigste 5000;
BA_REL_ "GenSigTimeoutTime" BU_SG_REL_ Gateway SG_ 2589283637 BMS_Pack_SN_01 5000;
BA_REL_ "GenSigTimeoutTime" BU_SG_REL_ Gateway_PAG SG_ 2589283637 BMS_Pack_SN_01 5000;
BA_REL_ "GenSigTimeoutTime" BU_SG_REL_ Gateway SG_ 2589283637 BMS_Pack_SN_02 5000;
BA_REL_ "GenSigTimeoutTime" BU_SG_REL_ Gateway_PAG SG_ 2589283637 BMS_Pack_SN_02 5000;
BA_REL_ "GenSigTimeoutTime" BU_SG_REL_ Gateway SG_ 2589283637 BMS_Pack_SN_03 5000;
BA_REL_ "GenSigTimeoutTime" BU_SG_REL_ Gateway_PAG SG_ 2589283637 BMS_Pack_SN_03 5000;
BA_REL_ "GenSigTimeoutTime" BU_SG_REL_ Gateway SG_ 2589283637 BMS_Pack_SN_04 5000;
BA_REL_ "GenSigTimeoutTime" BU_SG_REL_ Gateway_PAG SG_ 2589283637 BMS_Pack_SN_04 5000;
BA_REL_ "GenSigTimeoutTime" BU_SG_REL_ Gateway SG_ 2589283637 BMS_Pack_SN_05 5000;
BA_REL_ "GenSigTimeoutTime" BU_SG_REL_ Gateway_PAG SG_ 2589283637 BMS_Pack_SN_05 5000;
BA_REL_ "GenSigTimeoutTime" BU_SG_REL_ Gateway SG_ 2589283637 BMS_Pack_SN_06 5000;
BA_REL_ "GenSigTimeoutTime" BU_SG_REL_ Gateway_PAG SG_ 2589283637 BMS_Pack_SN_06 5000;
BA_REL_ "GenSigTimeoutTime" BU_SG_REL_ Gateway SG_ 2589283637 BMS_Pack_SN_07 5000;
BA_REL_ "GenSigTimeoutTime" BU_SG_REL_ Gateway_PAG SG_ 2589283637 BMS_Pack_SN_07 5000;
BA_REL_ "GenSigTimeoutTime" BU_SG_REL_ Gateway SG_ 2589283637 BMS_Pack_SN_08 5000;
BA_REL_ "GenSigTimeoutTime" BU_SG_REL_ Gateway_PAG SG_ 2589283637 BMS_Pack_SN_08 5000;
BA_REL_ "GenSigTimeoutTime" BU_SG_REL_ Gateway SG_ 2589283638 BMS_Pack_SN_09 5000;
BA_REL_ "GenSigTimeoutTime" BU_SG_REL_ Gateway_PAG SG_ 2589283638 BMS_Pack_SN_09 5000;
BA_REL_ "GenSigTimeoutTime" BU_SG_REL_ Gateway SG_ 2589283638 BMS_Pack_SN_10 5000;
BA_REL_ "GenSigTimeoutTime" BU_SG_REL_ Gateway_PAG SG_ 2589283638 BMS_Pack_SN_10 5000;
BA_REL_ "GenSigTimeoutTime" BU_SG_REL_ Gateway SG_ 2589283638 BMS_Pack_SN_11 5000;
BA_REL_ "GenSigTimeoutTime" BU_SG_REL_ Gateway_PAG SG_ 2589283638 BMS_Pack_SN_11 5000;
BA_REL_ "GenSigTimeoutTime" BU_SG_REL_ Gateway SG_ 2589283638 BMS_Pack_SN_12 5000;
BA_REL_ "GenSigTimeoutTime" BU_SG_REL_ Gateway_PAG SG_ 2589283638 BMS_Pack_SN_12 5000;
BA_REL_ "GenSigTimeoutTime" BU_SG_REL_ Gateway SG_ 2589283638 BMS_Pack_SN_13 5000;
BA_REL_ "GenSigTimeoutTime" BU_SG_REL_ Gateway_PAG SG_ 2589283638 BMS_Pack_SN_13 5000;
BA_REL_ "GenSigTimeoutTime" BU_SG_REL_ Gateway SG_ 2589283638 BMS_Pack_SN_14 5000;
BA_REL_ "GenSigTimeoutTime" BU_SG_REL_ Gateway_PAG SG_ 2589283638 BMS_Pack_SN_14 5000;
BA_REL_ "GenSigTimeoutTime" BU_SG_REL_ Gateway SG_ 2589283638 BMS_Pack_SN_15 5000;
BA_REL_ "GenSigTimeoutTime" BU_SG_REL_ Gateway_PAG SG_ 2589283638 BMS_Pack_SN_15 5000;
BA_REL_ "GenSigTimeoutTime" BU_SG_REL_ Gateway SG_ 1111 BMS_14_CRC 1000;
BA_REL_ "GenSigTimeoutTime" BU_SG_REL_ Gateway_PAG SG_ 1111 BMS_14_CRC 1000;
BA_REL_ "GenSigTimeoutTime" BU_SG_REL_ LE2 SG_ 1111 BMS_14_CRC 1000;
BA_REL_ "GenSigTimeoutTime" BU_SG_REL_ Gateway SG_ 1111 BMS_14_BZ 1000;
BA_REL_ "GenSigTimeoutTime" BU_SG_REL_ Gateway_PAG SG_ 1111 BMS_14_BZ 1000;
BA_REL_ "GenSigTimeoutTime" BU_SG_REL_ LE2 SG_ 1111 BMS_14_BZ 1000;
BA_REL_ "GenSigTimeoutTime" BU_SG_REL_ Gateway SG_ 1111 BMS_Warnung_Stuetzung_NV 1000;
BA_REL_ "GenSigTimeoutTime" BU_SG_REL_ Gateway_PAG SG_ 1111 BMS_Warnung_Stuetzung_NV 1000;
BA_REL_ "GenSigTimeoutTime" BU_SG_REL_ DCDC_HV_02 SG_ 1111 BMS_RIso_GND_HVM 1000;
BA_REL_ "GenSigTimeoutTime" BU_SG_REL_ DCDC_HV_02 SG_ 1111 BMS_RIso_GND_HVP 1000;
BA_REL_ "GenSigTimeoutTime" BU_SG_REL_ Gateway SG_ 1111 BMS_Spannung_ZwKr2 1000;
BA_REL_ "GenSigTimeoutTime" BU_SG_REL_ Gateway_PAG SG_ 1111 BMS_Spannung_ZwKr2 1000;
BA_REL_ "GenSigTimeoutTime" BU_SG_REL_ LE2 SG_ 1111 BMS_Spannung_ZwKr2 1000;
BA_REL_ "GenSigTimeoutTime" BU_SG_REL_ TME SG_ 1111 BMS_Spannung_ZwKr2 1000;
BA_REL_ "GenSigTimeoutTime" BU_SG_REL_ Gateway SG_ 2589283641 BMS_IstTemperaturMin_Sensor_ID 5000;
BA_REL_ "GenSigTimeoutTime" BU_SG_REL_ Gateway_PAG SG_ 2589283641 BMS_IstTemperaturMin_Sensor_ID 5000;
BA_REL_ "GenSigTimeoutTime" BU_SG_REL_ Ladegeraet_Konzern SG_ 2589283641 BMS_IstTemperaturMin_Sensor_ID 5000;
BA_REL_ "GenSigTimeoutTime" BU_SG_REL_ Gateway SG_ 2589283641 BMS_IstTemperaturMax_Sensor_ID 5000;
BA_REL_ "GenSigTimeoutTime" BU_SG_REL_ Gateway_PAG SG_ 2589283641 BMS_IstTemperaturMax_Sensor_ID 5000;
BA_REL_ "GenSigTimeoutTime" BU_SG_REL_ Ladegeraet_Konzern SG_ 2589283641 BMS_IstTemperaturMax_Sensor_ID 5000;
BA_REL_ "GenSigTimeoutTime" BU_SG_REL_ Gateway SG_ 2589283641 BMS_IstTemperaturMin_Modul_ID 5000;
BA_REL_ "GenSigTimeoutTime" BU_SG_REL_ Gateway_PAG SG_ 2589283641 BMS_IstTemperaturMin_Modul_ID 5000;
BA_REL_ "GenSigTimeoutTime" BU_SG_REL_ Ladegeraet_Konzern SG_ 2589283641 BMS_IstTemperaturMin_Modul_ID 5000;
BA_REL_ "GenSigTimeoutTime" BU_SG_REL_ Gateway SG_ 2589283641 BMS_IstTemperaturMax_Modul_ID 5000;
BA_REL_ "GenSigTimeoutTime" BU_SG_REL_ Gateway_PAG SG_ 2589283641 BMS_IstTemperaturMax_Modul_ID 5000;
BA_REL_ "GenSigTimeoutTime" BU_SG_REL_ Ladegeraet_Konzern SG_ 2589283641 BMS_IstTemperaturMax_Modul_ID 5000;
BA_REL_ "GenSigTimeoutTime" BU_SG_REL_ Gateway SG_ 2589283641 BMS_IstZellSpannungMin_Modul_ID 5000;
BA_REL_ "GenSigTimeoutTime" BU_SG_REL_ Gateway_PAG SG_ 2589283641 BMS_IstZellSpannungMin_Modul_ID 5000;
BA_REL_ "GenSigTimeoutTime" BU_SG_REL_ Ladegeraet_Konzern SG_ 2589283641 BMS_IstZellSpannungMin_Modul_ID 5000;
BA_REL_ "GenSigTimeoutTime" BU_SG_REL_ Gateway SG_ 2589283641 BMS_IstZellSpannungMax_Modul_ID 5000;
BA_REL_ "GenSigTimeoutTime" BU_SG_REL_ Gateway_PAG SG_ 2589283641 BMS_IstZellSpannungMax_Modul_ID 5000;
BA_REL_ "GenSigTimeoutTime" BU_SG_REL_ Ladegeraet_Konzern SG_ 2589283641 BMS_IstZellSpannungMax_Modul_ID 5000;
BA_REL_ "GenSigTimeoutTime" BU_SG_REL_ Gateway SG_ 2589283641 BMS_IstZellSpannungMin_Zell_ID 5000;
BA_REL_ "GenSigTimeoutTime" BU_SG_REL_ Gateway_PAG SG_ 2589283641 BMS_IstZellSpannungMin_Zell_ID 5000;
BA_REL_ "GenSigTimeoutTime" BU_SG_REL_ Ladegeraet_Konzern SG_ 2589283641 BMS_IstZellSpannungMin_Zell_ID 5000;
BA_REL_ "GenSigTimeoutTime" BU_SG_REL_ Gateway SG_ 2589283641 BMS_IstZellSpannungMax_Zell_ID 5000;
BA_REL_ "GenSigTimeoutTime" BU_SG_REL_ Gateway_PAG SG_ 2589283641 BMS_IstZellSpannungMax_Zell_ID 5000;
BA_REL_ "GenSigTimeoutTime" BU_SG_REL_ Ladegeraet_Konzern SG_ 2589283641 BMS_IstZellSpannungMax_Zell_ID 5000;
BA_REL_ "GenSigTimeoutTime" BU_SG_REL_ Gateway SG_ 2589283651 BMS_RtmWarnUeberstrom 5000;
BA_REL_ "GenSigTimeoutTime" BU_SG_REL_ Gateway_PAG SG_ 2589283651 BMS_RtmWarnUeberstrom 5000;
BA_REL_ "GenSigTimeoutTime" BU_SG_REL_ Gateway SG_ 2589283651 BMS_RtmWarnPackKommunikation 5000;
BA_REL_ "GenSigTimeoutTime" BU_SG_REL_ Gateway_PAG SG_ 2589283651 BMS_RtmWarnPackKommunikation 5000;
BA_REL_ "GenSigTimeoutTime" BU_SG_REL_ Gateway SG_ 2589283651 BMS_RtmWarnPackUeberladen 5000;
BA_REL_ "GenSigTimeoutTime" BU_SG_REL_ Gateway_PAG SG_ 2589283651 BMS_RtmWarnPackUeberladen 5000;
BA_REL_ "GenSigTimeoutTime" BU_SG_REL_ Gateway SG_ 2589283651 BMS_RtmWarnSocHoch 5000;
BA_REL_ "GenSigTimeoutTime" BU_SG_REL_ Gateway_PAG SG_ 2589283651 BMS_RtmWarnSocHoch 5000;
BA_REL_ "GenSigTimeoutTime" BU_SG_REL_ Gateway SG_ 2589283651 BMS_RtmWarnSocNiedrig 5000;
BA_REL_ "GenSigTimeoutTime" BU_SG_REL_ Gateway_PAG SG_ 2589283651 BMS_RtmWarnSocNiedrig 5000;
BA_REL_ "GenSigTimeoutTime" BU_SG_REL_ Gateway SG_ 2589283651 BMS_RtmWarnSocSprung 5000;
BA_REL_ "GenSigTimeoutTime" BU_SG_REL_ Gateway_PAG SG_ 2589283651 BMS_RtmWarnSocSprung 5000;
BA_REL_ "GenSigTimeoutTime" BU_SG_REL_ Gateway SG_ 2589283651 BMS_RtmWarnTZelleDiff 5000;
BA_REL_ "GenSigTimeoutTime" BU_SG_REL_ Gateway_PAG SG_ 2589283651 BMS_RtmWarnTZelleDiff 5000;
BA_REL_ "GenSigTimeoutTime" BU_SG_REL_ Gateway SG_ 2589283651 BMS_RtmWarnTZelleMax 5000;
BA_REL_ "GenSigTimeoutTime" BU_SG_REL_ Gateway_PAG SG_ 2589283651 BMS_RtmWarnTZelleMax 5000;
BA_REL_ "GenSigTimeoutTime" BU_SG_REL_ Gateway SG_ 2589283651 BMS_RtmWarnTZelleMin 5000;
BA_REL_ "GenSigTimeoutTime" BU_SG_REL_ Gateway_PAG SG_ 2589283651 BMS_RtmWarnTZelleMin 5000;
BA_REL_ "GenSigTimeoutTime" BU_SG_REL_ Gateway SG_ 2589283651 BMS_RtmWarnUPackMax 5000;
BA_REL_ "GenSigTimeoutTime" BU_SG_REL_ Gateway_PAG SG_ 2589283651 BMS_RtmWarnUPackMax 5000;
BA_REL_ "GenSigTimeoutTime" BU_SG_REL_ Gateway SG_ 2589283651 BMS_RtmWarnUPackMin 5000;
BA_REL_ "GenSigTimeoutTime" BU_SG_REL_ Gateway_PAG SG_ 2589283651 BMS_RtmWarnUPackMin 5000;
BA_REL_ "GenSigTimeoutTime" BU_SG_REL_ Gateway SG_ 2589283651 BMS_RtmWarnUZelleMax 5000;
BA_REL_ "GenSigTimeoutTime" BU_SG_REL_ Gateway_PAG SG_ 2589283651 BMS_RtmWarnUZelleMax 5000;
BA_REL_ "GenSigTimeoutTime" BU_SG_REL_ Gateway SG_ 2589283651 BMS_RtmWarnUZelleMin 5000;
BA_REL_ "GenSigTimeoutTime" BU_SG_REL_ Gateway_PAG SG_ 2589283651 BMS_RtmWarnUZelleMin 5000;
BA_REL_ "GenSigTimeoutTime" BU_SG_REL_ Gateway SG_ 2589283651 BMS_RtmWarnZelleZustand 5000;
BA_REL_ "GenSigTimeoutTime" BU_SG_REL_ Gateway_PAG SG_ 2589283651 BMS_RtmWarnZelleZustand 5000;
BA_REL_ "GenSigTimeoutTime" BU_SG_REL_ Ladegeraet_Konzern SG_ 2589283666 BMS_LadegrenzeAntw_SOC 5000;
BA_REL_ "GenSigTimeoutTime" BU_SG_REL_ Ladegeraet_Konzern SG_ 2589283666 BMS_EnergieAntw_Zaehler 5000;
BA_REL_ "GenSigTimeoutTime" BU_SG_REL_ Ladegeraet_Konzern SG_ 2589283666 BMS_EnergieAntw_Energie 5000;
BA_REL_ "GenSigTimeoutTime" BU_SG_REL_ Ladegeraet_Konzern SG_ 2589283666 BMS_LadegrenzeAntw_Leistung 5000;
BA_REL_ "GenSigTimeoutTime" BU_SG_REL_ Ladegeraet_Konzern SG_ 2589283666 BMS_LadegrenzeAntw_Zaehler 5000;
BA_REL_ "GenSigTimeoutTime" BU_SG_REL_ Gateway SG_ 2463978763 BMS_30_CRC 1000;
BA_REL_ "GenSigTimeoutTime" BU_SG_REL_ Gateway_PAG SG_ 2463978763 BMS_30_CRC 1000;
BA_REL_ "GenSigTimeoutTime" BU_SG_REL_ Gateway SG_ 2463978763 BMS_30_BZ 1000;
BA_REL_ "GenSigTimeoutTime" BU_SG_REL_ Gateway_PAG SG_ 2463978763 BMS_30_BZ 1000;
BA_REL_ "GenSigTimeoutTime" BU_SG_REL_ Gateway SG_ 2463978763 BMS_Ueberspannung_Zelle 1000;
BA_REL_ "GenSigTimeoutTime" BU_SG_REL_ Gateway_PAG SG_ 2463978763 BMS_Ueberspannung_Zelle 1000;
BA_REL_ "GenSigTimeoutTime" BU_SG_REL_ Ladegeraet_Konzern SG_ 1400 BMS_DC_01_CRC 5000;
BA_REL_ "GenSigTimeoutTime" BU_SG_REL_ Ladegeraet_Konzern SG_ 1400 BMS_DC_01_BZ 5000;
BA_REL_ "GenSigTimeoutTime" BU_SG_REL_ Ladegeraet_Konzern SG_ 1400 BMS_Status_DCLS 5000;
BA_REL_ "GenSigTimeoutTime" BU_SG_REL_ Ladegeraet_Konzern SG_ 1400 BMS_DCLS_Spannung 5000;
BA_REL_ "GenSigTimeoutTime" BU_SG_REL_ Ladegeraet_Konzern SG_ 1400 BMS_DCLS_MaxLadeStrom 5000;
BA_REL_ "GenSigTimeoutTime" BU_SG_REL_ Gateway SG_ 397 BMS_MV_01_CRC 500;
BA_REL_ "GenSigTimeoutTime" BU_SG_REL_ Gateway_PAG SG_ 397 BMS_MV_01_CRC 500;
BA_REL_ "GenSigTimeoutTime" BU_SG_REL_ Gateway SG_ 397 BMS_MV_01_BZ 500;
BA_REL_ "GenSigTimeoutTime" BU_SG_REL_ Gateway_PAG SG_ 397 BMS_MV_01_BZ 500;
BA_REL_ "GenSigTimeoutTime" BU_SG_REL_ DCDC_IHEV SG_ 397 BMS_MV_IstStrom 500;
BA_REL_ "GenSigTimeoutTime" BU_SG_REL_ Gateway SG_ 397 BMS_MV_IstStrom 500;
BA_REL_ "GenSigTimeoutTime" BU_SG_REL_ Gateway_PAG SG_ 397 BMS_MV_IstStrom 500;
BA_REL_ "GenSigTimeoutTime" BU_SG_REL_ DCDC_IHEV SG_ 397 BMS_MV_IstSpannung 500;
BA_REL_ "GenSigTimeoutTime" BU_SG_REL_ Gateway SG_ 397 BMS_MV_IstSpannung 500;
BA_REL_ "GenSigTimeoutTime" BU_SG_REL_ Gateway_PAG SG_ 397 BMS_MV_IstSpannung 500;
BA_REL_ "GenSigTimeoutTime" BU_SG_REL_ Gateway SG_ 397 BMS_MV_SOC_HiRes 500;
BA_REL_ "GenSigTimeoutTime" BU_SG_REL_ Gateway_PAG SG_ 397 BMS_MV_SOC_HiRes 500;
BA_REL_ "GenSigTimeoutTime" BU_SG_REL_ Gateway SG_ 419 BMS_MV_02_CRC 500;
BA_REL_ "GenSigTimeoutTime" BU_SG_REL_ Gateway_PAG SG_ 419 BMS_MV_02_CRC 500;
BA_REL_ "GenSigTimeoutTime" BU_SG_REL_ Gateway SG_ 419 BMS_MV_02_BZ 500;
BA_REL_ "GenSigTimeoutTime" BU_SG_REL_ Gateway_PAG SG_ 419 BMS_MV_02_BZ 500;
BA_REL_ "GenSigTimeoutTime" BU_SG_REL_ DCDC_IHEV SG_ 419 BMS_MV_MaxDyn_EntladeStrom 500;
BA_REL_ "GenSigTimeoutTime" BU_SG_REL_ Gateway SG_ 419 BMS_MV_MaxDyn_EntladeStrom 500;
BA_REL_ "GenSigTimeoutTime" BU_SG_REL_ Gateway_PAG SG_ 419 BMS_MV_MaxDyn_EntladeStrom 500;
BA_REL_ "GenSigTimeoutTime" BU_SG_REL_ Gateway SG_ 419 BMS_MV_MaxDyn_LadeStrom 500;
BA_REL_ "GenSigTimeoutTime" BU_SG_REL_ Gateway_PAG SG_ 419 BMS_MV_MaxDyn_LadeStrom 500;
BA_REL_ "GenSigTimeoutTime" BU_SG_REL_ Gateway SG_ 419 BMS_MV_Min_EntladeSpannung 500;
BA_REL_ "GenSigTimeoutTime" BU_SG_REL_ Gateway_PAG SG_ 419 BMS_MV_Min_EntladeSpannung 500;
BA_REL_ "GenSigTimeoutTime" BU_SG_REL_ Gateway SG_ 419 BMS_MV_MinDynEntladeSpannung 500;
BA_REL_ "GenSigTimeoutTime" BU_SG_REL_ Gateway_PAG SG_ 419 BMS_MV_MinDynEntladeSpannung 500;
BA_REL_ "GenSigTimeoutTime" BU_SG_REL_ Gateway SG_ 419 BMS_MV_MinDyn_LadeSpannung 500;
BA_REL_ "GenSigTimeoutTime" BU_SG_REL_ Gateway_PAG SG_ 419 BMS_MV_MinDyn_LadeSpannung 500;
BA_REL_ "GenSigTimeoutTime" BU_SG_REL_ Gateway SG_ 871 BMS_MV_03_CRC 1000;
BA_REL_ "GenSigTimeoutTime" BU_SG_REL_ Gateway_PAG SG_ 871 BMS_MV_03_CRC 1000;
BA_REL_ "GenSigTimeoutTime" BU_SG_REL_ Gateway SG_ 871 BMS_MV_03_BZ 1000;
BA_REL_ "GenSigTimeoutTime" BU_SG_REL_ Gateway_PAG SG_ 871 BMS_MV_03_BZ 1000;
BA_REL_ "GenSigTimeoutTime" BU_SG_REL_ Gateway SG_ 871 BMS_MV_Max_LadeSpannung 1000;
BA_REL_ "GenSigTimeoutTime" BU_SG_REL_ Gateway_PAG SG_ 871 BMS_MV_Max_LadeSpannung 1000;
BA_REL_ "GenSigTimeoutTime" BU_SG_REL_ Gateway SG_ 871 BMS_MV_MaxPred_LadeStrom 1000;
BA_REL_ "GenSigTimeoutTime" BU_SG_REL_ Gateway_PAG SG_ 871 BMS_MV_MaxPred_LadeStrom 1000;
BA_REL_ "GenSigTimeoutTime" BU_SG_REL_ Gateway SG_ 871 BMS_MV_Leistungsreduzierung 1000;
BA_REL_ "GenSigTimeoutTime" BU_SG_REL_ Gateway_PAG SG_ 871 BMS_MV_Leistungsreduzierung 1000;
BA_REL_ "GenSigTimeoutTime" BU_SG_REL_ Gateway SG_ 1443 BMS_MV_04_CRC 5000;
BA_REL_ "GenSigTimeoutTime" BU_SG_REL_ Gateway_PAG SG_ 1443 BMS_MV_04_CRC 5000;
BA_REL_ "GenSigTimeoutTime" BU_SG_REL_ Gateway SG_ 1443 BMS_MV_04_BZ 5000;
BA_REL_ "GenSigTimeoutTime" BU_SG_REL_ Gateway_PAG SG_ 1443 BMS_MV_04_BZ 5000;
BA_REL_ "GenSigTimeoutTime" BU_SG_REL_ DCDC_IHEV SG_ 1443 BMS_MV_IstModus 5000;
BA_REL_ "GenSigTimeoutTime" BU_SG_REL_ Gateway SG_ 1443 BMS_MV_IstModus 5000;
BA_REL_ "GenSigTimeoutTime" BU_SG_REL_ Gateway_PAG SG_ 1443 BMS_MV_IstModus 5000;
BA_REL_ "GenSigTimeoutTime" BU_SG_REL_ Gateway SG_ 1443 BMS_MV_FehlerStatus 5000;
BA_REL_ "GenSigTimeoutTime" BU_SG_REL_ Gateway_PAG SG_ 1443 BMS_MV_FehlerStatus 5000;
BA_REL_ "GenSigTimeoutTime" BU_SG_REL_ TME SG_ 2589283412 BMS_MV_Temperierung_Anf 5000;
BA_REL_ "GenSigTimeoutTime" BU_SG_REL_ Gateway SG_ 2589283412 BMS_MV_Speichertechnologie 5000;
BA_REL_ "GenSigTimeoutTime" BU_SG_REL_ Gateway_PAG SG_ 2589283412 BMS_MV_Speichertechnologie 5000;
BA_REL_ "GenSigTimeoutTime" BU_SG_REL_ TME SG_ 2589283412 BMS_MV_Temp_Epsilon 5000;
BA_REL_ "GenSigTimeoutTime" BU_SG_REL_ TME SG_ 2589283412 BMS_MV_Soll_PWM_Pumpe 5000;
BA_REL_ "GenSigTimeoutTime" BU_SG_REL_ DCDC_IHEV SG_ 2589283412 BMS_MV_Temperatur 5000;
BA_REL_ "GenSigTimeoutTime" BU_SG_REL_ Gateway SG_ 2589283412 BMS_MV_Temperatur 5000;
BA_REL_ "GenSigTimeoutTime" BU_SG_REL_ Gateway_PAG SG_ 2589283412 BMS_MV_Temperatur 5000;
BA_REL_ "GenSigTimeoutTime" BU_SG_REL_ TME SG_ 2589283412 BMS_MV_Temperatur 5000;
BA_REL_ "GenSigTimeoutTime" BU_SG_REL_ TME SG_ 2589283412 BMS_MV_IstVorlaufTemperatur 5000;
BA_REL_ "GenSigTimeoutTime" BU_SG_REL_ TME SG_ 2589283412 BMS_MV_SollVolumenstrom 5000;
BA_REL_ "GenSigTimeoutTime" BU_SG_REL_ TME SG_ 2589283412 BMS_MV_SollVorlauftemperatur 5000;
BA_REL_ "GenSigTimeoutTime" BU_SG_REL_ TME SG_ 2589283412 BMS_MV_IstRuecklaufTemperatur 5000;
BA_REL_ "GenSigTimeoutTime" BU_SG_REL_ Gateway SG_ 2589283608 BMS_MV_Energieinhalt 5000;
BA_REL_ "GenSigTimeoutTime" BU_SG_REL_ Gateway_PAG SG_ 2589283608 BMS_MV_Energieinhalt 5000;
BA_REL_ "GenSigTimeoutTime" BU_SG_REL_ Gateway SG_ 2589283608 BMS_MV_MaxEnergieinhalt 5000;
BA_REL_ "GenSigTimeoutTime" BU_SG_REL_ Gateway_PAG SG_ 2589283608 BMS_MV_MaxEnergieinhalt 5000;
BA_REL_ "GenSigTimeoutTime" BU_SG_REL_ Gateway SG_ 2589283606 BMS_MV_SOC_Kaltstart 5000;
BA_REL_ "GenSigTimeoutTime" BU_SG_REL_ Gateway_PAG SG_ 2589283606 BMS_MV_SOC_Kaltstart 5000;
BA_REL_ "GenSigTimeoutTime" BU_SG_REL_ Gateway SG_ 2589283606 BMS_MV_max_Grenz_SOC 5000;
BA_REL_ "GenSigTimeoutTime" BU_SG_REL_ Gateway_PAG SG_ 2589283606 BMS_MV_max_Grenz_SOC 5000;
BA_REL_ "GenSigTimeoutTime" BU_SG_REL_ Gateway SG_ 499 BMS_NV_01_CRC 1000;
BA_REL_ "GenSigTimeoutTime" BU_SG_REL_ Gateway_PAG SG_ 499 BMS_NV_01_CRC 1000;
BA_REL_ "GenSigTimeoutTime" BU_SG_REL_ Gateway SG_ 499 BMS_NV_01_BZ 1000;
BA_REL_ "GenSigTimeoutTime" BU_SG_REL_ Gateway_PAG SG_ 499 BMS_NV_01_BZ 1000;
BA_REL_ "GenSigTimeoutTime" BU_SG_REL_ Gateway SG_ 499 BMS_NV_FMAus_Info 1000;
BA_REL_ "GenSigTimeoutTime" BU_SG_REL_ Gateway_PAG SG_ 499 BMS_NV_FMAus_Info 1000;
BA_REL_ "GenSigTimeoutTime" BU_SG_REL_ Gateway SG_ 499 BMS_NV_IstStrom 1000;
BA_REL_ "GenSigTimeoutTime" BU_SG_REL_ Gateway_PAG SG_ 499 BMS_NV_IstStrom 1000;
BA_REL_ "GenSigTimeoutTime" BU_SG_REL_ Gateway SG_ 499 BMS_NV_IstSpannung 1000;
BA_REL_ "GenSigTimeoutTime" BU_SG_REL_ Gateway_PAG SG_ 499 BMS_NV_IstSpannung 1000;
BA_REL_ "GenSigTimeoutTime" BU_SG_REL_ Gateway SG_ 499 BMS_NV_BatterieAb 1000;
BA_REL_ "GenSigTimeoutTime" BU_SG_REL_ Gateway_PAG SG_ 499 BMS_NV_BatterieAb 1000;
BA_REL_ "GenSigTimeoutTime" BU_SG_REL_ Gateway SG_ 499 BMS_NV_IstModus 1000;
BA_REL_ "GenSigTimeoutTime" BU_SG_REL_ Gateway_PAG SG_ 499 BMS_NV_IstModus 1000;
BA_REL_ "GenSigTimeoutTime" BU_SG_REL_ Gateway SG_ 504 BMS_NV_Fehlerstatus 1000;
BA_REL_ "GenSigTimeoutTime" BU_SG_REL_ Gateway_PAG SG_ 504 BMS_NV_Fehlerstatus 1000;
BA_REL_ "GenSigTimeoutTime" BU_SG_REL_ Gateway SG_ 504 BMS_NV_Qe_LI_Inhalt 1000;
BA_REL_ "GenSigTimeoutTime" BU_SG_REL_ Gateway_PAG SG_ 504 BMS_NV_Qe_LI_Inhalt 1000;
BA_REL_ "GenSigTimeoutTime" BU_SG_REL_ Gateway SG_ 504 BMS_NV_IMaxStart 1000;
BA_REL_ "GenSigTimeoutTime" BU_SG_REL_ Gateway_PAG SG_ 504 BMS_NV_IMaxStart 1000;
BA_REL_ "GenSigTimeoutTime" BU_SG_REL_ Gateway SG_ 504 BMS_NV_Ri_Batterie 1000;
BA_REL_ "GenSigTimeoutTime" BU_SG_REL_ Gateway_PAG SG_ 504 BMS_NV_Ri_Batterie 1000;
BA_REL_ "GenSigTimeoutTime" BU_SG_REL_ Gateway SG_ 504 BMS_NV_SOC 1000;
BA_REL_ "GenSigTimeoutTime" BU_SG_REL_ Gateway_PAG SG_ 504 BMS_NV_SOC 1000;
BA_REL_ "GenSigTimeoutTime" BU_SG_REL_ Gateway SG_ 504 BMS_NV_UMinStart 1000;
BA_REL_ "GenSigTimeoutTime" BU_SG_REL_ Gateway_PAG SG_ 504 BMS_NV_UMinStart 1000;
BA_REL_ "GenSigTimeoutTime" BU_SG_REL_ Gateway SG_ 874 BMS_NV_Max_LadeStrom 5000;
BA_REL_ "GenSigTimeoutTime" BU_SG_REL_ Gateway_PAG SG_ 874 BMS_NV_Max_LadeStrom 5000;
BA_REL_ "GenSigTimeoutTime" BU_SG_REL_ Gateway SG_ 874 BMS_NV_Max_EntladeStrom 5000;
BA_REL_ "GenSigTimeoutTime" BU_SG_REL_ Gateway_PAG SG_ 874 BMS_NV_Max_EntladeStrom 5000;
BA_REL_ "GenSigTimeoutTime" BU_SG_REL_ Gateway SG_ 874 BMS_NV_Max_LadeSpannung 5000;
BA_REL_ "GenSigTimeoutTime" BU_SG_REL_ Gateway_PAG SG_ 874 BMS_NV_Max_LadeSpannung 5000;
BA_REL_ "GenSigTimeoutTime" BU_SG_REL_ Gateway SG_ 874 BMS_NV_Diagnose_Anf 5000;
BA_REL_ "GenSigTimeoutTime" BU_SG_REL_ Gateway_PAG SG_ 874 BMS_NV_Diagnose_Anf 5000;
BA_REL_ "GenSigTimeoutTime" BU_SG_REL_ Gateway SG_ 874 BMS_NV_Min_EntladeSpannung 5000;
BA_REL_ "GenSigTimeoutTime" BU_SG_REL_ Gateway_PAG SG_ 874 BMS_NV_Min_EntladeSpannung 5000;
BA_REL_ "GenSigTimeoutTime" BU_SG_REL_ Gateway SG_ 874 BMS_NV_Kapazitaet_akt 5000;
BA_REL_ "GenSigTimeoutTime" BU_SG_REL_ Gateway_PAG SG_ 874 BMS_NV_Kapazitaet_akt 5000;
BA_REL_ "GenSigTimeoutTime" BU_SG_REL_ Gateway SG_ 874 BMS_NV_Temperatur 5000;
BA_REL_ "GenSigTimeoutTime" BU_SG_REL_ Gateway_PAG SG_ 874 BMS_NV_Temperatur 5000;
BA_REL_ "GenSigTimeoutTime" BU_SG_REL_ Gateway SG_ 2463978664 BMS_NV_Polspannung 1000;
BA_REL_ "GenSigTimeoutTime" BU_SG_REL_ Gateway_PAG SG_ 2463978664 BMS_NV_Polspannung 1000;
BA_REL_ "GenSigTimeoutTime" BU_SG_REL_ Gateway SG_ 2463978720 BMS_NV_05_CRC 1000;
BA_REL_ "GenSigTimeoutTime" BU_SG_REL_ Gateway_PAG SG_ 2463978720 BMS_NV_05_CRC 1000;
BA_REL_ "GenSigTimeoutTime" BU_SG_REL_ Gateway SG_ 2463978720 BMS_NV_05_BZ 1000;
BA_REL_ "GenSigTimeoutTime" BU_SG_REL_ Gateway_PAG SG_ 2463978720 BMS_NV_05_BZ 1000;
BA_REL_ "GenSigTimeoutTime" BU_SG_REL_ Gateway SG_ 2463978720 BMS_NV_SollPred_EntladeSpannung 1000;
BA_REL_ "GenSigTimeoutTime" BU_SG_REL_ Gateway_PAG SG_ 2463978720 BMS_NV_SollPred_EntladeSpannung 1000;
BA_REL_ "GenSigTimeoutTime" BU_SG_REL_ Gateway SG_ 2463978720 BMS_NV_SollDyn_EntladeSpannung 1000;
BA_REL_ "GenSigTimeoutTime" BU_SG_REL_ Gateway_PAG SG_ 2463978720 BMS_NV_SollDyn_EntladeSpannung 1000;
BA_REL_ "GenSigTimeoutTime" BU_SG_REL_ Gateway SG_ 2463978720 BMS_NV_IstDyn_EntladeStrom 1000;
BA_REL_ "GenSigTimeoutTime" BU_SG_REL_ Gateway_PAG SG_ 2463978720 BMS_NV_IstDyn_EntladeStrom 1000;
BA_REL_ "GenSigTimeoutTime" BU_SG_REL_ Gateway SG_ 2463978720 BMS_NV_IstPred_EntladeStrom 1000;
BA_REL_ "GenSigTimeoutTime" BU_SG_REL_ Gateway_PAG SG_ 2463978720 BMS_NV_IstPred_EntladeStrom 1000;
BA_REL_ "GenSigTimeoutTime" BU_SG_REL_ TME SG_ 901 CHA_Ziel_FahrPr_MO_BZS 5000;
BA_REL_ "GenSigTimeoutTime" BU_SG_REL_ BMC_MLBevo SG_ 1022 CHA_Ziel_FahrPr_BMS 5000;
VAL_ 1289 BMS_Energieinhalt_HiRes 32766 "Init" 32767 "Fehler" ;
VAL_ 1289 BMS_MaxEnergieinhalt_HiRes 32766 "Init" 32767 "Fehler" ;
VAL_ 1289 BMS_NutzbarerSOC 254 "Init" 255 "Fehler" ;
VAL_ 1289 BMS_NutzbarerEnergieinhalt 4094 "Init" 4095 "Fehler" ;
VAL_ 1289 BMS_Pred_Entladeperformance 126 "Init" 127 "Fehler" ;
VAL_ 1289 BMS_Pred_Ladeperformance 126 "Init" 127 "Fehler" ;
VAL_ 2527679654 BMS_IsoZustand 0 "Init" 1 "groesser_Schwelle_1" 2 "kleiner_Schwelle_1_gesamt" 3 "kleiner_Schwelle_1_intern" 4 "kleiner_Schwelle_2_gesamt" 5 "kleiner_Schwelle_2_intern" 6 "kein_Messwert" 7 "Messung_aktiv" ;
VAL_ 2527679654 BMS_IsoFehler 0 "Init" 1 "kein_IsoFehler" 2 "IsoFehler_Schwelle_1" 3 "IsoFehler_Schwelle_2" 4 "IWU_defekt" 5 "reserviert" 6 "reserviert" 7 "reserviert" ;
VAL_ 2527679654 BMS_IstTemperatur_hoechste 253 "reserviert" 254 "Init" 255 "Fehler" ;
VAL_ 2527679654 BMS_IstTemperatur_niedrigste 253 "reserviert" 254 "Init" 255 "Fehler" ;
VAL_ 2527679654 BMS_IstZellspannung_hoechste 4092 "reserviert" 4093 "reserviert" 4094 "Init" 4095 "Fehler" ;
VAL_ 2527679654 BMS_IstZellspannung_niedrigste 4092 "reserviert" 4093 "reserviert" 4094 "Init" 4095 "Fehler" ;
VAL_ 2589283637 BMS_Pack_SN_01 255 "Init" ;
VAL_ 2589283637 BMS_Pack_SN_02 255 "Init" ;
VAL_ 2589283637 BMS_Pack_SN_03 255 "Init" ;
VAL_ 2589283637 BMS_Pack_SN_04 255 "Init" ;
VAL_ 2589283637 BMS_Pack_SN_05 255 "Init" ;
VAL_ 2589283637 BMS_Pack_SN_06 255 "Init" ;
VAL_ 2589283637 BMS_Pack_SN_07 255 "Init" ;
VAL_ 2589283637 BMS_Pack_SN_08 255 "Init" ;
VAL_ 2589283638 BMS_Pack_SN_09 255 "Init" ;
VAL_ 2589283638 BMS_Pack_SN_10 255 "Init" ;
VAL_ 2589283638 BMS_Pack_SN_11 255 "Init" ;
VAL_ 2589283638 BMS_Pack_SN_12 255 "Init" ;
VAL_ 2589283638 BMS_Pack_SN_13 255 "Init" ;
VAL_ 2589283638 BMS_Pack_SN_14 255 "Init" ;
VAL_ 2589283638 BMS_Pack_SN_15 255 "Init" ;
VAL_ 2589283638 BMS_Pack_SN_16 255 "Init" ;
VAL_ 1111 BMS_Warnung_Stuetzung_NV 0 "Stuetzung_iO" 1 "Stuetzung_niO" 6 "Init" 7 "Fehler" ;
VAL_ 1111 BMS_RIso_GND_HVM 4094 "Init" 4095 "Fehler" ;
VAL_ 1111 BMS_RIso_GND_HVP 4094 "Init" 4095 "Fehler" ;
VAL_ 1111 BMS_Spannung_ZwKr2 2046 "Init" 2047 "Fehler" ;
VAL_ 2589283877 BMS_Pack_SN_17 255 "Init" ;
VAL_ 2589283877 BMS_Pack_SN_18 255 "Init" ;
VAL_ 2589283877 BMS_Pack_SN_19 255 "Init" ;
VAL_ 2589283877 BMS_Pack_SN_20 255 "Init" ;
VAL_ 2589283877 BMS_Pack_SN_21 255 "Init" ;
VAL_ 2589283877 BMS_Pack_SN_22 255 "Init" ;
VAL_ 2589283877 BMS_Pack_SN_23 255 "Init" ;
VAL_ 2589283877 BMS_Pack_SN_24 255 "Init" ;
VAL_ 2589283641 BMS_IstTemperaturMin_Sensor_ID 31 "Init" ;
VAL_ 2589283641 BMS_IstTemperaturMax_Sensor_ID 31 "Init" ;
VAL_ 2589283641 BMS_IstTemperaturMin_Modul_ID 255 "Init" ;
VAL_ 2589283641 BMS_IstTemperaturMax_Modul_ID 255 "Init" ;
VAL_ 2589283641 BMS_IstZellSpannungMin_Modul_ID 255 "Init" ;
VAL_ 2589283641 BMS_IstZellSpannungMax_Modul_ID 255 "Init" ;
VAL_ 2589283641 BMS_IstZellSpannungMin_Zell_ID 255 "Init" ;
VAL_ 2589283641 BMS_IstZellSpannungMax_Zell_ID 255 "Init" ;
VAL_ 2589283651 BMS_RtmWarnUeberstrom 0 "kein_Fehler" 1 "Fehler_Stufe_1" 2 "Fehler_Stufe_2" 3 "Fehler_Stufe_3" 4 "reserviert" 5 "reserviert" 6 "reserviert" 7 "reserviert" ;
VAL_ 2589283651 BMS_RtmWarnPackKommunikation 0 "kein_Fehler" 1 "Fehler_Stufe_1" 2 "Fehler_Stufe_2" 3 "Fehler_Stufe_3" 4 "reserviert" 5 "reserviert" 6 "reserviert" 7 "reserviert" ;
VAL_ 2589283651 BMS_RtmWarnPackUeberladen 0 "kein_Fehler" 1 "Fehler_Stufe_1" 2 "Fehler_Stufe_2" 3 "Fehler_Stufe_3" 4 "reserviert" 5 "reserviert" 6 "reserviert" 7 "reserviert" ;
VAL_ 2589283651 BMS_RtmWarnSocHoch 0 "kein_Fehler" 1 "Fehler_Stufe_1" 2 "Fehler_Stufe_2" 3 "Fehler_Stufe_3" 4 "reserviert" 5 "reserviert" 6 "reserviert" 7 "reserviert" ;
VAL_ 2589283651 BMS_RtmWarnSocNiedrig 0 "kein_Fehler" 1 "Fehler_Stufe_1" 2 "Fehler_Stufe_2" 3 "Fehler_Stufe_3" 4 "reserviert" 5 "reserviert" 6 "reserviert" 7 "reserviert" ;
VAL_ 2589283651 BMS_RtmWarnSocSprung 0 "kein_Fehler" 1 "Fehler_Stufe_1" 2 "Fehler_Stufe_2" 3 "Fehler_Stufe_3" 4 "reserviert" 5 "reserviert" 6 "reserviert" 7 "reserviert" ;
VAL_ 2589283651 BMS_RtmWarnTZelleDiff 0 "kein_Fehler" 1 "Fehler_Stufe_1" 2 "Fehler_Stufe_2" 3 "Fehler_Stufe_3" 4 "reserviert" 5 "reserviert" 6 "reserviert" 7 "reserviert" ;
VAL_ 2589283651 BMS_RtmWarnTZelleMax 0 "kein_Fehler" 1 "Fehler_Stufe_1" 2 "Fehler_Stufe_2" 3 "Fehler_Stufe_3" 4 "reserviert" 5 "reserviert" 6 "reserviert" 7 "reserviert" ;
VAL_ 2589283651 BMS_RtmWarnTZelleMin 0 "kein_Fehler" 1 "Fehler_Stufe_1" 2 "Fehler_Stufe_2" 3 "Fehler_Stufe_3" 4 "reserviert" 5 "reserviert" 6 "reserviert" 7 "reserviert" ;
VAL_ 2589283651 BMS_RtmWarnUPackMax 0 "kein_Fehler" 1 "Fehler_Stufe_1" 2 "Fehler_Stufe_2" 3 "Fehler_Stufe_3" 4 "reserviert" 5 "reserviert" 6 "reserviert" 7 "reserviert" ;
VAL_ 2589283651 BMS_RtmWarnUPackMin 0 "kein_Fehler" 1 "Fehler_Stufe_1" 2 "Fehler_Stufe_2" 3 "Fehler_Stufe_3" 4 "reserviert" 5 "reserviert" 6 "reserviert" 7 "reserviert" ;
VAL_ 2589283651 BMS_RtmWarnUZelleMax 0 "kein_Fehler" 1 "Fehler_Stufe_1" 2 "Fehler_Stufe_2" 3 "Fehler_Stufe_3" 4 "reserviert" 5 "reserviert" 6 "reserviert" 7 "reserviert" ;
VAL_ 2589283651 BMS_RtmWarnUZelleMin 0 "kein_Fehler" 1 "Fehler_Stufe_1" 2 "Fehler_Stufe_2" 3 "Fehler_Stufe_3" 4 "reserviert" 5 "reserviert" 6 "reserviert" 7 "reserviert" ;
VAL_ 2589283651 BMS_RtmWarnZelleZustand 0 "kein_Fehler" 1 "Fehler_Stufe_1" 2 "Fehler_Stufe_2" 3 "Fehler_Stufe_3" 4 "reserviert" 5 "reserviert" 6 "reserviert" 7 "reserviert" ;
VAL_ 2589283652 BMS_Energie_Entladung 65534 "Init" 65535 "Fehler" ;
VAL_ 2589283652 BMS_Energie_Ladung 65534 "Init" 65535 "Fehler" ;
VAL_ 2589283878 BMS_Pack_SN_25 255 "Init" ;
VAL_ 2589283878 BMS_Pack_SN_26 255 "Init" ;
VAL_ 2589283666 BMS_LadegrenzeAntw_SOC 126 "Init" 127 "Fehler" ;
VAL_ 2589283666 BMS_EnergieAntw_Zaehler 14 "Init" 15 "Fehler" ;
VAL_ 2589283666 BMS_EnergieAntw_Energie 2046 "Init" 2047 "Fehler" ;
VAL_ 2589283666 BMS_LadegrenzeAntw_Leistung 4094 "Init" 4095 "Fehler" ;
VAL_ 2589283666 BMS_LadegrenzeAntw_Zaehler 14 "Init" 15 "Fehler" ;
VAL_ 2463978763 BMS_Ueberspannung_Zelle 0 "keine_Ueberspannung" 1 "Ueberspannung" 6 "Init" 7 "Fehler" ;
VAL_ 1400 BMS_Status_DCLS 0 "inaktiv" 1 "i_O" 2 "n_i_O" 3 "aktiv" ;
VAL_ 1400 BMS_DCLS_Spannung 1022 "Init" 1023 "Fehler" ;
VAL_ 1400 BMS_DCLS_MaxLadeStrom 510 "Init" 511 "Fehler" ;
VAL_ 397 BMS_MV_IstStrom 4094 "Init" 4095 "Fehler" ;
VAL_ 397 BMS_MV_IstSpannung 254 "Init" 255 "Fehler" ;
VAL_ 397 BMS_MV_SOC_HiRes 2046 "Init" 2047 "Fehler" ;
VAL_ 419 BMS_MV_MaxDyn_EntladeStrom 2046 "Init" 2047 "Fehler" ;
VAL_ 419 BMS_MV_MaxDyn_LadeStrom 2046 "Init" 2047 "Fehler" ;
VAL_ 419 BMS_MV_Min_EntladeSpannung 254 "Init" 255 "Fehler" ;
VAL_ 419 BMS_MV_MinDynEntladeSpannung 254 "Init" ;
VAL_ 419 BMS_MV_MinDyn_LadeSpannung 254 "Init" ;
VAL_ 871 BMS_MV_Max_LadeSpannung 254 "Init" 255 "Fehler" ;
VAL_ 871 BMS_MV_MaxPred_EntladeStrom 2046 "Init" 2047 "Fehler" ;
VAL_ 871 BMS_MV_MaxPred_LadeStrom 2046 "Init" 2047 "Fehler" ;
VAL_ 871 BMS_MV_MinPred_EntladeSpannung 254 "Init" ;
VAL_ 871 BMS_MV_MinPred_LadeSpannung 254 "Init" ;
VAL_ 871 BMS_MV_Leistungsreduzierung 0 "inaktiv" 1 "aktiv" ;
VAL_ 1443 BMS_MV_OBD_Lampe_Anf 0 "Init" 1 "MIL_Request" ;
VAL_ 1443 BMS_MV_IstModus 0 "stStdBy" 1 "stMV" 5 "Error_Batt" 7 "stInit" ;
VAL_ 1443 BMS_MV_FehlerStatus 0 "Komponente_IO" 3 "Vorwarnung_KompFkt" 4 "Keine_KompFkt_Uebertemperatur" 5 "Eingeschr_KompFkt_Leistungsred" 6 "Keine_Komponentenfunktion" 7 "Init" ;
VAL_ 2589283412 BMS_MV_Temperierung_Anf 0 "hoher_Kuehlbedarf" 1 "mittlerer_Kuehlbedarf" 2 "niedriger_Kuehlbedarf" 3 "kein_Temperierungsbedarf_Init" 4 "niedriger_Heizbedarf" 5 "mittlerer_Heizbedarf" 6 "hoher_Heizbedarf" 7 "Umwaelzungsbedarf" ;
VAL_ 2589283412 BMS_MV_Speichertechnologie 0 "Technologie_0" 1 "Technologie_1" 2 "Technologie_2" 3 "Technologie_3" 4 "Technologie_4" 5 "Technologie_5" 6 "Technologie_6" 7 "Technologie_unbekannt" ;
VAL_ 2589283412 BMS_MV_Soll_PWM_Pumpe 15 "Init" ;
VAL_ 2589283412 BMS_MV_Temperatur 254 "Init" 255 "Fehler" ;
VAL_ 2589283412 BMS_MV_IstVorlaufTemperatur 254 "Init" 255 "Fehler" ;
VAL_ 2589283412 BMS_MV_SollVolumenstrom 62 "Init" 63 "Fehler" ;
VAL_ 2589283412 BMS_MV_SollVorlauftemperatur 254 "Init" 255 "Fehler" ;
VAL_ 2589283412 BMS_MV_IstRuecklaufTemperatur 254 "Init" 255 "Fehler" ;
VAL_ 2589283608 BMS_MV_Energieinhalt 2046 "Init" 2047 "Fehler" ;
VAL_ 2589283608 BMS_MV_MaxEnergieinhalt 2046 "Init" 2047 "Fehler" ;
VAL_ 2589283606 BMS_MV_SOC_Kaltstart 2046 "Init" 2047 "Fehler" ;
VAL_ 2589283606 BMS_MV_max_Grenz_SOC 31 "Init" ;
VAL_ 1021 BMS_MV_Pred_Entladeperformance 126 "Init" 127 "Fehler" ;
VAL_ 1021 BMS_MV_Pred_Ladeperformance 126 "Init" 127 "Fehler" ;
VAL_ 499 BMS_NV_FMAus_Info 0 "Motorlauf_langfristig_nicht_notwendig_FMAus_freigabe" 1 "Motoranlauf_nicht_zwingend_notwendig_Stoppverbot_keine_Startanforderung" 2 "Motoranlauf_zwingend_notwendig_Startanforderung" 3 "Systemfehler" ;
VAL_ 499 BMS_NV_TE_Status 0 "Trennelement_offen" 1 "Trennelement_garantiert_geschlossen" 2 "Trennelement_geschlossen" 3 "Trennelement_geschlossen_Mindestzeit" ;
VAL_ 499 BMS_NV_IstStrom 262142 "Init" 262143 "Fehler" ;
VAL_ 499 BMS_NV_IstSpannung 16382 "Init" 16383 "Fehler" ;
VAL_ 499 BMS_NV_StSt_Nutzbare_Ladung 254 "Init" 255 "Fehler" ;
VAL_ 499 BMS_NV_BatterieAb 0 "Batterie_nicht_ab" 1 "Batterie_ab" ;
VAL_ 499 BMS_NV_IstModus 0 "TE_offen" 1 "TE_geschlossen" 2 "Fehler" 3 "Init" ;
VAL_ 504 BMS_NV_Fehlerstatus 0 "Komponente_IO" 1 "ImmediatelyEmergencyOff" 2 "FastEmergencyOff" 3 "ReducedBatteryPerformance" 7 "Init" ;
VAL_ 504 BMS_NV_Qe_LI_Inhalt 4001 "Out_of_Range" 4094 "Init" 4095 "Fehler" ;
VAL_ 504 BMS_NV_IMaxStart 254 "Init" 255 "Fehler" ;
VAL_ 504 BMS_NV_Ri_Batterie 254 "Init" 255 "Fehler" ;
VAL_ 504 BMS_NV_SOC 254 "Init" 255 "Fehler" ;
VAL_ 504 BMS_NV_UMinStart 254 "Init" 255 "Fehler" ;
VAL_ 874 BMS_NV_Max_LadeStrom 1022 "Init" 1023 "Fehler" ;
VAL_ 874 BMS_NV_Max_EntladeStrom 1022 "Init" 1023 "Fehler" ;
VAL_ 874 BMS_NV_Max_LadeSpannung 62 "Init" 63 "Fehler" ;
VAL_ 874 BMS_NV_Diagnose_Anf 0 "keine_Massnahme_noetig" 1 "Anforderung_Stufe_1" 2 "Anforderung_Stufe_2" 3 "Anforderung_Stufe_3" 7 "Init" ;
VAL_ 874 BMS_NV_Min_EntladeSpannung 62 "Init" 63 "Fehler" ;
VAL_ 874 BMS_NV_Kapazitaet_akt 510 "Init" 511 "Fehler" ;
VAL_ 874 BMS_NV_Temperatur 254 "Init" 255 "Fehler" ;
VAL_ 2463978664 BMS_NV_Polspannung 510 "Init" 511 "Fehler" ;
VAL_ 2463978720 BMS_NV_SollPred_EntladeSpannung 254 "Init" 255 "Fehler" ;
VAL_ 2463978720 BMS_NV_SollDyn_EntladeSpannung 254 "Init" 255 "Fehler" ;
VAL_ 2463978720 BMS_NV_IstDyn_EntladeStrom 2046 "Init" 2047 "Fehler" ;
VAL_ 2463978720 BMS_NV_IstPred_EntladeStrom 2046 "Init" 2047 "Fehler" ;
VAL_ 179 EBKV_Generatorsollmoment 4094 "Init" 4095 "Fehler" ;
VAL_ 179 EBKV_Bremspedalweg 0 "Init" 255 "Fehler" ;
VAL_ 179 EBKV_Status 0 "nicht_initialisiert_oder_aus" 1 "Hochlaufphase" 2 "bereit" 3 "eBKV_Diagnose" 4 "Ausfall_aktiver_Speicher" 5 "Ausfall_eBKV" 6 "Ausfall_eBKV_HEV" 7 "Fehler" ;
VAL_ 179 EBKV_QBit_Fahrer_bremst 0 "gueltiger_Wert" 1 "Ersatz_Init_oder_Fehlerwert" ;
VAL_ 179 EBKV_Fahrer_bremst 0 "Fahrer_bremst_nicht_selbst" 1 "Fahrer_will_selbst_bremsen" ;
VAL_ 179 EBKV_Fallback_Freigabe 0 "keine_Freigabe" 1 "Freigabe" ;
VAL_ 179 EBKV_Activate_Fallback_ESP 0 "Rueckfallebene_nicht_aktiv" 1 "Rueckfallebene_aktiv" ;
VAL_ 179 EBKV_Anforderung_HMS 0 "keine_Anforderung" 1 "halten" 2 "parken" 3 "halten_Standby" 4 "anfahren" 5 "Loesen_ueber_Rampe" ;
VAL_ 179 EBKV_ECD_nicht_verfuegbar 0 "verfuegbar" 1 "nicht_verfuegbar" ;
VAL_ 179 EBKV_ECD_Fehler 0 "kein_Fehler" 1 "Fehler" ;
VAL_ 179 EBKV_Aussteuerdruck 251 "Aussteuerdruck_VKM_Start" 252 "Aussteuerdruck_Nachlauf_Phase1" 253 "Aussteuerdruck_Nachlauf_Phase2" 254 "Init" 255 "Fehler" ;
VAL_ 179 EBKV_M_Br_Fahrerwunsch 4094 "Init" 4095 "Fehler" ;
VAL_ 901 CHA_Ziel_FahrPr_AGA 0 "keine_Funktion" 1 "Programm_1" 2 "Programm_2" 3 "Programm_3" 4 "Programm_4" 5 "Programm_5" 6 "Programm_6" 7 "Programm_7" 8 "Programm_8" 9 "Programm_9" 10 "Programm_10" 11 "Programm_11" 12 "Programm_12" 13 "Programm_13" 14 "Programm_14" 15 "Programm_15" ;
VAL_ 901 CHA_Ziel_FahrPr_ESP 0 "keine_Funktion" 1 "Programm_1" 2 "Programm_2" 3 "Programm_3" 4 "Programm_4" 5 "Programm_5" 6 "Programm_6" 7 "Programm_7" 8 "Programm_8" 9 "Programm_9" 10 "Programm_10" 11 "Programm_11" 12 "Programm_12" 13 "Programm_13" 14 "Programm_14" 15 "Programm_15" ;
VAL_ 901 CHA_Ziel_FahrPr_Freilauf 0 "keine_Funktion" 1 "Programm_1" 2 "Programm_2" 3 "Programm_3" 4 "Programm_4" 5 "Programm_5" 6 "Programm_6" 7 "Programm_7" 8 "Programm_8" 9 "Programm_9" 10 "Programm_10" 11 "Programm_11" 12 "Programm_12" 13 "Programm_13" 14 "Programm_14" 15 "Programm_15" ;
VAL_ 901 CHA_Fahrer_Umschaltung 0 "keine_oder_automatische_Umschaltung" 1 "manuelle_Umschaltung" ;
VAL_ 901 CHA_Fahrer_Umschaltung_BMA 0 "keine_oder_autom_Umschaltung" 1 "manuelle_Umschaltung" ;
VAL_ 901 CHA_Ziel_FahrPr_MO 0 "keine_Funktion" 1 "Programm_1" 2 "Programm_2" 3 "Programm_3" 4 "Programm_4" 5 "Programm_5" 6 "Programm_6" 7 "Programm_7" 8 "Programm_8" 9 "Programm_9" 10 "Programm_10" 11 "Programm_11" 12 "Programm_12" 13 "Programm_13" 14 "Programm_14" 15 "Programm_15" ;
VAL_ 901 CHA_Ziel_FahrPr_GE 0 "keine_Funktion" 1 "Programm_1" 2 "Programm_2" 3 "Programm_3" 4 "Programm_4" 5 "Programm_5" 6 "Programm_6" 7 "Programm_7" 8 "Programm_8" 9 "Programm_9" 10 "Programm_10" 11 "Programm_11" 12 "Programm_12" 13 "Programm_13" 14 "Programm_14" 15 "Programm_15" ;
VAL_ 901 CHA_Ziel_FahrPr_ALR 0 "keine_Funktion" 1 "Programm_1" 2 "Programm_2" 3 "Programm_3" 4 "Programm_4" 5 "Programm_5" 6 "Programm_6" 7 "Programm_7" 8 "Programm_8" 9 "Programm_9" 10 "Programm_10" 11 "Programm_11" 12 "Programm_12" 13 "Programm_13" 14 "Programm_14" 15 "Programm_15" ;
VAL_ 901 CHA_Ziel_FahrPr_MO_BZS 0 "keine_Funktion" 1 "Programm_1" 2 "Programm_2" 3 "Programm_3" 4 "Programm_4" 5 "Programm_5" 6 "Programm_6" 7 "Programm_7" 8 "Programm_8" 9 "Programm_9" 10 "Programm_10" 11 "Programm_11" 12 "Programm_12" 13 "Programm_13" 14 "Programm_14" 15 "Programm_15" ;
VAL_ 901 CHA_Ziel_FahrPr_DR 0 "keine_Funktion" 1 "Programm_1" 2 "Programm_2" 3 "Programm_3" 4 "Programm_4" 5 "Programm_5" 6 "Programm_6" 7 "Programm_7" 8 "Programm_8" 9 "Programm_9" 10 "Programm_10" 11 "Programm_11" 12 "Programm_12" 13 "Programm_13" 14 "Programm_14" 15 "Programm_15" ;
VAL_ 901 CHA_Ziel_FahrPr_VAQ 0 "keine_Funktion" 1 "Programm_1" 2 "Programm_2" 3 "Programm_3" 4 "Programm_4" 5 "Programm_5" 6 "Programm_6" 7 "Programm_7" 8 "Programm_8" 9 "Programm_9" 10 "Programm_10" 11 "Programm_11" 12 "Programm_12" 13 "Programm_13" 14 "Programm_14" 15 "Programm_15" ;
VAL_ 901 CHA_Ziel_FahrPr_AFS 0 "keine_Funktion" 1 "Programm_1" 2 "Programm_2" 3 "Programm_3" 4 "Programm_4" 5 "Programm_5" 6 "Programm_6" 7 "Programm_7" 8 "Programm_8" 9 "Programm_9" 10 "Programm_10" 11 "Programm_11" 12 "Programm_12" 13 "Programm_13" 14 "Programm_14" 15 "Programm_15" ;
VAL_ 901 CHA_Ziel_FahrPr_PreCrash 0 "keine_Funktion" 1 "Programm_1" 2 "Programm_2" 3 "Programm_3" 4 "Programm_4" 5 "Programm_5" 6 "Programm_6" 7 "Programm_7" 8 "Programm_8" 9 "Programm_9" 10 "Programm_10" 11 "Programm_11" 12 "Programm_12" 13 "Programm_13" 14 "Programm_14" 15 "Programm_15" ;
VAL_ 901 CHA_Ziel_FahrPr_EPS 0 "keine_Funktion" 1 "Programm_1" 2 "Programm_2" 3 "Programm_3" 4 "Programm_4" 5 "Programm_5" 6 "Programm_6" 7 "Programm_7" 8 "Programm_8" 9 "Programm_9" 10 "Programm_10" 11 "Programm_11" 12 "Programm_12" 13 "Programm_13" 14 "Programm_14" 15 "Programm_15" ;
VAL_ 901 CHA_Ziel_FahrPr_ACC 0 "keine_Funktion" 1 "Programm_1" 2 "Programm_2" 3 "Programm_3" 4 "Programm_4" 5 "Programm_5" 6 "Programm_6" 7 "Programm_7" 8 "Programm_8" 9 "Programm_9" 10 "Programm_10" 11 "Programm_11" 12 "Programm_12" 13 "Programm_13" 14 "Programm_14" 15 "Programm_15" ;
VAL_ 901 CHA_Ziel_FahrPr_SAK 0 "keine_Funktion" 1 "Programm_1" 2 "Programm_2" 3 "Programm_3" 4 "Programm_4" 5 "Programm_5" 6 "Programm_6" 7 "Programm_7" 8 "Programm_8" 9 "Programm_9" 10 "Programm_10" 11 "Programm_11" 12 "Programm_12" 13 "Programm_13" 14 "Programm_14" 15 "Programm_15" ;
VAL_ 901 CHA_Ziel_FahrPr_MO_StSt 0 "keine_Funktion" 1 "Programm_1" 2 "Programm_2" 3 "Programm_3" 4 "Programm_4" 5 "Programm_5" 6 "Programm_6" 7 "Programm_7" 8 "Programm_8" 9 "Programm_9" 10 "Programm_10" 11 "Programm_11" 12 "Programm_12" 13 "Programm_13" 14 "Programm_14" 15 "Programm_15" ;
VAL_ 1022 CHA_Fahrer_Umschaltung 0 "keine_oder_automatische_Umschaltung" 1 "manuelle_Umschaltung" ;
VAL_ 1022 CHA_Fahrer_Umschaltung_BMA 0 "keine_oder_autom_Umschaltung" 1 "manuelle_Umschaltung" ;
VAL_ 1022 CHA_Ziel_FahrPr_Reku_ZwGas 0 "kein_Funktion" 1 "Programm_1" 2 "Programm_2" 3 "Programm_3" 4 "Programm_4" 5 "Programm_5" 6 "Programm_6" 7 "Programm_7" 8 "Programm_8" 9 "Programm_9" 10 "Programm_10" 11 "Programm_11" 12 "Programm_12" 13 "Programm_13" 14 "Programm_14" 15 "Programm_15" ;
VAL_ 1022 CHA_Ziel_FahrPr_MO_Freilauf 0 "keine_Funktion" 1 "Programm_1" 2 "Programm_2" 3 "Programm_3" 4 "Programm_4" 5 "Programm_5" 6 "Programm_6" 7 "Programm_7" 8 "Programm_8" 9 "Programm_9" 10 "Programm_10" 11 "Programm_11" 12 "Programm_12" 13 "Programm_13" 14 "Programm_14" 15 "Programm_15" ;
VAL_ 1022 CHA_Ziel_FahrPr_BMS 0 "keine_Funktion" 1 "Programm_1" 2 "Programm_2" 3 "Programm_3" 4 "Programm_4" 5 "Programm_5" 6 "Programm_6" 7 "Programm_7" 8 "Programm_8" 9 "Programm_9" 10 "Programm_10" 11 "Programm_11" 12 "Programm_12" 13 "Programm_13" 14 "Programm_14" 15 "Programm_15" ;
VAL_ 1022 CHA_Current_Mode_BMA 0 "keine_Funktion" 1 "Programm_1" 2 "Programm_2" 3 "Programm_3" 4 "Programm_4" 5 "Programm_5" 6 "Programm_6" 7 "Programm_7" 8 "Programm_8" 9 "Programm_9" 10 "Programm_10" 11 "Programm_11" 12 "Programm_12" 13 "Programm_13" 14 "Programm_14" 15 "Programm_15" ;
VAL_ 1022 CHA_Ziel_FahrPr_PDC 0 "keine_Funktion" 1 "Programm_1" 2 "Programm_2" 3 "Programm_3" 4 "Programm_4" 5 "Programm_5" 6 "Programm_6" 7 "Programm_7" 8 "Programm_8" 9 "Programm_9" 10 "Programm_10" 11 "Programm_11" 12 "Programm_12" 13 "Programm_13" 14 "Programm_14" 15 "Programm_15" ;
VAL_ 1022 CHA_Ziel_FahrPr_HHC 0 "keine_Funktion" 1 "Programm_1" 2 "Programm_2" 3 "Programm_3" 4 "Programm_4" 5 "Programm_5" 6 "Programm_6" 7 "Programm_7" 8 "Programm_8" 9 "Programm_9" 10 "Programm_10" 11 "Programm_11" 12 "Programm_12" 13 "Programm_13" 14 "Programm_14" 15 "Programm_15" ;
VAL_ 1022 CHA_Ziel_FahrPr_EDS 0 "keine_Funktion" 1 "Programm_1" 2 "Programm_2" 3 "Programm_3" 4 "Programm_4" 5 "Programm_5" 6 "Programm_6" 7 "Programm_7" 8 "Programm_8" 9 "Programm_9" 10 "Programm_10" 11 "Programm_11" 12 "Programm_12" 13 "Programm_13" 14 "Programm_14" 15 "Programm_15" ;
VAL_ 1022 CHA_Ziel_FahrPr_PACC 0 "keine_Funktion" 1 "Programm_1" 2 "Programm_2" 3 "Programm_3" 4 "Programm_4" 5 "Programm_5" 6 "Programm_6" 7 "Programm_7" 8 "Programm_8" 9 "Programm_9" 10 "Programm_10" 11 "Programm_11" 12 "Programm_12" 13 "Programm_13" 14 "Programm_14" 15 "Programm_15" ;
VAL_ 1022 CHA_Ziel_FahrPr_AGK 0 "keine_Funktion" 1 "Programm_1" 2 "Programm_2" 3 "Programm_3" 4 "Programm_4" 5 "Programm_5" 6 "Programm_6" 7 "Programm_7" 8 "Programm_8" 9 "Programm_9" 10 "Programm_10" 11 "Programm_11" 12 "Programm_12" 13 "Programm_13" 14 "Programm_14" 15 "Programm_15" ;
VAL_ 2589283686 DC_MV_CVN_VLD 0 "ungueltig" 1 "gueltig" ;
VAL_ 2589283686 DC_MV_CALID_Index_01 48 "Init" ;
VAL_ 2589283686 DC_MV_CALID_Index_05 48 "Init" ;
VAL_ 2589283686 DC_MV_CALID_Index_09 48 "Init" ;
VAL_ 2589283686 DC_MV_CALID_Index_13 48 "Init" ;
VAL_ 2589283686 DC_MV_CALID_Index_02 48 "Init" ;
VAL_ 2589283686 DC_MV_CALID_Index_06 48 "Init" ;
VAL_ 2589283686 DC_MV_CALID_Index_10 48 "Init" ;
VAL_ 2589283686 DC_MV_CALID_Index_14 48 "Init" ;
VAL_ 2589283686 DC_MV_CALID_Index_03 48 "Init" ;
VAL_ 2589283686 DC_MV_CALID_Index_07 48 "Init" ;
VAL_ 2589283686 DC_MV_CALID_Index_11 48 "Init" ;
VAL_ 2589283686 DC_MV_CALID_Index_15 48 "Init" ;
VAL_ 2589283686 DC_MV_CALID_Index_04 48 "Init" ;
VAL_ 2589283686 DC_MV_CALID_Index_08 48 "Init" ;
VAL_ 2589283686 DC_MV_CALID_Index_12 48 "Init" ;
VAL_ 2589283686 DC_MV_CALID_Index_16 48 "Init" ;
VAL_ 2589283686 DC_MV_CVN_Byte_1 0 "Init" ;
VAL_ 2589283686 DC_MV_CVN_Byte_2 0 "Init" ;
VAL_ 2589283686 DC_MV_CVN_Byte_3 0 "Init" ;
VAL_ 2589283686 DC_MV_CVN_Byte_4 0 "Init" ;
VAL_ 2589283393 DC_MV_Komponentenfehler_01 0 "TstNotComplThisOpCycle_Init" 1 "TstComplThisOpCycle_Pass" 2 "TstCmplThisCycle_Pass_TimeElapse" 3 "TstComplThisOpCycle_FAIL" ;
VAL_ 2589283393 DC_MV_Komponentenfehler_02 0 "TstNotComplThisOpCycle_Init" 1 "TstComplThisOpCycle_Pass" 2 "TstCmplThisCycle_Pass_TimeElapse" 3 "TstComplThisOpCycle_FAIL" ;
VAL_ 2589283393 DC_MV_Komponentenfehler_03 0 "TstNotComplThisOpCycle_Init" 1 "TstComplThisOpCycle_Pass" 2 "TstCmplThisCycle_Pass_TimeElapse" 3 "TstComplThisOpCycle_FAIL" ;
VAL_ 2589283393 DC_MV_Komponentenfehler_04 0 "TstNotComplThisOpCycle_Init" 1 "TstComplThisOpCycle_Pass" 2 "TstCmplThisCycle_Pass_TimeElapse" 3 "TstComplThisOpCycle_FAIL" ;
VAL_ 2589283393 DC_MV_Komponentenfehler_05 0 "TstNotComplThisOpCycle_Init" 1 "TstComplThisOpCycle_Pass" 2 "TstCmplThisCycle_Pass_TimeElapse" 3 "TstComplThisOpCycle_FAIL" ;
VAL_ 2589283393 DC_MV_Komponentenfehler_06 0 "TstNotComplThisOpCycle_Init" 1 "TstComplThisOpCycle_Pass" 2 "TstCmplThisCycle_Pass_TimeElapse" 3 "TstComplThisOpCycle_FAIL" ;
VAL_ 2589283393 DC_MV_Komponentenfehler_07 0 "TstNotComplThisOpCycle_Init" 1 "TstComplThisOpCycle_Pass" 2 "TstCmplThisCycle_Pass_TimeElapse" 3 "TstComplThisOpCycle_FAIL" ;
VAL_ 2589283393 DC_MV_Komponentenfehler_08 0 "TstNotComplThisOpCycle_Init" 1 "TstComplThisOpCycle_Pass" 2 "TstCmplThisCycle_Pass_TimeElapse" 3 "TstComplThisOpCycle_FAIL" ;
VAL_ 2589283393 DC_MV_Komponentenfehler_09 0 "TstNotComplThisOpCycle_Init" 1 "TstComplThisOpCycle_Pass" 2 "TstCmplThisCycle_Pass_TimeElapse" 3 "TstComplThisOpCycle_FAIL" ;
VAL_ 2589283393 DC_MV_Komponentenfehler_10 0 "TstNotComplThisOpCycle_Init" 1 "TstComplThisOpCycle_Pass" 2 "TstCmplThisCycle_Pass_TimeElapse" 3 "TstComplThisOpCycle_FAIL" ;
VAL_ 2589283393 DC_MV_Komponentenfehler_11 0 "TstNotComplThisOpCycle_Init" 1 "TstComplThisOpCycle_Pass" 2 "TstCmplThisCycle_Pass_TimeElapse" 3 "TstComplThisOpCycle_FAIL" ;
VAL_ 2589283393 DC_MV_Komponentenfehler_12 0 "TstNotComplThisOpCycle_Init" 1 "TstComplThisOpCycle_Pass" 2 "TstCmplThisCycle_Pass_TimeElapse" 3 "TstComplThisOpCycle_FAIL" ;
VAL_ 2589283393 DC_MV_Komponentenfehler_13 0 "TstNotComplThisOpCycle_Init" 1 "TstComplThisOpCycle_Pass" 2 "TstCmplThisCycle_Pass_TimeElapse" 3 "TstComplThisOpCycle_FAIL" ;
VAL_ 2589283393 DC_MV_Komponentenfehler_14 0 "TstNotComplThisOpCycle_Init" 1 "TstComplThisOpCycle_Pass" 2 "TstCmplThisCycle_Pass_TimeElapse" 3 "TstComplThisOpCycle_FAIL" ;
VAL_ 2589283393 DC_MV_Komponentenfehler_15 0 "TstNotComplThisOpCycle_Init" 1 "TstComplThisOpCycle_Pass" 2 "TstCmplThisCycle_Pass_TimeElapse" 3 "TstComplThisOpCycle_FAIL" ;
VAL_ 2589283393 DC_MV_Komponentenfehler_16 0 "TstNotComplThisOpCycle_Init" 1 "TstComplThisOpCycle_Pass" 2 "TstCmplThisCycle_Pass_TimeElapse" 3 "TstComplThisOpCycle_FAIL" ;
VAL_ 2589283393 DC_MV_Komponentenfehler_17 0 "TstNotComplThisOpCycle_Init" 1 "TstComplThisOpCycle_Pass" 2 "TstCmplThisCycle_Pass_TimeElapse" 3 "TstComplThisOpCycle_FAIL" ;
VAL_ 2589283393 DC_MV_Komponentenfehler_18 0 "TstNotComplThisOpCycle_Init" 1 "TstComplThisOpCycle_Pass" 2 "TstCmplThisCycle_Pass_TimeElapse" 3 "TstComplThisOpCycle_FAIL" ;
VAL_ 2589283393 DC_MV_Komponentenfehler_19 0 "TstNotComplThisOpCycle_Init" 1 "TstComplThisOpCycle_Pass" 2 "TstCmplThisCycle_Pass_TimeElapse" 3 "TstComplThisOpCycle_FAIL" ;
VAL_ 2589283393 DC_MV_Komponentenfehler_20 0 "TstNotComplThisOpCycle_Init" 1 "TstComplThisOpCycle_Pass" 2 "TstCmplThisCycle_Pass_TimeElapse" 3 "TstComplThisOpCycle_FAIL" ;
VAL_ 2589283393 DC_MV_Komponentenfehler_21 0 "TstNotComplThisOpCycle_Init" 1 "TstComplThisOpCycle_Pass" 2 "TstCmplThisCycle_Pass_TimeElapse" 3 "TstComplThisOpCycle_FAIL" ;
VAL_ 2589283393 DC_MV_Komponentenfehler_22 0 "TstNotComplThisOpCycle_Init" 1 "TstComplThisOpCycle_Pass" 2 "TstCmplThisCycle_Pass_TimeElapse" 3 "TstComplThisOpCycle_FAIL" ;
VAL_ 2589283393 DC_MV_Komponentenfehler_23 0 "TstNotComplThisOpCycle_Init" 1 "TstComplThisOpCycle_Pass" 2 "TstCmplThisCycle_Pass_TimeElapse" 3 "TstComplThisOpCycle_FAIL" ;
VAL_ 2589283393 DC_MV_Komponentenfehler_24 0 "TstNotComplThisOpCycle_Init" 1 "TstComplThisOpCycle_Pass" 2 "TstCmplThisCycle_Pass_TimeElapse" 3 "TstComplThisOpCycle_FAIL" ;
VAL_ 2589283393 DC_MV_Komponentenfehler_25 0 "TstNotComplThisOpCycle_Init" 1 "TstComplThisOpCycle_Pass" 2 "TstCmplThisCycle_Pass_TimeElapse" 3 "TstComplThisOpCycle_FAIL" ;
VAL_ 2589283393 DC_MV_Komponentenfehler_26 0 "TstNotComplThisOpCycle_Init" 1 "TstComplThisOpCycle_Pass" 2 "TstCmplThisCycle_Pass_TimeElapse" 3 "TstComplThisOpCycle_FAIL" ;
VAL_ 2589283393 DC_MV_Komponentenfehler_27 0 "TstNotComplThisOpCycle_Init" 1 "TstComplThisOpCycle_Pass" 2 "TstCmplThisCycle_Pass_TimeElapse" 3 "TstComplThisOpCycle_FAIL" ;
VAL_ 2589283393 DC_MV_Komponentenfehler_28 0 "TstNotComplThisOpCycle_Init" 1 "TstComplThisOpCycle_Pass" 2 "TstCmplThisCycle_Pass_TimeElapse" 3 "TstComplThisOpCycle_FAIL" ;
VAL_ 2589283393 DC_MV_Komponentenfehler_29 0 "TstNotComplThisOpCycle_Init" 1 "TstComplThisOpCycle_Pass" 2 "TstCmplThisCycle_Pass_TimeElapse" 3 "TstComplThisOpCycle_FAIL" ;
VAL_ 2589283393 DC_MV_Komponentenfehler_30 0 "TstNotComplThisOpCycle_Init" 1 "TstComplThisOpCycle_Pass" 2 "TstCmplThisCycle_Pass_TimeElapse" 3 "TstComplThisOpCycle_FAIL" ;
VAL_ 2589283393 DC_MV_Komponentenfehler_31 0 "TstNotComplThisOpCycle_Init" 1 "TstComplThisOpCycle_Pass" 2 "TstCmplThisCycle_Pass_TimeElapse" 3 "TstComplThisOpCycle_FAIL" ;
VAL_ 2589283393 DC_MV_Komponentenfehler_VLD 0 "ungueltig" 1 "gueltig" ;
VAL_ 2589283855 DC_MV_Komponentenfehler_32 0 "TstNotComplThisOpCycle_Init" 1 "TstComplThisOpCycle_Pass" 2 "TstCmplThisCycle_Pass_TimeElapse" 3 "TstComplThisOpCycle_FAIL" ;
VAL_ 2589283855 DC_MV_Komponentenfehler_33 0 "TstNotComplThisOpCycle_Init" 1 "TstComplThisOpCycle_Pass" 2 "TstCmplThisCycle_Pass_TimeElapse" 3 "TstComplThisOpCycle_FAIL" ;
VAL_ 2589283855 DC_MV_Komponentenfehler_34 0 "TstNotComplThisOpCycle_Init" 1 "TstComplThisOpCycle_Pass" 2 "TstCmplThisCycle_Pass_TimeElapse" 3 "TstComplThisOpCycle_FAIL" ;
VAL_ 2589283855 DC_MV_Komponentenfehler_35 0 "TstNotComplThisOpCycle_Init" 1 "TstComplThisOpCycle_Pass" 2 "TstCmplThisCycle_Pass_TimeElapse" 3 "TstComplThisOpCycle_FAIL" ;
VAL_ 2589283855 DC_MV_Komponentenfehler_36 0 "TstNotComplThisOpCycle_Init" 1 "TstComplThisOpCycle_Pass" 2 "TstCmplThisCycle_Pass_TimeElapse" 3 "TstComplThisOpCycle_FAIL" ;
VAL_ 2589283855 DC_MV_Komponentenfehler_37 0 "TstNotComplThisOpCycle_Init" 1 "TstComplThisOpCycle_Pass" 2 "TstCmplThisCycle_Pass_TimeElapse" 3 "TstComplThisOpCycle_FAIL" ;
VAL_ 2589283855 DC_MV_Komponentenfehler_38 0 "TstNotComplThisOpCycle_Init" 1 "TstComplThisOpCycle_Pass" 2 "TstCmplThisCycle_Pass_TimeElapse" 3 "TstComplThisOpCycle_FAIL" ;
VAL_ 2589283855 DC_MV_Komponentenfehler_39 0 "TstNotComplThisOpCycle_Init" 1 "TstComplThisOpCycle_Pass" 2 "TstCmplThisCycle_Pass_TimeElapse" 3 "TstComplThisOpCycle_FAIL" ;
VAL_ 2589283855 DC_MV_Komponentenfehler_40 0 "TstNotComplThisOpCycle_Init" 1 "TstComplThisOpCycle_Pass" 2 "TstCmplThisCycle_Pass_TimeElapse" 3 "TstComplThisOpCycle_FAIL" ;
VAL_ 2589283855 DC_MV_Komponentenfehler_41 0 "TstNotComplThisOpCycle_Init" 1 "TstComplThisOpCycle_Pass" 2 "TstCmplThisCycle_Pass_TimeElapse" 3 "TstComplThisOpCycle_FAIL" ;
VAL_ 2589283855 DC_MV_Komponentenfehler_42 0 "TstNotComplThisOpCycle_Init" 1 "TstComplThisOpCycle_Pass" 2 "TstCmplThisCycle_Pass_TimeElapse" 3 "TstComplThisOpCycle_FAIL" ;
VAL_ 2589283855 DC_MV_Komponentenfehler_43 0 "TstNotComplThisOpCycle_Init" 1 "TstComplThisOpCycle_Pass" 2 "TstCmplThisCycle_Pass_TimeElapse" 3 "TstComplThisOpCycle_FAIL" ;
VAL_ 2589283855 DC_MV_Komponentenfehler_44 0 "TstNotComplThisOpCycle_Init" 1 "TstComplThisOpCycle_Pass" 2 "TstCmplThisCycle_Pass_TimeElapse" 3 "TstComplThisOpCycle_FAIL" ;
VAL_ 2589283855 DC_MV_Komponentenfehler_45 0 "TstNotComplThisOpCycle_Init" 1 "TstComplThisOpCycle_Pass" 2 "TstCmplThisCycle_Pass_TimeElapse" 3 "TstComplThisOpCycle_FAIL" ;
VAL_ 2589283855 DC_MV_Komponentenfehler_46 0 "TstNotComplThisOpCycle_Init" 1 "TstComplThisOpCycle_Pass" 2 "TstCmplThisCycle_Pass_TimeElapse" 3 "TstComplThisOpCycle_FAIL" ;
VAL_ 2589283855 DC_MV_Komponentenfehler_47 0 "TstNotComplThisOpCycle_Init" 1 "TstComplThisOpCycle_Pass" 2 "TstCmplThisCycle_Pass_TimeElapse" 3 "TstComplThisOpCycle_FAIL" ;
VAL_ 2589283855 DC_MV_Komponentenfehler_48 0 "TstNotComplThisOpCycle_Init" 1 "TstComplThisOpCycle_Pass" 2 "TstCmplThisCycle_Pass_TimeElapse" 3 "TstComplThisOpCycle_FAIL" ;
VAL_ 2589283855 DC_MV_Komponentenfehler_49 0 "TstNotComplThisOpCycle_Init" 1 "TstComplThisOpCycle_Pass" 2 "TstCmplThisCycle_Pass_TimeElapse" 3 "TstComplThisOpCycle_FAIL" ;
VAL_ 2589283855 DC_MV_Komponentenfehler_50 0 "TstNotComplThisOpCycle_Init" 1 "TstComplThisOpCycle_Pass" 2 "TstCmplThisCycle_Pass_TimeElapse" 3 "TstComplThisOpCycle_FAIL" ;
VAL_ 2589283855 DC_MV_Komponentenfehler_51 0 "TstNotComplThisOpCycle_Init" 1 "TstComplThisOpCycle_Pass" 2 "TstCmplThisCycle_Pass_TimeElapse" 3 "TstComplThisOpCycle_FAIL" ;
VAL_ 2589283855 DC_MV_Komponentenfehler_52 0 "TstNotComplThisOpCycle_Init" 1 "TstComplThisOpCycle_Pass" 2 "TstCmplThisCycle_Pass_TimeElapse" 3 "TstComplThisOpCycle_FAIL" ;
VAL_ 2589283855 DC_MV_Komponentenfehler_53 0 "TstNotComplThisOpCycle_Init" 1 "TstComplThisOpCycle_Pass" 2 "TstCmplThisCycle_Pass_TimeElapse" 3 "TstComplThisOpCycle_FAIL" ;
VAL_ 2589283855 DC_MV_Komponentenfehler_54 0 "TstNotComplThisOpCycle_Init" 1 "TstComplThisOpCycle_Pass" 2 "TstCmplThisCycle_Pass_TimeElapse" 3 "TstComplThisOpCycle_FAIL" ;
VAL_ 2589283855 DC_MV_Komponentenfehler_55 0 "TstNotComplThisOpCycle_Init" 1 "TstComplThisOpCycle_Pass" 2 "TstCmplThisCycle_Pass_TimeElapse" 3 "TstComplThisOpCycle_FAIL" ;
VAL_ 2589283855 DC_MV_Komponentenfehler_56 0 "TstNotComplThisOpCycle_Init" 1 "TstComplThisOpCycle_Pass" 2 "TstCmplThisCycle_Pass_TimeElapse" 3 "TstComplThisOpCycle_FAIL" ;
VAL_ 2589283855 DC_MV_Komponentenfehler_57 0 "TstNotComplThisOpCycle_Init" 1 "TstComplThisOpCycle_Pass" 2 "TstCmplThisCycle_Pass_TimeElapse" 3 "TstComplThisOpCycle_FAIL" ;
VAL_ 2589283855 DC_MV_Komponentenfehler_58 0 "TstNotComplThisOpCycle_Init" 1 "TstComplThisOpCycle_Pass" 2 "TstCmplThisCycle_Pass_TimeElapse" 3 "TstComplThisOpCycle_FAIL" ;
VAL_ 2589283855 DC_MV_Komponentenfehler_59 0 "TstNotComplThisOpCycle_Init" 1 "TstComplThisOpCycle_Pass" 2 "TstCmplThisCycle_Pass_TimeElapse" 3 "TstComplThisOpCycle_FAIL" ;
VAL_ 2589283855 DC_MV_Komponentenfehler_60 0 "TstNotComplThisOpCycle_Init" 1 "TstComplThisOpCycle_Pass" 2 "TstCmplThisCycle_Pass_TimeElapse" 3 "TstComplThisOpCycle_FAIL" ;
VAL_ 2589283855 DC_MV_Komponentenfehler_61 0 "TstNotComplThisOpCycle_Init" 1 "TstComplThisOpCycle_Pass" 2 "TstCmplThisCycle_Pass_TimeElapse" 3 "TstComplThisOpCycle_FAIL" ;
VAL_ 2589283855 DC_MV_Komponentenfehler_62 0 "TstNotComplThisOpCycle_Init" 1 "TstComplThisOpCycle_Pass" 2 "TstCmplThisCycle_Pass_TimeElapse" 3 "TstComplThisOpCycle_FAIL" ;
